VERSION "AgOpen Rate CAN ECU runtime DBC with S0-S3 banks, 16 nodes"

NS_ :

BS_:

BU_: MASTER TOOL NODE1 NODE2 NODE3 NODE4 NODE5 NODE6 NODE7 NODE8 NODE9 NODE10 NODE11 NODE12 NODE13 NODE14 NODE15 NODE16

VAL_TABLE_ VT_system_mode 0 "OFF" 1 "MANUAL" 2 "AUTO" 3 "CALIBRATION" 4 "FAULT_HOLD";
VAL_TABLE_ VT_node_command 0 "NOP" 1 "ENABLE" 2 "DISABLE" 3 "ZERO_POS" 4 "CLEAR_FAULT";

BO_ 128 S0_GLOBAL_CONTROL: 8 MASTER
 SG_ system_mode : 0|8@1+ (1,0) [0|255] ""  MASTER,TOOL
 SG_ control_flags : 8|8@1+ (1,0) [0|255] "bitfield"  MASTER,TOOL
 SG_ ctrl_drive_enable : 8|1@1+ (1,0) [0|1] "bool"  MASTER,TOOL
 SG_ ctrl_sync_enable : 9|1@1+ (1,0) [0|1] "bool"  MASTER,TOOL
 SG_ ctrl_estop : 10|1@1+ (1,0) [0|1] "bool"  MASTER,TOOL
 SG_ ctrl_diag_enable : 11|1@1+ (1,0) [0|1] "bool"  MASTER,TOOL
 SG_ base_rpm : 16|16@1+ (1,0) [0|10000] "rpm"  MASTER,TOOL
 SG_ sync_pos : 32|16@1+ (1.52587890625e-05,0) [0|0.9999847412109375] "rev"  MASTER,TOOL
 SG_ sequence : 48|8@1+ (1,0) [0|255] ""  MASTER,TOOL
 SG_ reserved : 56|8@1+ (1,0) [0|255] ""  MASTER,TOOL

BO_ 257 S0_NODE_CMD_1: 8 MASTER
 SG_ node_command : 0|8@1+ (1,0) [0|255] ""  MASTER,TOOL
 SG_ node_flags : 8|8@1+ (1,0) [0|255] "bitfield"  MASTER,TOOL
 SG_ trim_rpm : 16|16@1- (0.1,0) [-3276.8|3276.7] "rpm"  MASTER,TOOL
 SG_ section_mask : 32|16@1+ (1,0) [0|65535] "bitmask"  MASTER,TOOL
 SG_ seq : 48|8@1+ (1,0) [0|255] ""  MASTER,TOOL
 SG_ reserved : 56|8@1+ (1,0) [0|255] ""  MASTER,TOOL

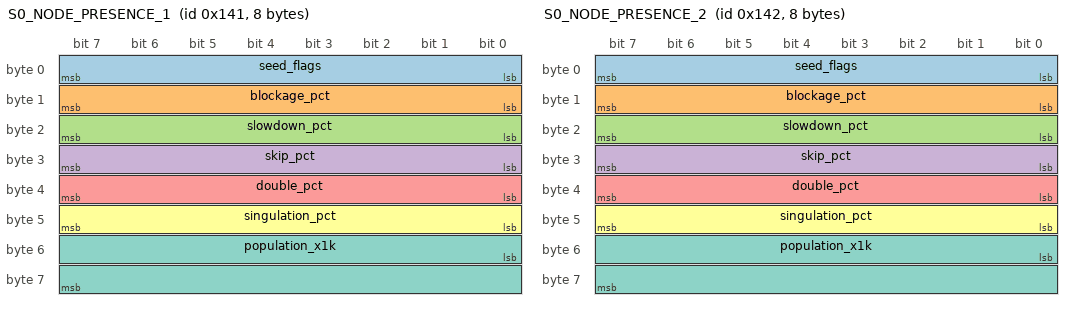
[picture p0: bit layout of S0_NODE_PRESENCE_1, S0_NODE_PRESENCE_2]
BO_ 321 S0_NODE_PRESENCE_1: 8 NODE1
 SG_ seed_flags : 0|8@1+ (1,0) [0|255] "bitfield"  NODE1,MASTER,TOOL
 SG_ blockage_pct : 8|8@1+ (1,0) [0|100] "%"  NODE1,MASTER,TOOL
 SG_ slowdown_pct : 16|8@1+ (1,0) [0|100] "%"  NODE1,MASTER,TOOL
 SG_ skip_pct : 24|8@1+ (1,0) [0|100] "%"  NODE1,MASTER,TOOL
 SG_ double_pct : 32|8@1+ (1,0) [0|100] "%"  NODE1,MASTER,TOOL
 SG_ singulation_pct : 40|8@1+ (1,0) [0|100] "%"  NODE1,MASTER,TOOL
 SG_ population_x1k : 48|16@1+ (1,0) [0|65535] "x1000"  NODE1,MASTER,TOOL

BO_ 385 S0_NODE_STATUS_FAST_1: 8 NODE1
 SG_ status_flags : 0|8@1+ (1,0) [0|255] "bitfield"  NODE1,MASTER,TOOL
 SG_ error_code : 8|8@1+ (1,0) [0|255] ""  NODE1,MASTER,TOOL
 SG_ actual_rpm : 16|16@1+ (1,0) [0|10000] "rpm"  NODE1,MASTER,TOOL
 SG_ actual_pos : 32|16@1+ (1.52587890625e-05,0) [0|0.9999847412109375] "rev"  NODE1,MASTER,TOOL
 SG_ alive_counter : 48|8@1+ (1,0) [0|255] ""  NODE1,MASTER,TOOL
 SG_ sync_error : 56|8@1- (0.00390625,0) [-0.5|0.49609375] "rev"  NODE1,MASTER,TOOL

BO_ 449 S0_NODE_DIAG_1: 8 NODE1
 SG_ bus_voltage : 0|16@1+ (0.1,0) [0|6553.5] "V"  NODE1,MASTER,TOOL
 SG_ motor_current : 16|16@1- (0.1,0) [-3276.8|3276.7] "A"  NODE1,MASTER,TOOL
 SG_ controller_temp : 32|8@1+ (1,0) [0|255] "C"  NODE1,MASTER,TOOL
 SG_ motor_temp : 40|8@1+ (1,0) [0|255] "C"  NODE1,MASTER,TOOL
 SG_ fault_flags : 48|8@1+ (1,0) [0|255] "bitfield"  NODE1,MASTER,TOOL
 SG_ warning_flags : 56|8@1+ (1,0) [0|255] "bitfield"  NODE1,MASTER,TOOL

BO_ 258 S0_NODE_CMD_2: 8 MASTER
 SG_ node_command : 0|8@1+ (1,0) [0|255] ""  MASTER,TOOL
 SG_ node_flags : 8|8@1+ (1,0) [0|255] "bitfield"  MASTER,TOOL
 SG_ trim_rpm : 16|16@1- (0.1,0) [-3276.8|3276.7] "rpm"  MASTER,TOOL
 SG_ section_mask : 32|16@1+ (1,0) [0|65535] "bitmask"  MASTER,TOOL
 SG_ seq : 48|8@1+ (1,0) [0|255] ""  MASTER,TOOL
 SG_ reserved : 56|8@1+ (1,0) [0|255] ""  MASTER,TOOL

BO_ 322 S0_NODE_PRESENCE_2: 8 NODE2
 SG_ seed_flags : 0|8@1+ (1,0) [0|255] "bitfield"  NODE2,MASTER,TOOL
 SG_ blockage_pct : 8|8@1+ (1,0) [0|100] "%"  NODE2,MASTER,TOOL
 SG_ slowdown_pct : 16|8@1+ (1,0) [0|100] "%"  NODE2,MASTER,TOOL
 SG_ skip_pct : 24|8@1+ (1,0) [0|100] "%"  NODE2,MASTER,TOOL
 SG_ double_pct : 32|8@1+ (1,0) [0|100] "%"  NODE2,MASTER,TOOL
 SG_ singulation_pct : 40|8@1+ (1,0) [0|100] "%"  NODE2,MASTER,TOOL
 SG_ population_x1k : 48|16@1+ (1,0) [0|65535] "x1000"  NODE2,MASTER,TOOL

BO_ 386 S0_NODE_STATUS_FAST_2: 8 NODE2
 SG_ status_flags : 0|8@1+ (1,0) [0|255] "bitfield"  NODE2,MASTER,TOOL
 SG_ error_code : 8|8@1+ (1,0) [0|255] ""  NODE2,MASTER,TOOL
 SG_ actual_rpm : 16|16@1+ (1,0) [0|10000] "rpm"  NODE2,MASTER,TOOL
 SG_ actual_pos : 32|16@1+ (1.52587890625e-05,0) [0|0.9999847412109375] "rev"  NODE2,MASTER,TOOL
 SG_ alive_counter : 48|8@1+ (1,0) [0|255] ""  NODE2,MASTER,TOOL
 SG_ sync_error : 56|8@1- (0.00390625,0) [-0.5|0.49609375] "rev"  NODE2,MASTER,TOOL

BO_ 450 S0_NODE_DIAG_2: 8 NODE2
 SG_ bus_voltage : 0|16@1+ (0.1,0) [0|6553.5] "V"  NODE2,MASTER,TOOL
 SG_ motor_current : 16|16@1- (0.1,0) [-3276.8|3276.7] "A"  NODE2,MASTER,TOOL
 SG_ controller_temp : 32|8@1+ (1,0) [0|255] "C"  NODE2,MASTER,TOOL
 SG_ motor_temp : 40|8@1+ (1,0) [0|255] "C"  NODE2,MASTER,TOOL
 SG_ fault_flags : 48|8@1+ (1,0) [0|255] "bitfield"  NODE2,MASTER,TOOL
 SG_ warning_flags : 56|8@1+ (1,0) [0|255] "bitfield"  NODE2,MASTER,TOOL

BO_ 259 S0_NODE_CMD_3: 8 MASTER
 SG_ node_command : 0|8@1+ (1,0) [0|255] ""  MASTER,TOOL
 SG_ node_flags : 8|8@1+ (1,0) [0|255] "bitfield"  MASTER,TOOL
 SG_ trim_rpm : 16|16@1- (0.1,0) [-3276.8|3276.7] "rpm"  MASTER,TOOL
 SG_ section_mask : 32|16@1+ (1,0) [0|65535] "bitmask"  MASTER,TOOL
 SG_ seq : 48|8@1+ (1,0) [0|255] ""  MASTER,TOOL
 SG_ reserved : 56|8@1+ (1,0) [0|255] ""  MASTER,TOOL

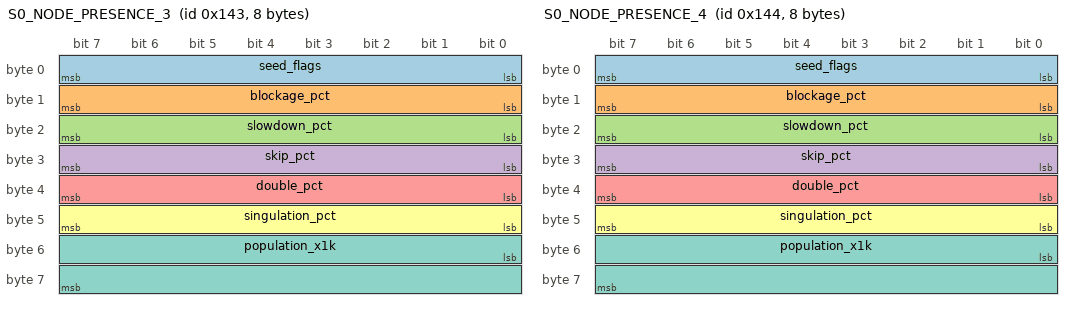
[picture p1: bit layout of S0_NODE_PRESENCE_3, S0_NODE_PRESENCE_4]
BO_ 323 S0_NODE_PRESENCE_3: 8 NODE3
 SG_ seed_flags : 0|8@1+ (1,0) [0|255] "bitfield"  NODE3,MASTER,TOOL
 SG_ blockage_pct : 8|8@1+ (1,0) [0|100] "%"  NODE3,MASTER,TOOL
 SG_ slowdown_pct : 16|8@1+ (1,0) [0|100] "%"  NODE3,MASTER,TOOL
 SG_ skip_pct : 24|8@1+ (1,0) [0|100] "%"  NODE3,MASTER,TOOL
 SG_ double_pct : 32|8@1+ (1,0) [0|100] "%"  NODE3,MASTER,TOOL
 SG_ singulation_pct : 40|8@1+ (1,0) [0|100] "%"  NODE3,MASTER,TOOL
 SG_ population_x1k : 48|16@1+ (1,0) [0|65535] "x1000"  NODE3,MASTER,TOOL

BO_ 387 S0_NODE_STATUS_FAST_3: 8 NODE3
 SG_ status_flags : 0|8@1+ (1,0) [0|255] "bitfield"  NODE3,MASTER,TOOL
 SG_ error_code : 8|8@1+ (1,0) [0|255] ""  NODE3,MASTER,TOOL
 SG_ actual_rpm : 16|16@1+ (1,0) [0|10000] "rpm"  NODE3,MASTER,TOOL
 SG_ actual_pos : 32|16@1+ (1.52587890625e-05,0) [0|0.9999847412109375] "rev"  NODE3,MASTER,TOOL
 SG_ alive_counter : 48|8@1+ (1,0) [0|255] ""  NODE3,MASTER,TOOL
 SG_ sync_error : 56|8@1- (0.00390625,0) [-0.5|0.49609375] "rev"  NODE3,MASTER,TOOL

BO_ 451 S0_NODE_DIAG_3: 8 NODE3
 SG_ bus_voltage : 0|16@1+ (0.1,0) [0|6553.5] "V"  NODE3,MASTER,TOOL
 SG_ motor_current : 16|16@1- (0.1,0) [-3276.8|3276.7] "A"  NODE3,MASTER,TOOL
 SG_ controller_temp : 32|8@1+ (1,0) [0|255] "C"  NODE3,MASTER,TOOL
 SG_ motor_temp : 40|8@1+ (1,0) [0|255] "C"  NODE3,MASTER,TOOL
 SG_ fault_flags : 48|8@1+ (1,0) [0|255] "bitfield"  NODE3,MASTER,TOOL
 SG_ warning_flags : 56|8@1+ (1,0) [0|255] "bitfield"  NODE3,MASTER,TOOL

BO_ 260 S0_NODE_CMD_4: 8 MASTER
 SG_ node_command : 0|8@1+ (1,0) [0|255] ""  MASTER,TOOL
 SG_ node_flags : 8|8@1+ (1,0) [0|255] "bitfield"  MASTER,TOOL
 SG_ trim_rpm : 16|16@1- (0.1,0) [-3276.8|3276.7] "rpm"  MASTER,TOOL
 SG_ section_mask : 32|16@1+ (1,0) [0|65535] "bitmask"  MASTER,TOOL
 SG_ seq : 48|8@1+ (1,0) [0|255] ""  MASTER,TOOL
 SG_ reserved : 56|8@1+ (1,0) [0|255] ""  MASTER,TOOL

BO_ 324 S0_NODE_PRESENCE_4: 8 NODE4
 SG_ seed_flags : 0|8@1+ (1,0) [0|255] "bitfield"  NODE4,MASTER,TOOL
 SG_ blockage_pct : 8|8@1+ (1,0) [0|100] "%"  NODE4,MASTER,TOOL
 SG_ slowdown_pct : 16|8@1+ (1,0) [0|100] "%"  NODE4,MASTER,TOOL
 SG_ skip_pct : 24|8@1+ (1,0) [0|100] "%"  NODE4,MASTER,TOOL
 SG_ double_pct : 32|8@1+ (1,0) [0|100] "%"  NODE4,MASTER,TOOL
 SG_ singulation_pct : 40|8@1+ (1,0) [0|100] "%"  NODE4,MASTER,TOOL
 SG_ population_x1k : 48|16@1+ (1,0) [0|65535] "x1000"  NODE4,MASTER,TOOL

BO_ 388 S0_NODE_STATUS_FAST_4: 8 NODE4
 SG_ status_flags : 0|8@1+ (1,0) [0|255] "bitfield"  NODE4,MASTER,TOOL
 SG_ error_code : 8|8@1+ (1,0) [0|255] ""  NODE4,MASTER,TOOL
 SG_ actual_rpm : 16|16@1+ (1,0) [0|10000] "rpm"  NODE4,MASTER,TOOL
 SG_ actual_pos : 32|16@1+ (1.52587890625e-05,0) [0|0.9999847412109375] "rev"  NODE4,MASTER,TOOL
 SG_ alive_counter : 48|8@1+ (1,0) [0|255] ""  NODE4,MASTER,TOOL
 SG_ sync_error : 56|8@1- (0.00390625,0) [-0.5|0.49609375] "rev"  NODE4,MASTER,TOOL

BO_ 452 S0_NODE_DIAG_4: 8 NODE4
 SG_ bus_voltage : 0|16@1+ (0.1,0) [0|6553.5] "V"  NODE4,MASTER,TOOL
 SG_ motor_current : 16|16@1- (0.1,0) [-3276.8|3276.7] "A"  NODE4,MASTER,TOOL
 SG_ controller_temp : 32|8@1+ (1,0) [0|255] "C"  NODE4,MASTER,TOOL
 SG_ motor_temp : 40|8@1+ (1,0) [0|255] "C"  NODE4,MASTER,TOOL
 SG_ fault_flags : 48|8@1+ (1,0) [0|255] "bitfield"  NODE4,MASTER,TOOL
 SG_ warning_flags : 56|8@1+ (1,0) [0|255] "bitfield"  NODE4,MASTER,TOOL

BO_ 261 S0_NODE_CMD_5: 8 MASTER
 SG_ node_command : 0|8@1+ (1,0) [0|255] ""  MASTER,TOOL
 SG_ node_flags : 8|8@1+ (1,0) [0|255] "bitfield"  MASTER,TOOL
 SG_ trim_rpm : 16|16@1- (0.1,0) [-3276.8|3276.7] "rpm"  MASTER,TOOL
 SG_ section_mask : 32|16@1+ (1,0) [0|65535] "bitmask"  MASTER,TOOL
 SG_ seq : 48|8@1+ (1,0) [0|255] ""  MASTER,TOOL
 SG_ reserved : 56|8@1+ (1,0) [0|255] ""  MASTER,TOOL

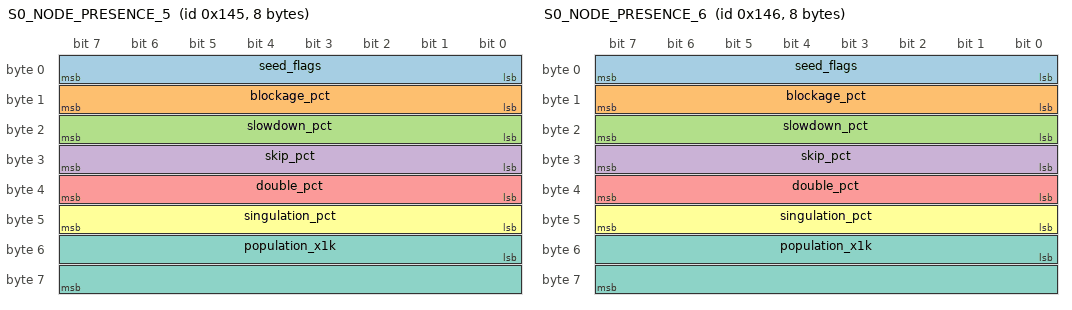
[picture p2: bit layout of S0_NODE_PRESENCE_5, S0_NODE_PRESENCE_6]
BO_ 325 S0_NODE_PRESENCE_5: 8 NODE5
 SG_ seed_flags : 0|8@1+ (1,0) [0|255] "bitfield"  NODE5,MASTER,TOOL
 SG_ blockage_pct : 8|8@1+ (1,0) [0|100] "%"  NODE5,MASTER,TOOL
 SG_ slowdown_pct : 16|8@1+ (1,0) [0|100] "%"  NODE5,MASTER,TOOL
 SG_ skip_pct : 24|8@1+ (1,0) [0|100] "%"  NODE5,MASTER,TOOL
 SG_ double_pct : 32|8@1+ (1,0) [0|100] "%"  NODE5,MASTER,TOOL
 SG_ singulation_pct : 40|8@1+ (1,0) [0|100] "%"  NODE5,MASTER,TOOL
 SG_ population_x1k : 48|16@1+ (1,0) [0|65535] "x1000"  NODE5,MASTER,TOOL

BO_ 389 S0_NODE_STATUS_FAST_5: 8 NODE5
 SG_ status_flags : 0|8@1+ (1,0) [0|255] "bitfield"  NODE5,MASTER,TOOL
 SG_ error_code : 8|8@1+ (1,0) [0|255] ""  NODE5,MASTER,TOOL
 SG_ actual_rpm : 16|16@1+ (1,0) [0|10000] "rpm"  NODE5,MASTER,TOOL
 SG_ actual_pos : 32|16@1+ (1.52587890625e-05,0) [0|0.9999847412109375] "rev"  NODE5,MASTER,TOOL
 SG_ alive_counter : 48|8@1+ (1,0) [0|255] ""  NODE5,MASTER,TOOL
 SG_ sync_error : 56|8@1- (0.00390625,0) [-0.5|0.49609375] "rev"  NODE5,MASTER,TOOL

BO_ 453 S0_NODE_DIAG_5: 8 NODE5
 SG_ bus_voltage : 0|16@1+ (0.1,0) [0|6553.5] "V"  NODE5,MASTER,TOOL
 SG_ motor_current : 16|16@1- (0.1,0) [-3276.8|3276.7] "A"  NODE5,MASTER,TOOL
 SG_ controller_temp : 32|8@1+ (1,0) [0|255] "C"  NODE5,MASTER,TOOL
 SG_ motor_temp : 40|8@1+ (1,0) [0|255] "C"  NODE5,MASTER,TOOL
 SG_ fault_flags : 48|8@1+ (1,0) [0|255] "bitfield"  NODE5,MASTER,TOOL
 SG_ warning_flags : 56|8@1+ (1,0) [0|255] "bitfield"  NODE5,MASTER,TOOL

BO_ 262 S0_NODE_CMD_6: 8 MASTER
 SG_ node_command : 0|8@1+ (1,0) [0|255] ""  MASTER,TOOL
 SG_ node_flags : 8|8@1+ (1,0) [0|255] "bitfield"  MASTER,TOOL
 SG_ trim_rpm : 16|16@1- (0.1,0) [-3276.8|3276.7] "rpm"  MASTER,TOOL
 SG_ section_mask : 32|16@1+ (1,0) [0|65535] "bitmask"  MASTER,TOOL
 SG_ seq : 48|8@1+ (1,0) [0|255] ""  MASTER,TOOL
 SG_ reserved : 56|8@1+ (1,0) [0|255] ""  MASTER,TOOL

BO_ 326 S0_NODE_PRESENCE_6: 8 NODE6
 SG_ seed_flags : 0|8@1+ (1,0) [0|255] "bitfield"  NODE6,MASTER,TOOL
 SG_ blockage_pct : 8|8@1+ (1,0) [0|100] "%"  NODE6,MASTER,TOOL
 SG_ slowdown_pct : 16|8@1+ (1,0) [0|100] "%"  NODE6,MASTER,TOOL
 SG_ skip_pct : 24|8@1+ (1,0) [0|100] "%"  NODE6,MASTER,TOOL
 SG_ double_pct : 32|8@1+ (1,0) [0|100] "%"  NODE6,MASTER,TOOL
 SG_ singulation_pct : 40|8@1+ (1,0) [0|100] "%"  NODE6,MASTER,TOOL
 SG_ population_x1k : 48|16@1+ (1,0) [0|65535] "x1000"  NODE6,MASTER,TOOL

BO_ 390 S0_NODE_STATUS_FAST_6: 8 NODE6
 SG_ status_flags : 0|8@1+ (1,0) [0|255] "bitfield"  NODE6,MASTER,TOOL
 SG_ error_code : 8|8@1+ (1,0) [0|255] ""  NODE6,MASTER,TOOL
 SG_ actual_rpm : 16|16@1+ (1,0) [0|10000] "rpm"  NODE6,MASTER,TOOL
 SG_ actual_pos : 32|16@1+ (1.52587890625e-05,0) [0|0.9999847412109375] "rev"  NODE6,MASTER,TOOL
 SG_ alive_counter : 48|8@1+ (1,0) [0|255] ""  NODE6,MASTER,TOOL
 SG_ sync_error : 56|8@1- (0.00390625,0) [-0.5|0.49609375] "rev"  NODE6,MASTER,TOOL

BO_ 454 S0_NODE_DIAG_6: 8 NODE6
 SG_ bus_voltage : 0|16@1+ (0.1,0) [0|6553.5] "V"  NODE6,MASTER,TOOL
 SG_ motor_current : 16|16@1- (0.1,0) [-3276.8|3276.7] "A"  NODE6,MASTER,TOOL
 SG_ controller_temp : 32|8@1+ (1,0) [0|255] "C"  NODE6,MASTER,TOOL
 SG_ motor_temp : 40|8@1+ (1,0) [0|255] "C"  NODE6,MASTER,TOOL
 SG_ fault_flags : 48|8@1+ (1,0) [0|255] "bitfield"  NODE6,MASTER,TOOL
 SG_ warning_flags : 56|8@1+ (1,0) [0|255] "bitfield"  NODE6,MASTER,TOOL

BO_ 263 S0_NODE_CMD_7: 8 MASTER
 SG_ node_command : 0|8@1+ (1,0) [0|255] ""  MASTER,TOOL
 SG_ node_flags : 8|8@1+ (1,0) [0|255] "bitfield"  MASTER,TOOL
 SG_ trim_rpm : 16|16@1- (0.1,0) [-3276.8|3276.7] "rpm"  MASTER,TOOL
 SG_ section_mask : 32|16@1+ (1,0) [0|65535] "bitmask"  MASTER,TOOL
 SG_ seq : 48|8@1+ (1,0) [0|255] ""  MASTER,TOOL
 SG_ reserved : 56|8@1+ (1,0) [0|255] ""  MASTER,TOOL

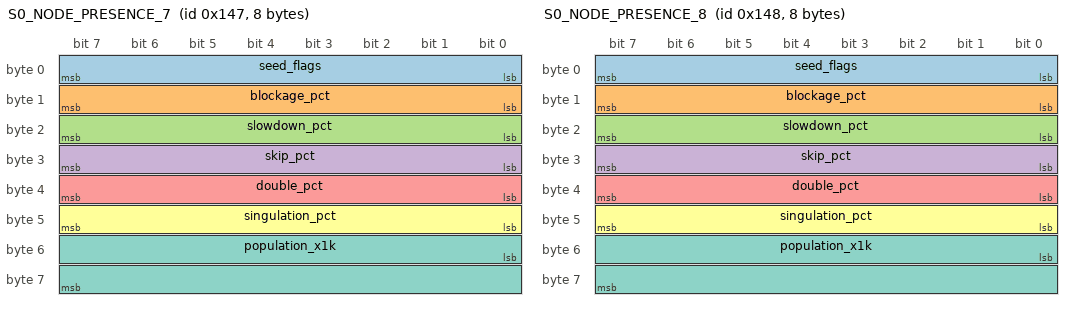
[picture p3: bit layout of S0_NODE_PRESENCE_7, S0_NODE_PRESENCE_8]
BO_ 327 S0_NODE_PRESENCE_7: 8 NODE7
 SG_ seed_flags : 0|8@1+ (1,0) [0|255] "bitfield"  NODE7,MASTER,TOOL
 SG_ blockage_pct : 8|8@1+ (1,0) [0|100] "%"  NODE7,MASTER,TOOL
 SG_ slowdown_pct : 16|8@1+ (1,0) [0|100] "%"  NODE7,MASTER,TOOL
 SG_ skip_pct : 24|8@1+ (1,0) [0|100] "%"  NODE7,MASTER,TOOL
 SG_ double_pct : 32|8@1+ (1,0) [0|100] "%"  NODE7,MASTER,TOOL
 SG_ singulation_pct : 40|8@1+ (1,0) [0|100] "%"  NODE7,MASTER,TOOL
 SG_ population_x1k : 48|16@1+ (1,0) [0|65535] "x1000"  NODE7,MASTER,TOOL

BO_ 391 S0_NODE_STATUS_FAST_7: 8 NODE7
 SG_ status_flags : 0|8@1+ (1,0) [0|255] "bitfield"  NODE7,MASTER,TOOL
 SG_ error_code : 8|8@1+ (1,0) [0|255] ""  NODE7,MASTER,TOOL
 SG_ actual_rpm : 16|16@1+ (1,0) [0|10000] "rpm"  NODE7,MASTER,TOOL
 SG_ actual_pos : 32|16@1+ (1.52587890625e-05,0) [0|0.9999847412109375] "rev"  NODE7,MASTER,TOOL
 SG_ alive_counter : 48|8@1+ (1,0) [0|255] ""  NODE7,MASTER,TOOL
 SG_ sync_error : 56|8@1- (0.00390625,0) [-0.5|0.49609375] "rev"  NODE7,MASTER,TOOL

BO_ 455 S0_NODE_DIAG_7: 8 NODE7
 SG_ bus_voltage : 0|16@1+ (0.1,0) [0|6553.5] "V"  NODE7,MASTER,TOOL
 SG_ motor_current : 16|16@1- (0.1,0) [-3276.8|3276.7] "A"  NODE7,MASTER,TOOL
 SG_ controller_temp : 32|8@1+ (1,0) [0|255] "C"  NODE7,MASTER,TOOL
 SG_ motor_temp : 40|8@1+ (1,0) [0|255] "C"  NODE7,MASTER,TOOL
 SG_ fault_flags : 48|8@1+ (1,0) [0|255] "bitfield"  NODE7,MASTER,TOOL
 SG_ warning_flags : 56|8@1+ (1,0) [0|255] "bitfield"  NODE7,MASTER,TOOL

BO_ 264 S0_NODE_CMD_8: 8 MASTER
 SG_ node_command : 0|8@1+ (1,0) [0|255] ""  MASTER,TOOL
 SG_ node_flags : 8|8@1+ (1,0) [0|255] "bitfield"  MASTER,TOOL
 SG_ trim_rpm : 16|16@1- (0.1,0) [-3276.8|3276.7] "rpm"  MASTER,TOOL
 SG_ section_mask : 32|16@1+ (1,0) [0|65535] "bitmask"  MASTER,TOOL
 SG_ seq : 48|8@1+ (1,0) [0|255] ""  MASTER,TOOL
 SG_ reserved : 56|8@1+ (1,0) [0|255] ""  MASTER,TOOL

BO_ 328 S0_NODE_PRESENCE_8: 8 NODE8
 SG_ seed_flags : 0|8@1+ (1,0) [0|255] "bitfield"  NODE8,MASTER,TOOL
 SG_ blockage_pct : 8|8@1+ (1,0) [0|100] "%"  NODE8,MASTER,TOOL
 SG_ slowdown_pct : 16|8@1+ (1,0) [0|100] "%"  NODE8,MASTER,TOOL
 SG_ skip_pct : 24|8@1+ (1,0) [0|100] "%"  NODE8,MASTER,TOOL
 SG_ double_pct : 32|8@1+ (1,0) [0|100] "%"  NODE8,MASTER,TOOL
 SG_ singulation_pct : 40|8@1+ (1,0) [0|100] "%"  NODE8,MASTER,TOOL
 SG_ population_x1k : 48|16@1+ (1,0) [0|65535] "x1000"  NODE8,MASTER,TOOL

BO_ 392 S0_NODE_STATUS_FAST_8: 8 NODE8
 SG_ status_flags : 0|8@1+ (1,0) [0|255] "bitfield"  NODE8,MASTER,TOOL
 SG_ error_code : 8|8@1+ (1,0) [0|255] ""  NODE8,MASTER,TOOL
 SG_ actual_rpm : 16|16@1+ (1,0) [0|10000] "rpm"  NODE8,MASTER,TOOL
 SG_ actual_pos : 32|16@1+ (1.52587890625e-05,0) [0|0.9999847412109375] "rev"  NODE8,MASTER,TOOL
 SG_ alive_counter : 48|8@1+ (1,0) [0|255] ""  NODE8,MASTER,TOOL
 SG_ sync_error : 56|8@1- (0.00390625,0) [-0.5|0.49609375] "rev"  NODE8,MASTER,TOOL

BO_ 456 S0_NODE_DIAG_8: 8 NODE8
 SG_ bus_voltage : 0|16@1+ (0.1,0) [0|6553.5] "V"  NODE8,MASTER,TOOL
 SG_ motor_current : 16|16@1- (0.1,0) [-3276.8|3276.7] "A"  NODE8,MASTER,TOOL
 SG_ controller_temp : 32|8@1+ (1,0) [0|255] "C"  NODE8,MASTER,TOOL
 SG_ motor_temp : 40|8@1+ (1,0) [0|255] "C"  NODE8,MASTER,TOOL
 SG_ fault_flags : 48|8@1+ (1,0) [0|255] "bitfield"  NODE8,MASTER,TOOL
 SG_ warning_flags : 56|8@1+ (1,0) [0|255] "bitfield"  NODE8,MASTER,TOOL

BO_ 265 S0_NODE_CMD_9: 8 MASTER
 SG_ node_command : 0|8@1+ (1,0) [0|255] ""  MASTER,TOOL
 SG_ node_flags : 8|8@1+ (1,0) [0|255] "bitfield"  MASTER,TOOL
 SG_ trim_rpm : 16|16@1- (0.1,0) [-3276.8|3276.7] "rpm"  MASTER,TOOL
 SG_ section_mask : 32|16@1+ (1,0) [0|65535] "bitmask"  MASTER,TOOL
 SG_ seq : 48|8@1+ (1,0) [0|255] ""  MASTER,TOOL
 SG_ reserved : 56|8@1+ (1,0) [0|255] ""  MASTER,TOOL

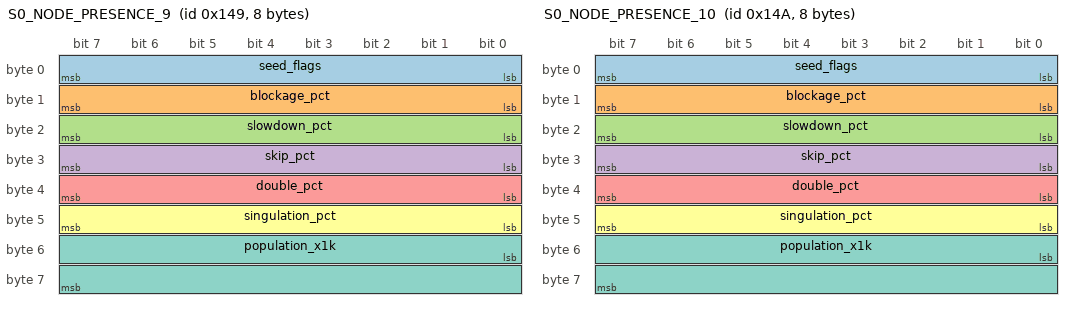
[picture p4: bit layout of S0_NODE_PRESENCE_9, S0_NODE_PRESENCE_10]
BO_ 329 S0_NODE_PRESENCE_9: 8 NODE9
 SG_ seed_flags : 0|8@1+ (1,0) [0|255] "bitfield"  NODE9,MASTER,TOOL
 SG_ blockage_pct : 8|8@1+ (1,0) [0|100] "%"  NODE9,MASTER,TOOL
 SG_ slowdown_pct : 16|8@1+ (1,0) [0|100] "%"  NODE9,MASTER,TOOL
 SG_ skip_pct : 24|8@1+ (1,0) [0|100] "%"  NODE9,MASTER,TOOL
 SG_ double_pct : 32|8@1+ (1,0) [0|100] "%"  NODE9,MASTER,TOOL
 SG_ singulation_pct : 40|8@1+ (1,0) [0|100] "%"  NODE9,MASTER,TOOL
 SG_ population_x1k : 48|16@1+ (1,0) [0|65535] "x1000"  NODE9,MASTER,TOOL

BO_ 393 S0_NODE_STATUS_FAST_9: 8 NODE9
 SG_ status_flags : 0|8@1+ (1,0) [0|255] "bitfield"  NODE9,MASTER,TOOL
 SG_ error_code : 8|8@1+ (1,0) [0|255] ""  NODE9,MASTER,TOOL
 SG_ actual_rpm : 16|16@1+ (1,0) [0|10000] "rpm"  NODE9,MASTER,TOOL
 SG_ actual_pos : 32|16@1+ (1.52587890625e-05,0) [0|0.9999847412109375] "rev"  NODE9,MASTER,TOOL
 SG_ alive_counter : 48|8@1+ (1,0) [0|255] ""  NODE9,MASTER,TOOL
 SG_ sync_error : 56|8@1- (0.00390625,0) [-0.5|0.49609375] "rev"  NODE9,MASTER,TOOL

BO_ 457 S0_NODE_DIAG_9: 8 NODE9
 SG_ bus_voltage : 0|16@1+ (0.1,0) [0|6553.5] "V"  NODE9,MASTER,TOOL
 SG_ motor_current : 16|16@1- (0.1,0) [-3276.8|3276.7] "A"  NODE9,MASTER,TOOL
 SG_ controller_temp : 32|8@1+ (1,0) [0|255] "C"  NODE9,MASTER,TOOL
 SG_ motor_temp : 40|8@1+ (1,0) [0|255] "C"  NODE9,MASTER,TOOL
 SG_ fault_flags : 48|8@1+ (1,0) [0|255] "bitfield"  NODE9,MASTER,TOOL
 SG_ warning_flags : 56|8@1+ (1,0) [0|255] "bitfield"  NODE9,MASTER,TOOL

BO_ 266 S0_NODE_CMD_10: 8 MASTER
 SG_ node_command : 0|8@1+ (1,0) [0|255] ""  MASTER,TOOL
 SG_ node_flags : 8|8@1+ (1,0) [0|255] "bitfield"  MASTER,TOOL
 SG_ trim_rpm : 16|16@1- (0.1,0) [-3276.8|3276.7] "rpm"  MASTER,TOOL
 SG_ section_mask : 32|16@1+ (1,0) [0|65535] "bitmask"  MASTER,TOOL
 SG_ seq : 48|8@1+ (1,0) [0|255] ""  MASTER,TOOL
 SG_ reserved : 56|8@1+ (1,0) [0|255] ""  MASTER,TOOL

BO_ 330 S0_NODE_PRESENCE_10: 8 NODE10
 SG_ seed_flags : 0|8@1+ (1,0) [0|255] "bitfield"  NODE10,MASTER,TOOL
 SG_ blockage_pct : 8|8@1+ (1,0) [0|100] "%"  NODE10,MASTER,TOOL
 SG_ slowdown_pct : 16|8@1+ (1,0) [0|100] "%"  NODE10,MASTER,TOOL
 SG_ skip_pct : 24|8@1+ (1,0) [0|100] "%"  NODE10,MASTER,TOOL
 SG_ double_pct : 32|8@1+ (1,0) [0|100] "%"  NODE10,MASTER,TOOL
 SG_ singulation_pct : 40|8@1+ (1,0) [0|100] "%"  NODE10,MASTER,TOOL
 SG_ population_x1k : 48|16@1+ (1,0) [0|65535] "x1000"  NODE10,MASTER,TOOL

BO_ 394 S0_NODE_STATUS_FAST_10: 8 NODE10
 SG_ status_flags : 0|8@1+ (1,0) [0|255] "bitfield"  NODE10,MASTER,TOOL
 SG_ error_code : 8|8@1+ (1,0) [0|255] ""  NODE10,MASTER,TOOL
 SG_ actual_rpm : 16|16@1+ (1,0) [0|10000] "rpm"  NODE10,MASTER,TOOL
 SG_ actual_pos : 32|16@1+ (1.52587890625e-05,0) [0|0.9999847412109375] "rev"  NODE10,MASTER,TOOL
 SG_ alive_counter : 48|8@1+ (1,0) [0|255] ""  NODE10,MASTER,TOOL
 SG_ sync_error : 56|8@1- (0.00390625,0) [-0.5|0.49609375] "rev"  NODE10,MASTER,TOOL

BO_ 458 S0_NODE_DIAG_10: 8 NODE10
 SG_ bus_voltage : 0|16@1+ (0.1,0) [0|6553.5] "V"  NODE10,MASTER,TOOL
 SG_ motor_current : 16|16@1- (0.1,0) [-3276.8|3276.7] "A"  NODE10,MASTER,TOOL
 SG_ controller_temp : 32|8@1+ (1,0) [0|255] "C"  NODE10,MASTER,TOOL
 SG_ motor_temp : 40|8@1+ (1,0) [0|255] "C"  NODE10,MASTER,TOOL
 SG_ fault_flags : 48|8@1+ (1,0) [0|255] "bitfield"  NODE10,MASTER,TOOL
 SG_ warning_flags : 56|8@1+ (1,0) [0|255] "bitfield"  NODE10,MASTER,TOOL

BO_ 267 S0_NODE_CMD_11: 8 MASTER
 SG_ node_command : 0|8@1+ (1,0) [0|255] ""  MASTER,TOOL
 SG_ node_flags : 8|8@1+ (1,0) [0|255] "bitfield"  MASTER,TOOL
 SG_ trim_rpm : 16|16@1- (0.1,0) [-3276.8|3276.7] "rpm"  MASTER,TOOL
 SG_ section_mask : 32|16@1+ (1,0) [0|65535] "bitmask"  MASTER,TOOL
 SG_ seq : 48|8@1+ (1,0) [0|255] ""  MASTER,TOOL
 SG_ reserved : 56|8@1+ (1,0) [0|255] ""  MASTER,TOOL

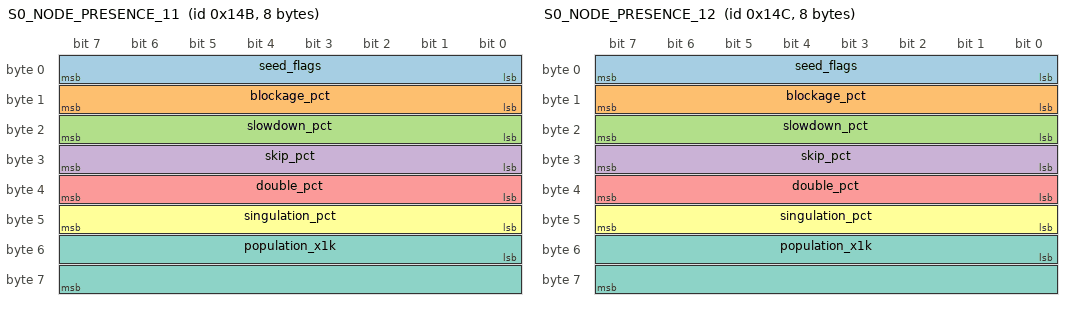
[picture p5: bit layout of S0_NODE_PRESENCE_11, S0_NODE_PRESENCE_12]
BO_ 331 S0_NODE_PRESENCE_11: 8 NODE11
 SG_ seed_flags : 0|8@1+ (1,0) [0|255] "bitfield"  NODE11,MASTER,TOOL
 SG_ blockage_pct : 8|8@1+ (1,0) [0|100] "%"  NODE11,MASTER,TOOL
 SG_ slowdown_pct : 16|8@1+ (1,0) [0|100] "%"  NODE11,MASTER,TOOL
 SG_ skip_pct : 24|8@1+ (1,0) [0|100] "%"  NODE11,MASTER,TOOL
 SG_ double_pct : 32|8@1+ (1,0) [0|100] "%"  NODE11,MASTER,TOOL
 SG_ singulation_pct : 40|8@1+ (1,0) [0|100] "%"  NODE11,MASTER,TOOL
 SG_ population_x1k : 48|16@1+ (1,0) [0|65535] "x1000"  NODE11,MASTER,TOOL

BO_ 395 S0_NODE_STATUS_FAST_11: 8 NODE11
 SG_ status_flags : 0|8@1+ (1,0) [0|255] "bitfield"  NODE11,MASTER,TOOL
 SG_ error_code : 8|8@1+ (1,0) [0|255] ""  NODE11,MASTER,TOOL
 SG_ actual_rpm : 16|16@1+ (1,0) [0|10000] "rpm"  NODE11,MASTER,TOOL
 SG_ actual_pos : 32|16@1+ (1.52587890625e-05,0) [0|0.9999847412109375] "rev"  NODE11,MASTER,TOOL
 SG_ alive_counter : 48|8@1+ (1,0) [0|255] ""  NODE11,MASTER,TOOL
 SG_ sync_error : 56|8@1- (0.00390625,0) [-0.5|0.49609375] "rev"  NODE11,MASTER,TOOL

BO_ 459 S0_NODE_DIAG_11: 8 NODE11
 SG_ bus_voltage : 0|16@1+ (0.1,0) [0|6553.5] "V"  NODE11,MASTER,TOOL
 SG_ motor_current : 16|16@1- (0.1,0) [-3276.8|3276.7] "A"  NODE11,MASTER,TOOL
 SG_ controller_temp : 32|8@1+ (1,0) [0|255] "C"  NODE11,MASTER,TOOL
 SG_ motor_temp : 40|8@1+ (1,0) [0|255] "C"  NODE11,MASTER,TOOL
 SG_ fault_flags : 48|8@1+ (1,0) [0|255] "bitfield"  NODE11,MASTER,TOOL
 SG_ warning_flags : 56|8@1+ (1,0) [0|255] "bitfield"  NODE11,MASTER,TOOL

BO_ 268 S0_NODE_CMD_12: 8 MASTER
 SG_ node_command : 0|8@1+ (1,0) [0|255] ""  MASTER,TOOL
 SG_ node_flags : 8|8@1+ (1,0) [0|255] "bitfield"  MASTER,TOOL
 SG_ trim_rpm : 16|16@1- (0.1,0) [-3276.8|3276.7] "rpm"  MASTER,TOOL
 SG_ section_mask : 32|16@1+ (1,0) [0|65535] "bitmask"  MASTER,TOOL
 SG_ seq : 48|8@1+ (1,0) [0|255] ""  MASTER,TOOL
 SG_ reserved : 56|8@1+ (1,0) [0|255] ""  MASTER,TOOL

BO_ 332 S0_NODE_PRESENCE_12: 8 NODE12
 SG_ seed_flags : 0|8@1+ (1,0) [0|255] "bitfield"  NODE12,MASTER,TOOL
 SG_ blockage_pct : 8|8@1+ (1,0) [0|100] "%"  NODE12,MASTER,TOOL
 SG_ slowdown_pct : 16|8@1+ (1,0) [0|100] "%"  NODE12,MASTER,TOOL
 SG_ skip_pct : 24|8@1+ (1,0) [0|100] "%"  NODE12,MASTER,TOOL
 SG_ double_pct : 32|8@1+ (1,0) [0|100] "%"  NODE12,MASTER,TOOL
 SG_ singulation_pct : 40|8@1+ (1,0) [0|100] "%"  NODE12,MASTER,TOOL
 SG_ population_x1k : 48|16@1+ (1,0) [0|65535] "x1000"  NODE12,MASTER,TOOL

BO_ 396 S0_NODE_STATUS_FAST_12: 8 NODE12
 SG_ status_flags : 0|8@1+ (1,0) [0|255] "bitfield"  NODE12,MASTER,TOOL
 SG_ error_code : 8|8@1+ (1,0) [0|255] ""  NODE12,MASTER,TOOL
 SG_ actual_rpm : 16|16@1+ (1,0) [0|10000] "rpm"  NODE12,MASTER,TOOL
 SG_ actual_pos : 32|16@1+ (1.52587890625e-05,0) [0|0.9999847412109375] "rev"  NODE12,MASTER,TOOL
 SG_ alive_counter : 48|8@1+ (1,0) [0|255] ""  NODE12,MASTER,TOOL
 SG_ sync_error : 56|8@1- (0.00390625,0) [-0.5|0.49609375] "rev"  NODE12,MASTER,TOOL

BO_ 460 S0_NODE_DIAG_12: 8 NODE12
 SG_ bus_voltage : 0|16@1+ (0.1,0) [0|6553.5] "V"  NODE12,MASTER,TOOL
 SG_ motor_current : 16|16@1- (0.1,0) [-3276.8|3276.7] "A"  NODE12,MASTER,TOOL
 SG_ controller_temp : 32|8@1+ (1,0) [0|255] "C"  NODE12,MASTER,TOOL
 SG_ motor_temp : 40|8@1+ (1,0) [0|255] "C"  NODE12,MASTER,TOOL
 SG_ fault_flags : 48|8@1+ (1,0) [0|255] "bitfield"  NODE12,MASTER,TOOL
 SG_ warning_flags : 56|8@1+ (1,0) [0|255] "bitfield"  NODE12,MASTER,TOOL

BO_ 269 S0_NODE_CMD_13: 8 MASTER
 SG_ node_command : 0|8@1+ (1,0) [0|255] ""  MASTER,TOOL
 SG_ node_flags : 8|8@1+ (1,0) [0|255] "bitfield"  MASTER,TOOL
 SG_ trim_rpm : 16|16@1- (0.1,0) [-3276.8|3276.7] "rpm"  MASTER,TOOL
 SG_ section_mask : 32|16@1+ (1,0) [0|65535] "bitmask"  MASTER,TOOL
 SG_ seq : 48|8@1+ (1,0) [0|255] ""  MASTER,TOOL
 SG_ reserved : 56|8@1+ (1,0) [0|255] ""  MASTER,TOOL

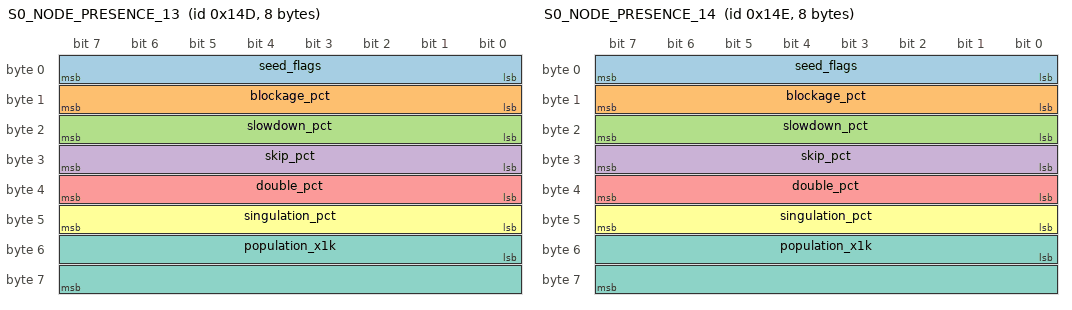
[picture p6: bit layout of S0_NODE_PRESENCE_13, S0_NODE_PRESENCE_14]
BO_ 333 S0_NODE_PRESENCE_13: 8 NODE13
 SG_ seed_flags : 0|8@1+ (1,0) [0|255] "bitfield"  NODE13,MASTER,TOOL
 SG_ blockage_pct : 8|8@1+ (1,0) [0|100] "%"  NODE13,MASTER,TOOL
 SG_ slowdown_pct : 16|8@1+ (1,0) [0|100] "%"  NODE13,MASTER,TOOL
 SG_ skip_pct : 24|8@1+ (1,0) [0|100] "%"  NODE13,MASTER,TOOL
 SG_ double_pct : 32|8@1+ (1,0) [0|100] "%"  NODE13,MASTER,TOOL
 SG_ singulation_pct : 40|8@1+ (1,0) [0|100] "%"  NODE13,MASTER,TOOL
 SG_ population_x1k : 48|16@1+ (1,0) [0|65535] "x1000"  NODE13,MASTER,TOOL

BO_ 397 S0_NODE_STATUS_FAST_13: 8 NODE13
 SG_ status_flags : 0|8@1+ (1,0) [0|255] "bitfield"  NODE13,MASTER,TOOL
 SG_ error_code : 8|8@1+ (1,0) [0|255] ""  NODE13,MASTER,TOOL
 SG_ actual_rpm : 16|16@1+ (1,0) [0|10000] "rpm"  NODE13,MASTER,TOOL
 SG_ actual_pos : 32|16@1+ (1.52587890625e-05,0) [0|0.9999847412109375] "rev"  NODE13,MASTER,TOOL
 SG_ alive_counter : 48|8@1+ (1,0) [0|255] ""  NODE13,MASTER,TOOL
 SG_ sync_error : 56|8@1- (0.00390625,0) [-0.5|0.49609375] "rev"  NODE13,MASTER,TOOL

BO_ 461 S0_NODE_DIAG_13: 8 NODE13
 SG_ bus_voltage : 0|16@1+ (0.1,0) [0|6553.5] "V"  NODE13,MASTER,TOOL
 SG_ motor_current : 16|16@1- (0.1,0) [-3276.8|3276.7] "A"  NODE13,MASTER,TOOL
 SG_ controller_temp : 32|8@1+ (1,0) [0|255] "C"  NODE13,MASTER,TOOL
 SG_ motor_temp : 40|8@1+ (1,0) [0|255] "C"  NODE13,MASTER,TOOL
 SG_ fault_flags : 48|8@1+ (1,0) [0|255] "bitfield"  NODE13,MASTER,TOOL
 SG_ warning_flags : 56|8@1+ (1,0) [0|255] "bitfield"  NODE13,MASTER,TOOL

BO_ 270 S0_NODE_CMD_14: 8 MASTER
 SG_ node_command : 0|8@1+ (1,0) [0|255] ""  MASTER,TOOL
 SG_ node_flags : 8|8@1+ (1,0) [0|255] "bitfield"  MASTER,TOOL
 SG_ trim_rpm : 16|16@1- (0.1,0) [-3276.8|3276.7] "rpm"  MASTER,TOOL
 SG_ section_mask : 32|16@1+ (1,0) [0|65535] "bitmask"  MASTER,TOOL
 SG_ seq : 48|8@1+ (1,0) [0|255] ""  MASTER,TOOL
 SG_ reserved : 56|8@1+ (1,0) [0|255] ""  MASTER,TOOL

BO_ 334 S0_NODE_PRESENCE_14: 8 NODE14
 SG_ seed_flags : 0|8@1+ (1,0) [0|255] "bitfield"  NODE14,MASTER,TOOL
 SG_ blockage_pct : 8|8@1+ (1,0) [0|100] "%"  NODE14,MASTER,TOOL
 SG_ slowdown_pct : 16|8@1+ (1,0) [0|100] "%"  NODE14,MASTER,TOOL
 SG_ skip_pct : 24|8@1+ (1,0) [0|100] "%"  NODE14,MASTER,TOOL
 SG_ double_pct : 32|8@1+ (1,0) [0|100] "%"  NODE14,MASTER,TOOL
 SG_ singulation_pct : 40|8@1+ (1,0) [0|100] "%"  NODE14,MASTER,TOOL
 SG_ population_x1k : 48|16@1+ (1,0) [0|65535] "x1000"  NODE14,MASTER,TOOL

BO_ 398 S0_NODE_STATUS_FAST_14: 8 NODE14
 SG_ status_flags : 0|8@1+ (1,0) [0|255] "bitfield"  NODE14,MASTER,TOOL
 SG_ error_code : 8|8@1+ (1,0) [0|255] ""  NODE14,MASTER,TOOL
 SG_ actual_rpm : 16|16@1+ (1,0) [0|10000] "rpm"  NODE14,MASTER,TOOL
 SG_ actual_pos : 32|16@1+ (1.52587890625e-05,0) [0|0.9999847412109375] "rev"  NODE14,MASTER,TOOL
 SG_ alive_counter : 48|8@1+ (1,0) [0|255] ""  NODE14,MASTER,TOOL
 SG_ sync_error : 56|8@1- (0.00390625,0) [-0.5|0.49609375] "rev"  NODE14,MASTER,TOOL

BO_ 462 S0_NODE_DIAG_14: 8 NODE14
 SG_ bus_voltage : 0|16@1+ (0.1,0) [0|6553.5] "V"  NODE14,MASTER,TOOL
 SG_ motor_current : 16|16@1- (0.1,0) [-3276.8|3276.7] "A"  NODE14,MASTER,TOOL
 SG_ controller_temp : 32|8@1+ (1,0) [0|255] "C"  NODE14,MASTER,TOOL
 SG_ motor_temp : 40|8@1+ (1,0) [0|255] "C"  NODE14,MASTER,TOOL
 SG_ fault_flags : 48|8@1+ (1,0) [0|255] "bitfield"  NODE14,MASTER,TOOL
 SG_ warning_flags : 56|8@1+ (1,0) [0|255] "bitfield"  NODE14,MASTER,TOOL

BO_ 271 S0_NODE_CMD_15: 8 MASTER
 SG_ node_command : 0|8@1+ (1,0) [0|255] ""  MASTER,TOOL
 SG_ node_flags : 8|8@1+ (1,0) [0|255] "bitfield"  MASTER,TOOL
 SG_ trim_rpm : 16|16@1- (0.1,0) [-3276.8|3276.7] "rpm"  MASTER,TOOL
 SG_ section_mask : 32|16@1+ (1,0) [0|65535] "bitmask"  MASTER,TOOL
 SG_ seq : 48|8@1+ (1,0) [0|255] ""  MASTER,TOOL
 SG_ reserved : 56|8@1+ (1,0) [0|255] ""  MASTER,TOOL

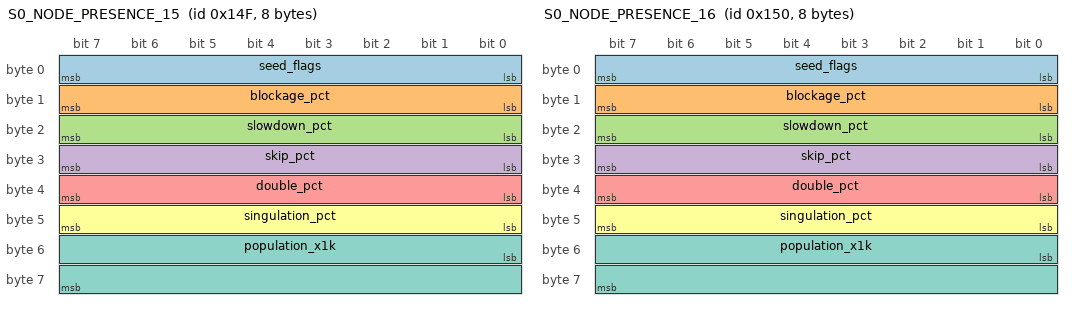
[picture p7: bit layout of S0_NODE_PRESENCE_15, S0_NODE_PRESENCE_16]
BO_ 335 S0_NODE_PRESENCE_15: 8 NODE15
 SG_ seed_flags : 0|8@1+ (1,0) [0|255] "bitfield"  NODE15,MASTER,TOOL
 SG_ blockage_pct : 8|8@1+ (1,0) [0|100] "%"  NODE15,MASTER,TOOL
 SG_ slowdown_pct : 16|8@1+ (1,0) [0|100] "%"  NODE15,MASTER,TOOL
 SG_ skip_pct : 24|8@1+ (1,0) [0|100] "%"  NODE15,MASTER,TOOL
 SG_ double_pct : 32|8@1+ (1,0) [0|100] "%"  NODE15,MASTER,TOOL
 SG_ singulation_pct : 40|8@1+ (1,0) [0|100] "%"  NODE15,MASTER,TOOL
 SG_ population_x1k : 48|16@1+ (1,0) [0|65535] "x1000"  NODE15,MASTER,TOOL

BO_ 399 S0_NODE_STATUS_FAST_15: 8 NODE15
 SG_ status_flags : 0|8@1+ (1,0) [0|255] "bitfield"  NODE15,MASTER,TOOL
 SG_ error_code : 8|8@1+ (1,0) [0|255] ""  NODE15,MASTER,TOOL
 SG_ actual_rpm : 16|16@1+ (1,0) [0|10000] "rpm"  NODE15,MASTER,TOOL
 SG_ actual_pos : 32|16@1+ (1.52587890625e-05,0) [0|0.9999847412109375] "rev"  NODE15,MASTER,TOOL
 SG_ alive_counter : 48|8@1+ (1,0) [0|255] ""  NODE15,MASTER,TOOL
 SG_ sync_error : 56|8@1- (0.00390625,0) [-0.5|0.49609375] "rev"  NODE15,MASTER,TOOL

BO_ 463 S0_NODE_DIAG_15: 8 NODE15
 SG_ bus_voltage : 0|16@1+ (0.1,0) [0|6553.5] "V"  NODE15,MASTER,TOOL
 SG_ motor_current : 16|16@1- (0.1,0) [-3276.8|3276.7] "A"  NODE15,MASTER,TOOL
 SG_ controller_temp : 32|8@1+ (1,0) [0|255] "C"  NODE15,MASTER,TOOL
 SG_ motor_temp : 40|8@1+ (1,0) [0|255] "C"  NODE15,MASTER,TOOL
 SG_ fault_flags : 48|8@1+ (1,0) [0|255] "bitfield"  NODE15,MASTER,TOOL
 SG_ warning_flags : 56|8@1+ (1,0) [0|255] "bitfield"  NODE15,MASTER,TOOL

BO_ 272 S0_NODE_CMD_16: 8 MASTER
 SG_ node_command : 0|8@1+ (1,0) [0|255] ""  MASTER,TOOL
 SG_ node_flags : 8|8@1+ (1,0) [0|255] "bitfield"  MASTER,TOOL
 SG_ trim_rpm : 16|16@1- (0.1,0) [-3276.8|3276.7] "rpm"  MASTER,TOOL
 SG_ section_mask : 32|16@1+ (1,0) [0|65535] "bitmask"  MASTER,TOOL
 SG_ seq : 48|8@1+ (1,0) [0|255] ""  MASTER,TOOL
 SG_ reserved : 56|8@1+ (1,0) [0|255] ""  MASTER,TOOL

BO_ 336 S0_NODE_PRESENCE_16: 8 NODE16
 SG_ seed_flags : 0|8@1+ (1,0) [0|255] "bitfield"  NODE16,MASTER,TOOL
 SG_ blockage_pct : 8|8@1+ (1,0) [0|100] "%"  NODE16,MASTER,TOOL
 SG_ slowdown_pct : 16|8@1+ (1,0) [0|100] "%"  NODE16,MASTER,TOOL
 SG_ skip_pct : 24|8@1+ (1,0) [0|100] "%"  NODE16,MASTER,TOOL
 SG_ double_pct : 32|8@1+ (1,0) [0|100] "%"  NODE16,MASTER,TOOL
 SG_ singulation_pct : 40|8@1+ (1,0) [0|100] "%"  NODE16,MASTER,TOOL
 SG_ population_x1k : 48|16@1+ (1,0) [0|65535] "x1000"  NODE16,MASTER,TOOL

BO_ 400 S0_NODE_STATUS_FAST_16: 8 NODE16
 SG_ status_flags : 0|8@1+ (1,0) [0|255] "bitfield"  NODE16,MASTER,TOOL
 SG_ error_code : 8|8@1+ (1,0) [0|255] ""  NODE16,MASTER,TOOL
 SG_ actual_rpm : 16|16@1+ (1,0) [0|10000] "rpm"  NODE16,MASTER,TOOL
 SG_ actual_pos : 32|16@1+ (1.52587890625e-05,0) [0|0.9999847412109375] "rev"  NODE16,MASTER,TOOL
 SG_ alive_counter : 48|8@1+ (1,0) [0|255] ""  NODE16,MASTER,TOOL
 SG_ sync_error : 56|8@1- (0.00390625,0) [-0.5|0.49609375] "rev"  NODE16,MASTER,TOOL

BO_ 464 S0_NODE_DIAG_16: 8 NODE16
 SG_ bus_voltage : 0|16@1+ (0.1,0) [0|6553.5] "V"  NODE16,MASTER,TOOL
 SG_ motor_current : 16|16@1- (0.1,0) [-3276.8|3276.7] "A"  NODE16,MASTER,TOOL
 SG_ controller_temp : 32|8@1+ (1,0) [0|255] "C"  NODE16,MASTER,TOOL
 SG_ motor_temp : 40|8@1+ (1,0) [0|255] "C"  NODE16,MASTER,TOOL
 SG_ fault_flags : 48|8@1+ (1,0) [0|255] "bitfield"  NODE16,MASTER,TOOL
 SG_ warning_flags : 56|8@1+ (1,0) [0|255] "bitfield"  NODE16,MASTER,TOOL

BO_ 512 S1_GLOBAL_CONTROL: 8 MASTER
 SG_ system_mode : 0|8@1+ (1,0) [0|255] ""  MASTER,TOOL
 SG_ control_flags : 8|8@1+ (1,0) [0|255] "bitfield"  MASTER,TOOL
 SG_ ctrl_drive_enable : 8|1@1+ (1,0) [0|1] "bool"  MASTER,TOOL
 SG_ ctrl_sync_enable : 9|1@1+ (1,0) [0|1] "bool"  MASTER,TOOL
 SG_ ctrl_estop : 10|1@1+ (1,0) [0|1] "bool"  MASTER,TOOL
 SG_ ctrl_diag_enable : 11|1@1+ (1,0) [0|1] "bool"  MASTER,TOOL
 SG_ base_rpm : 16|16@1+ (1,0) [0|10000] "rpm"  MASTER,TOOL
 SG_ sync_pos : 32|16@1+ (1.52587890625e-05,0) [0|0.9999847412109375] "rev"  MASTER,TOOL
 SG_ sequence : 48|8@1+ (1,0) [0|255] ""  MASTER,TOOL
 SG_ reserved : 56|8@1+ (1,0) [0|255] ""  MASTER,TOOL

BO_ 529 S1_NODE_CMD_1: 8 MASTER
 SG_ node_command : 0|8@1+ (1,0) [0|255] ""  MASTER,TOOL
 SG_ node_flags : 8|8@1+ (1,0) [0|255] "bitfield"  MASTER,TOOL
 SG_ trim_rpm : 16|16@1- (0.1,0) [-3276.8|3276.7] "rpm"  MASTER,TOOL
 SG_ section_mask : 32|16@1+ (1,0) [0|65535] "bitmask"  MASTER,TOOL
 SG_ seq : 48|8@1+ (1,0) [0|255] ""  MASTER,TOOL
 SG_ reserved : 56|8@1+ (1,0) [0|255] ""  MASTER,TOOL

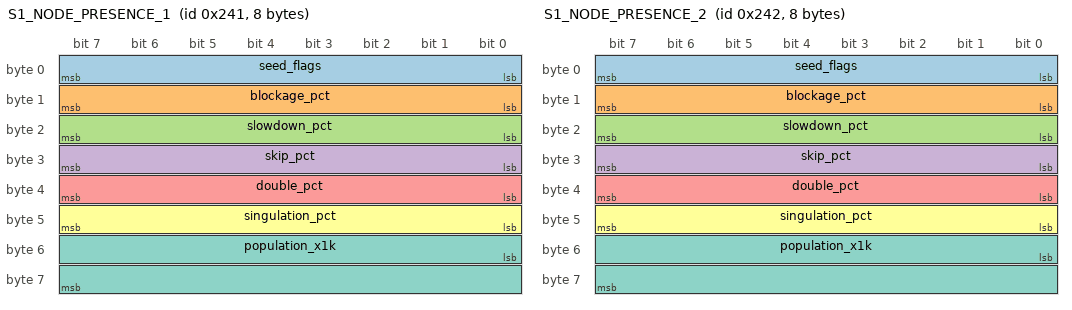
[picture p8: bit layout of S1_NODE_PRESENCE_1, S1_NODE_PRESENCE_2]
BO_ 577 S1_NODE_PRESENCE_1: 8 NODE1
 SG_ seed_flags : 0|8@1+ (1,0) [0|255] "bitfield"  NODE1,MASTER,TOOL
 SG_ blockage_pct : 8|8@1+ (1,0) [0|100] "%"  NODE1,MASTER,TOOL
 SG_ slowdown_pct : 16|8@1+ (1,0) [0|100] "%"  NODE1,MASTER,TOOL
 SG_ skip_pct : 24|8@1+ (1,0) [0|100] "%"  NODE1,MASTER,TOOL
 SG_ double_pct : 32|8@1+ (1,0) [0|100] "%"  NODE1,MASTER,TOOL
 SG_ singulation_pct : 40|8@1+ (1,0) [0|100] "%"  NODE1,MASTER,TOOL
 SG_ population_x1k : 48|16@1+ (1,0) [0|65535] "x1000"  NODE1,MASTER,TOOL

BO_ 641 S1_NODE_STATUS_FAST_1: 8 NODE1
 SG_ status_flags : 0|8@1+ (1,0) [0|255] "bitfield"  NODE1,MASTER,TOOL
 SG_ error_code : 8|8@1+ (1,0) [0|255] ""  NODE1,MASTER,TOOL
 SG_ actual_rpm : 16|16@1+ (1,0) [0|10000] "rpm"  NODE1,MASTER,TOOL
 SG_ actual_pos : 32|16@1+ (1.52587890625e-05,0) [0|0.9999847412109375] "rev"  NODE1,MASTER,TOOL
 SG_ alive_counter : 48|8@1+ (1,0) [0|255] ""  NODE1,MASTER,TOOL
 SG_ sync_error : 56|8@1- (0.00390625,0) [-0.5|0.49609375] "rev"  NODE1,MASTER,TOOL

BO_ 705 S1_NODE_DIAG_1: 8 NODE1
 SG_ bus_voltage : 0|16@1+ (0.1,0) [0|6553.5] "V"  NODE1,MASTER,TOOL
 SG_ motor_current : 16|16@1- (0.1,0) [-3276.8|3276.7] "A"  NODE1,MASTER,TOOL
 SG_ controller_temp : 32|8@1+ (1,0) [0|255] "C"  NODE1,MASTER,TOOL
 SG_ motor_temp : 40|8@1+ (1,0) [0|255] "C"  NODE1,MASTER,TOOL
 SG_ fault_flags : 48|8@1+ (1,0) [0|255] "bitfield"  NODE1,MASTER,TOOL
 SG_ warning_flags : 56|8@1+ (1,0) [0|255] "bitfield"  NODE1,MASTER,TOOL

BO_ 530 S1_NODE_CMD_2: 8 MASTER
 SG_ node_command : 0|8@1+ (1,0) [0|255] ""  MASTER,TOOL
 SG_ node_flags : 8|8@1+ (1,0) [0|255] "bitfield"  MASTER,TOOL
 SG_ trim_rpm : 16|16@1- (0.1,0) [-3276.8|3276.7] "rpm"  MASTER,TOOL
 SG_ section_mask : 32|16@1+ (1,0) [0|65535] "bitmask"  MASTER,TOOL
 SG_ seq : 48|8@1+ (1,0) [0|255] ""  MASTER,TOOL
 SG_ reserved : 56|8@1+ (1,0) [0|255] ""  MASTER,TOOL

BO_ 578 S1_NODE_PRESENCE_2: 8 NODE2
 SG_ seed_flags : 0|8@1+ (1,0) [0|255] "bitfield"  NODE2,MASTER,TOOL
 SG_ blockage_pct : 8|8@1+ (1,0) [0|100] "%"  NODE2,MASTER,TOOL
 SG_ slowdown_pct : 16|8@1+ (1,0) [0|100] "%"  NODE2,MASTER,TOOL
 SG_ skip_pct : 24|8@1+ (1,0) [0|100] "%"  NODE2,MASTER,TOOL
 SG_ double_pct : 32|8@1+ (1,0) [0|100] "%"  NODE2,MASTER,TOOL
 SG_ singulation_pct : 40|8@1+ (1,0) [0|100] "%"  NODE2,MASTER,TOOL
 SG_ population_x1k : 48|16@1+ (1,0) [0|65535] "x1000"  NODE2,MASTER,TOOL

BO_ 642 S1_NODE_STATUS_FAST_2: 8 NODE2
 SG_ status_flags : 0|8@1+ (1,0) [0|255] "bitfield"  NODE2,MASTER,TOOL
 SG_ error_code : 8|8@1+ (1,0) [0|255] ""  NODE2,MASTER,TOOL
 SG_ actual_rpm : 16|16@1+ (1,0) [0|10000] "rpm"  NODE2,MASTER,TOOL
 SG_ actual_pos : 32|16@1+ (1.52587890625e-05,0) [0|0.9999847412109375] "rev"  NODE2,MASTER,TOOL
 SG_ alive_counter : 48|8@1+ (1,0) [0|255] ""  NODE2,MASTER,TOOL
 SG_ sync_error : 56|8@1- (0.00390625,0) [-0.5|0.49609375] "rev"  NODE2,MASTER,TOOL

BO_ 706 S1_NODE_DIAG_2: 8 NODE2
 SG_ bus_voltage : 0|16@1+ (0.1,0) [0|6553.5] "V"  NODE2,MASTER,TOOL
 SG_ motor_current : 16|16@1- (0.1,0) [-3276.8|3276.7] "A"  NODE2,MASTER,TOOL
 SG_ controller_temp : 32|8@1+ (1,0) [0|255] "C"  NODE2,MASTER,TOOL
 SG_ motor_temp : 40|8@1+ (1,0) [0|255] "C"  NODE2,MASTER,TOOL
 SG_ fault_flags : 48|8@1+ (1,0) [0|255] "bitfield"  NODE2,MASTER,TOOL
 SG_ warning_flags : 56|8@1+ (1,0) [0|255] "bitfield"  NODE2,MASTER,TOOL

BO_ 531 S1_NODE_CMD_3: 8 MASTER
 SG_ node_command : 0|8@1+ (1,0) [0|255] ""  MASTER,TOOL
 SG_ node_flags : 8|8@1+ (1,0) [0|255] "bitfield"  MASTER,TOOL
 SG_ trim_rpm : 16|16@1- (0.1,0) [-3276.8|3276.7] "rpm"  MASTER,TOOL
 SG_ section_mask : 32|16@1+ (1,0) [0|65535] "bitmask"  MASTER,TOOL
 SG_ seq : 48|8@1+ (1,0) [0|255] ""  MASTER,TOOL
 SG_ reserved : 56|8@1+ (1,0) [0|255] ""  MASTER,TOOL

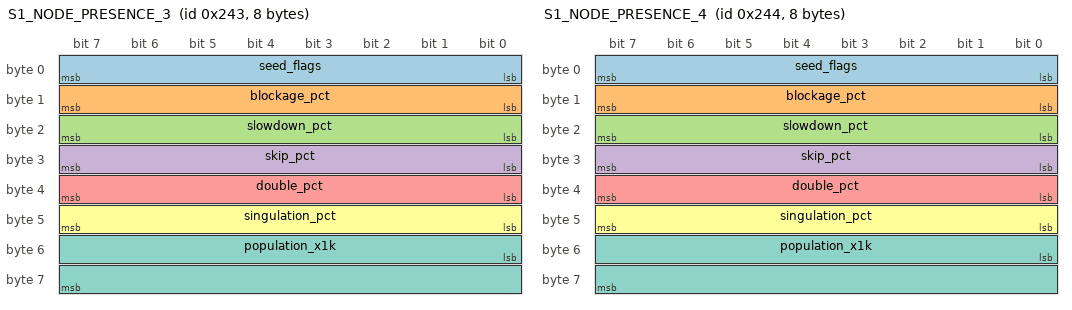
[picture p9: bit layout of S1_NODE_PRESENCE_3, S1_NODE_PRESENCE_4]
BO_ 579 S1_NODE_PRESENCE_3: 8 NODE3
 SG_ seed_flags : 0|8@1+ (1,0) [0|255] "bitfield"  NODE3,MASTER,TOOL
 SG_ blockage_pct : 8|8@1+ (1,0) [0|100] "%"  NODE3,MASTER,TOOL
 SG_ slowdown_pct : 16|8@1+ (1,0) [0|100] "%"  NODE3,MASTER,TOOL
 SG_ skip_pct : 24|8@1+ (1,0) [0|100] "%"  NODE3,MASTER,TOOL
 SG_ double_pct : 32|8@1+ (1,0) [0|100] "%"  NODE3,MASTER,TOOL
 SG_ singulation_pct : 40|8@1+ (1,0) [0|100] "%"  NODE3,MASTER,TOOL
 SG_ population_x1k : 48|16@1+ (1,0) [0|65535] "x1000"  NODE3,MASTER,TOOL

BO_ 643 S1_NODE_STATUS_FAST_3: 8 NODE3
 SG_ status_flags : 0|8@1+ (1,0) [0|255] "bitfield"  NODE3,MASTER,TOOL
 SG_ error_code : 8|8@1+ (1,0) [0|255] ""  NODE3,MASTER,TOOL
 SG_ actual_rpm : 16|16@1+ (1,0) [0|10000] "rpm"  NODE3,MASTER,TOOL
 SG_ actual_pos : 32|16@1+ (1.52587890625e-05,0) [0|0.9999847412109375] "rev"  NODE3,MASTER,TOOL
 SG_ alive_counter : 48|8@1+ (1,0) [0|255] ""  NODE3,MASTER,TOOL
 SG_ sync_error : 56|8@1- (0.00390625,0) [-0.5|0.49609375] "rev"  NODE3,MASTER,TOOL

BO_ 707 S1_NODE_DIAG_3: 8 NODE3
 SG_ bus_voltage : 0|16@1+ (0.1,0) [0|6553.5] "V"  NODE3,MASTER,TOOL
 SG_ motor_current : 16|16@1- (0.1,0) [-3276.8|3276.7] "A"  NODE3,MASTER,TOOL
 SG_ controller_temp : 32|8@1+ (1,0) [0|255] "C"  NODE3,MASTER,TOOL
 SG_ motor_temp : 40|8@1+ (1,0) [0|255] "C"  NODE3,MASTER,TOOL
 SG_ fault_flags : 48|8@1+ (1,0) [0|255] "bitfield"  NODE3,MASTER,TOOL
 SG_ warning_flags : 56|8@1+ (1,0) [0|255] "bitfield"  NODE3,MASTER,TOOL

BO_ 532 S1_NODE_CMD_4: 8 MASTER
 SG_ node_command : 0|8@1+ (1,0) [0|255] ""  MASTER,TOOL
 SG_ node_flags : 8|8@1+ (1,0) [0|255] "bitfield"  MASTER,TOOL
 SG_ trim_rpm : 16|16@1- (0.1,0) [-3276.8|3276.7] "rpm"  MASTER,TOOL
 SG_ section_mask : 32|16@1+ (1,0) [0|65535] "bitmask"  MASTER,TOOL
 SG_ seq : 48|8@1+ (1,0) [0|255] ""  MASTER,TOOL
 SG_ reserved : 56|8@1+ (1,0) [0|255] ""  MASTER,TOOL

BO_ 580 S1_NODE_PRESENCE_4: 8 NODE4
 SG_ seed_flags : 0|8@1+ (1,0) [0|255] "bitfield"  NODE4,MASTER,TOOL
 SG_ blockage_pct : 8|8@1+ (1,0) [0|100] "%"  NODE4,MASTER,TOOL
 SG_ slowdown_pct : 16|8@1+ (1,0) [0|100] "%"  NODE4,MASTER,TOOL
 SG_ skip_pct : 24|8@1+ (1,0) [0|100] "%"  NODE4,MASTER,TOOL
 SG_ double_pct : 32|8@1+ (1,0) [0|100] "%"  NODE4,MASTER,TOOL
 SG_ singulation_pct : 40|8@1+ (1,0) [0|100] "%"  NODE4,MASTER,TOOL
 SG_ population_x1k : 48|16@1+ (1,0) [0|65535] "x1000"  NODE4,MASTER,TOOL

BO_ 644 S1_NODE_STATUS_FAST_4: 8 NODE4
 SG_ status_flags : 0|8@1+ (1,0) [0|255] "bitfield"  NODE4,MASTER,TOOL
 SG_ error_code : 8|8@1+ (1,0) [0|255] ""  NODE4,MASTER,TOOL
 SG_ actual_rpm : 16|16@1+ (1,0) [0|10000] "rpm"  NODE4,MASTER,TOOL
 SG_ actual_pos : 32|16@1+ (1.52587890625e-05,0) [0|0.9999847412109375] "rev"  NODE4,MASTER,TOOL
 SG_ alive_counter : 48|8@1+ (1,0) [0|255] ""  NODE4,MASTER,TOOL
 SG_ sync_error : 56|8@1- (0.00390625,0) [-0.5|0.49609375] "rev"  NODE4,MASTER,TOOL

BO_ 708 S1_NODE_DIAG_4: 8 NODE4
 SG_ bus_voltage : 0|16@1+ (0.1,0) [0|6553.5] "V"  NODE4,MASTER,TOOL
 SG_ motor_current : 16|16@1- (0.1,0) [-3276.8|3276.7] "A"  NODE4,MASTER,TOOL
 SG_ controller_temp : 32|8@1+ (1,0) [0|255] "C"  NODE4,MASTER,TOOL
 SG_ motor_temp : 40|8@1+ (1,0) [0|255] "C"  NODE4,MASTER,TOOL
 SG_ fault_flags : 48|8@1+ (1,0) [0|255] "bitfield"  NODE4,MASTER,TOOL
 SG_ warning_flags : 56|8@1+ (1,0) [0|255] "bitfield"  NODE4,MASTER,TOOL

BO_ 533 S1_NODE_CMD_5: 8 MASTER
 SG_ node_command : 0|8@1+ (1,0) [0|255] ""  MASTER,TOOL
 SG_ node_flags : 8|8@1+ (1,0) [0|255] "bitfield"  MASTER,TOOL
 SG_ trim_rpm : 16|16@1- (0.1,0) [-3276.8|3276.7] "rpm"  MASTER,TOOL
 SG_ section_mask : 32|16@1+ (1,0) [0|65535] "bitmask"  MASTER,TOOL
 SG_ seq : 48|8@1+ (1,0) [0|255] ""  MASTER,TOOL
 SG_ reserved : 56|8@1+ (1,0) [0|255] ""  MASTER,TOOL

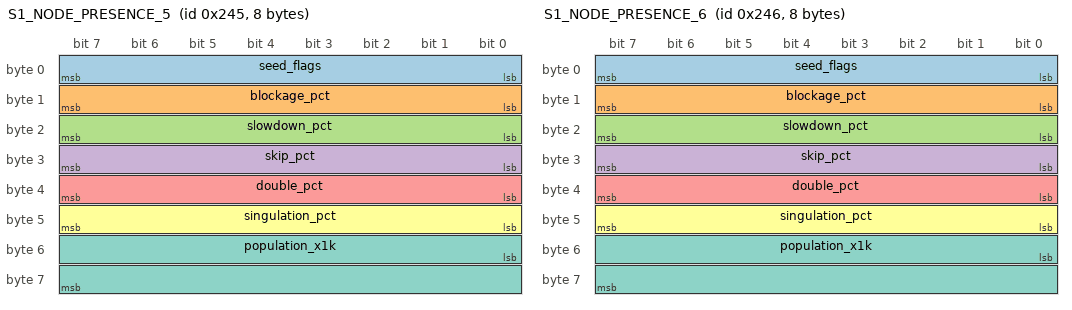
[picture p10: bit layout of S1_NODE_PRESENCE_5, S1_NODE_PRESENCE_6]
BO_ 581 S1_NODE_PRESENCE_5: 8 NODE5
 SG_ seed_flags : 0|8@1+ (1,0) [0|255] "bitfield"  NODE5,MASTER,TOOL
 SG_ blockage_pct : 8|8@1+ (1,0) [0|100] "%"  NODE5,MASTER,TOOL
 SG_ slowdown_pct : 16|8@1+ (1,0) [0|100] "%"  NODE5,MASTER,TOOL
 SG_ skip_pct : 24|8@1+ (1,0) [0|100] "%"  NODE5,MASTER,TOOL
 SG_ double_pct : 32|8@1+ (1,0) [0|100] "%"  NODE5,MASTER,TOOL
 SG_ singulation_pct : 40|8@1+ (1,0) [0|100] "%"  NODE5,MASTER,TOOL
 SG_ population_x1k : 48|16@1+ (1,0) [0|65535] "x1000"  NODE5,MASTER,TOOL

BO_ 645 S1_NODE_STATUS_FAST_5: 8 NODE5
 SG_ status_flags : 0|8@1+ (1,0) [0|255] "bitfield"  NODE5,MASTER,TOOL
 SG_ error_code : 8|8@1+ (1,0) [0|255] ""  NODE5,MASTER,TOOL
 SG_ actual_rpm : 16|16@1+ (1,0) [0|10000] "rpm"  NODE5,MASTER,TOOL
 SG_ actual_pos : 32|16@1+ (1.52587890625e-05,0) [0|0.9999847412109375] "rev"  NODE5,MASTER,TOOL
 SG_ alive_counter : 48|8@1+ (1,0) [0|255] ""  NODE5,MASTER,TOOL
 SG_ sync_error : 56|8@1- (0.00390625,0) [-0.5|0.49609375] "rev"  NODE5,MASTER,TOOL

BO_ 709 S1_NODE_DIAG_5: 8 NODE5
 SG_ bus_voltage : 0|16@1+ (0.1,0) [0|6553.5] "V"  NODE5,MASTER,TOOL
 SG_ motor_current : 16|16@1- (0.1,0) [-3276.8|3276.7] "A"  NODE5,MASTER,TOOL
 SG_ controller_temp : 32|8@1+ (1,0) [0|255] "C"  NODE5,MASTER,TOOL
 SG_ motor_temp : 40|8@1+ (1,0) [0|255] "C"  NODE5,MASTER,TOOL
 SG_ fault_flags : 48|8@1+ (1,0) [0|255] "bitfield"  NODE5,MASTER,TOOL
 SG_ warning_flags : 56|8@1+ (1,0) [0|255] "bitfield"  NODE5,MASTER,TOOL

BO_ 534 S1_NODE_CMD_6: 8 MASTER
 SG_ node_command : 0|8@1+ (1,0) [0|255] ""  MASTER,TOOL
 SG_ node_flags : 8|8@1+ (1,0) [0|255] "bitfield"  MASTER,TOOL
 SG_ trim_rpm : 16|16@1- (0.1,0) [-3276.8|3276.7] "rpm"  MASTER,TOOL
 SG_ section_mask : 32|16@1+ (1,0) [0|65535] "bitmask"  MASTER,TOOL
 SG_ seq : 48|8@1+ (1,0) [0|255] ""  MASTER,TOOL
 SG_ reserved : 56|8@1+ (1,0) [0|255] ""  MASTER,TOOL

BO_ 582 S1_NODE_PRESENCE_6: 8 NODE6
 SG_ seed_flags : 0|8@1+ (1,0) [0|255] "bitfield"  NODE6,MASTER,TOOL
 SG_ blockage_pct : 8|8@1+ (1,0) [0|100] "%"  NODE6,MASTER,TOOL
 SG_ slowdown_pct : 16|8@1+ (1,0) [0|100] "%"  NODE6,MASTER,TOOL
 SG_ skip_pct : 24|8@1+ (1,0) [0|100] "%"  NODE6,MASTER,TOOL
 SG_ double_pct : 32|8@1+ (1,0) [0|100] "%"  NODE6,MASTER,TOOL
 SG_ singulation_pct : 40|8@1+ (1,0) [0|100] "%"  NODE6,MASTER,TOOL
 SG_ population_x1k : 48|16@1+ (1,0) [0|65535] "x1000"  NODE6,MASTER,TOOL

BO_ 646 S1_NODE_STATUS_FAST_6: 8 NODE6
 SG_ status_flags : 0|8@1+ (1,0) [0|255] "bitfield"  NODE6,MASTER,TOOL
 SG_ error_code : 8|8@1+ (1,0) [0|255] ""  NODE6,MASTER,TOOL
 SG_ actual_rpm : 16|16@1+ (1,0) [0|10000] "rpm"  NODE6,MASTER,TOOL
 SG_ actual_pos : 32|16@1+ (1.52587890625e-05,0) [0|0.9999847412109375] "rev"  NODE6,MASTER,TOOL
 SG_ alive_counter : 48|8@1+ (1,0) [0|255] ""  NODE6,MASTER,TOOL
 SG_ sync_error : 56|8@1- (0.00390625,0) [-0.5|0.49609375] "rev"  NODE6,MASTER,TOOL

BO_ 710 S1_NODE_DIAG_6: 8 NODE6
 SG_ bus_voltage : 0|16@1+ (0.1,0) [0|6553.5] "V"  NODE6,MASTER,TOOL
 SG_ motor_current : 16|16@1- (0.1,0) [-3276.8|3276.7] "A"  NODE6,MASTER,TOOL
 SG_ controller_temp : 32|8@1+ (1,0) [0|255] "C"  NODE6,MASTER,TOOL
 SG_ motor_temp : 40|8@1+ (1,0) [0|255] "C"  NODE6,MASTER,TOOL
 SG_ fault_flags : 48|8@1+ (1,0) [0|255] "bitfield"  NODE6,MASTER,TOOL
 SG_ warning_flags : 56|8@1+ (1,0) [0|255] "bitfield"  NODE6,MASTER,TOOL

BO_ 535 S1_NODE_CMD_7: 8 MASTER
 SG_ node_command : 0|8@1+ (1,0) [0|255] ""  MASTER,TOOL
 SG_ node_flags : 8|8@1+ (1,0) [0|255] "bitfield"  MASTER,TOOL
 SG_ trim_rpm : 16|16@1- (0.1,0) [-3276.8|3276.7] "rpm"  MASTER,TOOL
 SG_ section_mask : 32|16@1+ (1,0) [0|65535] "bitmask"  MASTER,TOOL
 SG_ seq : 48|8@1+ (1,0) [0|255] ""  MASTER,TOOL
 SG_ reserved : 56|8@1+ (1,0) [0|255] ""  MASTER,TOOL

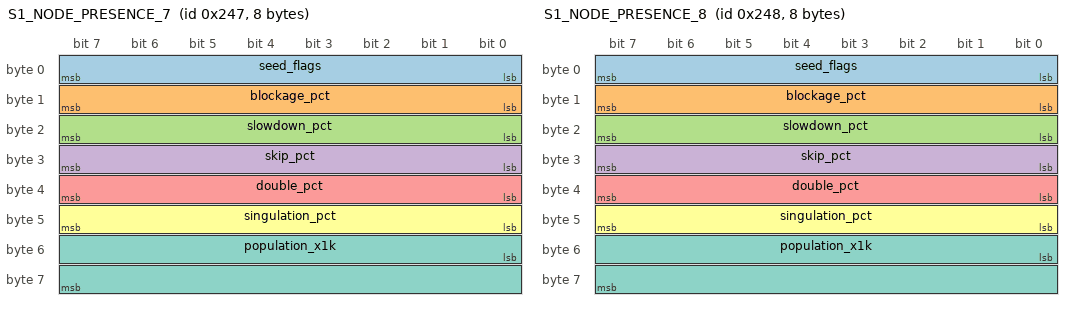
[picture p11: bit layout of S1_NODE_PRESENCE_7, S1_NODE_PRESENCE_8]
BO_ 583 S1_NODE_PRESENCE_7: 8 NODE7
 SG_ seed_flags : 0|8@1+ (1,0) [0|255] "bitfield"  NODE7,MASTER,TOOL
 SG_ blockage_pct : 8|8@1+ (1,0) [0|100] "%"  NODE7,MASTER,TOOL
 SG_ slowdown_pct : 16|8@1+ (1,0) [0|100] "%"  NODE7,MASTER,TOOL
 SG_ skip_pct : 24|8@1+ (1,0) [0|100] "%"  NODE7,MASTER,TOOL
 SG_ double_pct : 32|8@1+ (1,0) [0|100] "%"  NODE7,MASTER,TOOL
 SG_ singulation_pct : 40|8@1+ (1,0) [0|100] "%"  NODE7,MASTER,TOOL
 SG_ population_x1k : 48|16@1+ (1,0) [0|65535] "x1000"  NODE7,MASTER,TOOL

BO_ 647 S1_NODE_STATUS_FAST_7: 8 NODE7
 SG_ status_flags : 0|8@1+ (1,0) [0|255] "bitfield"  NODE7,MASTER,TOOL
 SG_ error_code : 8|8@1+ (1,0) [0|255] ""  NODE7,MASTER,TOOL
 SG_ actual_rpm : 16|16@1+ (1,0) [0|10000] "rpm"  NODE7,MASTER,TOOL
 SG_ actual_pos : 32|16@1+ (1.52587890625e-05,0) [0|0.9999847412109375] "rev"  NODE7,MASTER,TOOL
 SG_ alive_counter : 48|8@1+ (1,0) [0|255] ""  NODE7,MASTER,TOOL
 SG_ sync_error : 56|8@1- (0.00390625,0) [-0.5|0.49609375] "rev"  NODE7,MASTER,TOOL

BO_ 711 S1_NODE_DIAG_7: 8 NODE7
 SG_ bus_voltage : 0|16@1+ (0.1,0) [0|6553.5] "V"  NODE7,MASTER,TOOL
 SG_ motor_current : 16|16@1- (0.1,0) [-3276.8|3276.7] "A"  NODE7,MASTER,TOOL
 SG_ controller_temp : 32|8@1+ (1,0) [0|255] "C"  NODE7,MASTER,TOOL
 SG_ motor_temp : 40|8@1+ (1,0) [0|255] "C"  NODE7,MASTER,TOOL
 SG_ fault_flags : 48|8@1+ (1,0) [0|255] "bitfield"  NODE7,MASTER,TOOL
 SG_ warning_flags : 56|8@1+ (1,0) [0|255] "bitfield"  NODE7,MASTER,TOOL

BO_ 536 S1_NODE_CMD_8: 8 MASTER
 SG_ node_command : 0|8@1+ (1,0) [0|255] ""  MASTER,TOOL
 SG_ node_flags : 8|8@1+ (1,0) [0|255] "bitfield"  MASTER,TOOL
 SG_ trim_rpm : 16|16@1- (0.1,0) [-3276.8|3276.7] "rpm"  MASTER,TOOL
 SG_ section_mask : 32|16@1+ (1,0) [0|65535] "bitmask"  MASTER,TOOL
 SG_ seq : 48|8@1+ (1,0) [0|255] ""  MASTER,TOOL
 SG_ reserved : 56|8@1+ (1,0) [0|255] ""  MASTER,TOOL

BO_ 584 S1_NODE_PRESENCE_8: 8 NODE8
 SG_ seed_flags : 0|8@1+ (1,0) [0|255] "bitfield"  NODE8,MASTER,TOOL
 SG_ blockage_pct : 8|8@1+ (1,0) [0|100] "%"  NODE8,MASTER,TOOL
 SG_ slowdown_pct : 16|8@1+ (1,0) [0|100] "%"  NODE8,MASTER,TOOL
 SG_ skip_pct : 24|8@1+ (1,0) [0|100] "%"  NODE8,MASTER,TOOL
 SG_ double_pct : 32|8@1+ (1,0) [0|100] "%"  NODE8,MASTER,TOOL
 SG_ singulation_pct : 40|8@1+ (1,0) [0|100] "%"  NODE8,MASTER,TOOL
 SG_ population_x1k : 48|16@1+ (1,0) [0|65535] "x1000"  NODE8,MASTER,TOOL

BO_ 648 S1_NODE_STATUS_FAST_8: 8 NODE8
 SG_ status_flags : 0|8@1+ (1,0) [0|255] "bitfield"  NODE8,MASTER,TOOL
 SG_ error_code : 8|8@1+ (1,0) [0|255] ""  NODE8,MASTER,TOOL
 SG_ actual_rpm : 16|16@1+ (1,0) [0|10000] "rpm"  NODE8,MASTER,TOOL
 SG_ actual_pos : 32|16@1+ (1.52587890625e-05,0) [0|0.9999847412109375] "rev"  NODE8,MASTER,TOOL
 SG_ alive_counter : 48|8@1+ (1,0) [0|255] ""  NODE8,MASTER,TOOL
 SG_ sync_error : 56|8@1- (0.00390625,0) [-0.5|0.49609375] "rev"  NODE8,MASTER,TOOL

BO_ 712 S1_NODE_DIAG_8: 8 NODE8
 SG_ bus_voltage : 0|16@1+ (0.1,0) [0|6553.5] "V"  NODE8,MASTER,TOOL
 SG_ motor_current : 16|16@1- (0.1,0) [-3276.8|3276.7] "A"  NODE8,MASTER,TOOL
 SG_ controller_temp : 32|8@1+ (1,0) [0|255] "C"  NODE8,MASTER,TOOL
 SG_ motor_temp : 40|8@1+ (1,0) [0|255] "C"  NODE8,MASTER,TOOL
 SG_ fault_flags : 48|8@1+ (1,0) [0|255] "bitfield"  NODE8,MASTER,TOOL
 SG_ warning_flags : 56|8@1+ (1,0) [0|255] "bitfield"  NODE8,MASTER,TOOL

BO_ 537 S1_NODE_CMD_9: 8 MASTER
 SG_ node_command : 0|8@1+ (1,0) [0|255] ""  MASTER,TOOL
 SG_ node_flags : 8|8@1+ (1,0) [0|255] "bitfield"  MASTER,TOOL
 SG_ trim_rpm : 16|16@1- (0.1,0) [-3276.8|3276.7] "rpm"  MASTER,TOOL
 SG_ section_mask : 32|16@1+ (1,0) [0|65535] "bitmask"  MASTER,TOOL
 SG_ seq : 48|8@1+ (1,0) [0|255] ""  MASTER,TOOL
 SG_ reserved : 56|8@1+ (1,0) [0|255] ""  MASTER,TOOL

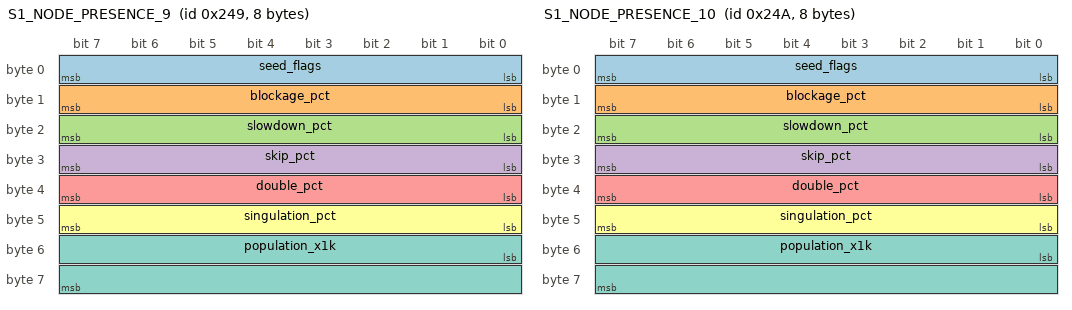
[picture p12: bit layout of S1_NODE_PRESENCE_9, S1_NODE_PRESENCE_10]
BO_ 585 S1_NODE_PRESENCE_9: 8 NODE9
 SG_ seed_flags : 0|8@1+ (1,0) [0|255] "bitfield"  NODE9,MASTER,TOOL
 SG_ blockage_pct : 8|8@1+ (1,0) [0|100] "%"  NODE9,MASTER,TOOL
 SG_ slowdown_pct : 16|8@1+ (1,0) [0|100] "%"  NODE9,MASTER,TOOL
 SG_ skip_pct : 24|8@1+ (1,0) [0|100] "%"  NODE9,MASTER,TOOL
 SG_ double_pct : 32|8@1+ (1,0) [0|100] "%"  NODE9,MASTER,TOOL
 SG_ singulation_pct : 40|8@1+ (1,0) [0|100] "%"  NODE9,MASTER,TOOL
 SG_ population_x1k : 48|16@1+ (1,0) [0|65535] "x1000"  NODE9,MASTER,TOOL

BO_ 649 S1_NODE_STATUS_FAST_9: 8 NODE9
 SG_ status_flags : 0|8@1+ (1,0) [0|255] "bitfield"  NODE9,MASTER,TOOL
 SG_ error_code : 8|8@1+ (1,0) [0|255] ""  NODE9,MASTER,TOOL
 SG_ actual_rpm : 16|16@1+ (1,0) [0|10000] "rpm"  NODE9,MASTER,TOOL
 SG_ actual_pos : 32|16@1+ (1.52587890625e-05,0) [0|0.9999847412109375] "rev"  NODE9,MASTER,TOOL
 SG_ alive_counter : 48|8@1+ (1,0) [0|255] ""  NODE9,MASTER,TOOL
 SG_ sync_error : 56|8@1- (0.00390625,0) [-0.5|0.49609375] "rev"  NODE9,MASTER,TOOL

BO_ 713 S1_NODE_DIAG_9: 8 NODE9
 SG_ bus_voltage : 0|16@1+ (0.1,0) [0|6553.5] "V"  NODE9,MASTER,TOOL
 SG_ motor_current : 16|16@1- (0.1,0) [-3276.8|3276.7] "A"  NODE9,MASTER,TOOL
 SG_ controller_temp : 32|8@1+ (1,0) [0|255] "C"  NODE9,MASTER,TOOL
 SG_ motor_temp : 40|8@1+ (1,0) [0|255] "C"  NODE9,MASTER,TOOL
 SG_ fault_flags : 48|8@1+ (1,0) [0|255] "bitfield"  NODE9,MASTER,TOOL
 SG_ warning_flags : 56|8@1+ (1,0) [0|255] "bitfield"  NODE9,MASTER,TOOL

BO_ 538 S1_NODE_CMD_10: 8 MASTER
 SG_ node_command : 0|8@1+ (1,0) [0|255] ""  MASTER,TOOL
 SG_ node_flags : 8|8@1+ (1,0) [0|255] "bitfield"  MASTER,TOOL
 SG_ trim_rpm : 16|16@1- (0.1,0) [-3276.8|3276.7] "rpm"  MASTER,TOOL
 SG_ section_mask : 32|16@1+ (1,0) [0|65535] "bitmask"  MASTER,TOOL
 SG_ seq : 48|8@1+ (1,0) [0|255] ""  MASTER,TOOL
 SG_ reserved : 56|8@1+ (1,0) [0|255] ""  MASTER,TOOL

BO_ 586 S1_NODE_PRESENCE_10: 8 NODE10
 SG_ seed_flags : 0|8@1+ (1,0) [0|255] "bitfield"  NODE10,MASTER,TOOL
 SG_ blockage_pct : 8|8@1+ (1,0) [0|100] "%"  NODE10,MASTER,TOOL
 SG_ slowdown_pct : 16|8@1+ (1,0) [0|100] "%"  NODE10,MASTER,TOOL
 SG_ skip_pct : 24|8@1+ (1,0) [0|100] "%"  NODE10,MASTER,TOOL
 SG_ double_pct : 32|8@1+ (1,0) [0|100] "%"  NODE10,MASTER,TOOL
 SG_ singulation_pct : 40|8@1+ (1,0) [0|100] "%"  NODE10,MASTER,TOOL
 SG_ population_x1k : 48|16@1+ (1,0) [0|65535] "x1000"  NODE10,MASTER,TOOL

BO_ 650 S1_NODE_STATUS_FAST_10: 8 NODE10
 SG_ status_flags : 0|8@1+ (1,0) [0|255] "bitfield"  NODE10,MASTER,TOOL
 SG_ error_code : 8|8@1+ (1,0) [0|255] ""  NODE10,MASTER,TOOL
 SG_ actual_rpm : 16|16@1+ (1,0) [0|10000] "rpm"  NODE10,MASTER,TOOL
 SG_ actual_pos : 32|16@1+ (1.52587890625e-05,0) [0|0.9999847412109375] "rev"  NODE10,MASTER,TOOL
 SG_ alive_counter : 48|8@1+ (1,0) [0|255] ""  NODE10,MASTER,TOOL
 SG_ sync_error : 56|8@1- (0.00390625,0) [-0.5|0.49609375] "rev"  NODE10,MASTER,TOOL

BO_ 714 S1_NODE_DIAG_10: 8 NODE10
 SG_ bus_voltage : 0|16@1+ (0.1,0) [0|6553.5] "V"  NODE10,MASTER,TOOL
 SG_ motor_current : 16|16@1- (0.1,0) [-3276.8|3276.7] "A"  NODE10,MASTER,TOOL
 SG_ controller_temp : 32|8@1+ (1,0) [0|255] "C"  NODE10,MASTER,TOOL
 SG_ motor_temp : 40|8@1+ (1,0) [0|255] "C"  NODE10,MASTER,TOOL
 SG_ fault_flags : 48|8@1+ (1,0) [0|255] "bitfield"  NODE10,MASTER,TOOL
 SG_ warning_flags : 56|8@1+ (1,0) [0|255] "bitfield"  NODE10,MASTER,TOOL

BO_ 539 S1_NODE_CMD_11: 8 MASTER
 SG_ node_command : 0|8@1+ (1,0) [0|255] ""  MASTER,TOOL
 SG_ node_flags : 8|8@1+ (1,0) [0|255] "bitfield"  MASTER,TOOL
 SG_ trim_rpm : 16|16@1- (0.1,0) [-3276.8|3276.7] "rpm"  MASTER,TOOL
 SG_ section_mask : 32|16@1+ (1,0) [0|65535] "bitmask"  MASTER,TOOL
 SG_ seq : 48|8@1+ (1,0) [0|255] ""  MASTER,TOOL
 SG_ reserved : 56|8@1+ (1,0) [0|255] ""  MASTER,TOOL

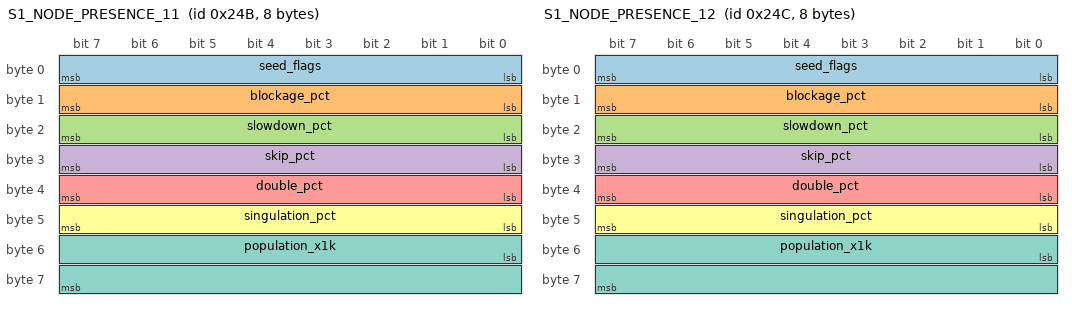
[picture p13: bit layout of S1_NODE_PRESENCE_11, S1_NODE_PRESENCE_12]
BO_ 587 S1_NODE_PRESENCE_11: 8 NODE11
 SG_ seed_flags : 0|8@1+ (1,0) [0|255] "bitfield"  NODE11,MASTER,TOOL
 SG_ blockage_pct : 8|8@1+ (1,0) [0|100] "%"  NODE11,MASTER,TOOL
 SG_ slowdown_pct : 16|8@1+ (1,0) [0|100] "%"  NODE11,MASTER,TOOL
 SG_ skip_pct : 24|8@1+ (1,0) [0|100] "%"  NODE11,MASTER,TOOL
 SG_ double_pct : 32|8@1+ (1,0) [0|100] "%"  NODE11,MASTER,TOOL
 SG_ singulation_pct : 40|8@1+ (1,0) [0|100] "%"  NODE11,MASTER,TOOL
 SG_ population_x1k : 48|16@1+ (1,0) [0|65535] "x1000"  NODE11,MASTER,TOOL

BO_ 651 S1_NODE_STATUS_FAST_11: 8 NODE11
 SG_ status_flags : 0|8@1+ (1,0) [0|255] "bitfield"  NODE11,MASTER,TOOL
 SG_ error_code : 8|8@1+ (1,0) [0|255] ""  NODE11,MASTER,TOOL
 SG_ actual_rpm : 16|16@1+ (1,0) [0|10000] "rpm"  NODE11,MASTER,TOOL
 SG_ actual_pos : 32|16@1+ (1.52587890625e-05,0) [0|0.9999847412109375] "rev"  NODE11,MASTER,TOOL
 SG_ alive_counter : 48|8@1+ (1,0) [0|255] ""  NODE11,MASTER,TOOL
 SG_ sync_error : 56|8@1- (0.00390625,0) [-0.5|0.49609375] "rev"  NODE11,MASTER,TOOL

BO_ 715 S1_NODE_DIAG_11: 8 NODE11
 SG_ bus_voltage : 0|16@1+ (0.1,0) [0|6553.5] "V"  NODE11,MASTER,TOOL
 SG_ motor_current : 16|16@1- (0.1,0) [-3276.8|3276.7] "A"  NODE11,MASTER,TOOL
 SG_ controller_temp : 32|8@1+ (1,0) [0|255] "C"  NODE11,MASTER,TOOL
 SG_ motor_temp : 40|8@1+ (1,0) [0|255] "C"  NODE11,MASTER,TOOL
 SG_ fault_flags : 48|8@1+ (1,0) [0|255] "bitfield"  NODE11,MASTER,TOOL
 SG_ warning_flags : 56|8@1+ (1,0) [0|255] "bitfield"  NODE11,MASTER,TOOL

BO_ 540 S1_NODE_CMD_12: 8 MASTER
 SG_ node_command : 0|8@1+ (1,0) [0|255] ""  MASTER,TOOL
 SG_ node_flags : 8|8@1+ (1,0) [0|255] "bitfield"  MASTER,TOOL
 SG_ trim_rpm : 16|16@1- (0.1,0) [-3276.8|3276.7] "rpm"  MASTER,TOOL
 SG_ section_mask : 32|16@1+ (1,0) [0|65535] "bitmask"  MASTER,TOOL
 SG_ seq : 48|8@1+ (1,0) [0|255] ""  MASTER,TOOL
 SG_ reserved : 56|8@1+ (1,0) [0|255] ""  MASTER,TOOL

BO_ 588 S1_NODE_PRESENCE_12: 8 NODE12
 SG_ seed_flags : 0|8@1+ (1,0) [0|255] "bitfield"  NODE12,MASTER,TOOL
 SG_ blockage_pct : 8|8@1+ (1,0) [0|100] "%"  NODE12,MASTER,TOOL
 SG_ slowdown_pct : 16|8@1+ (1,0) [0|100] "%"  NODE12,MASTER,TOOL
 SG_ skip_pct : 24|8@1+ (1,0) [0|100] "%"  NODE12,MASTER,TOOL
 SG_ double_pct : 32|8@1+ (1,0) [0|100] "%"  NODE12,MASTER,TOOL
 SG_ singulation_pct : 40|8@1+ (1,0) [0|100] "%"  NODE12,MASTER,TOOL
 SG_ population_x1k : 48|16@1+ (1,0) [0|65535] "x1000"  NODE12,MASTER,TOOL

BO_ 652 S1_NODE_STATUS_FAST_12: 8 NODE12
 SG_ status_flags : 0|8@1+ (1,0) [0|255] "bitfield"  NODE12,MASTER,TOOL
 SG_ error_code : 8|8@1+ (1,0) [0|255] ""  NODE12,MASTER,TOOL
 SG_ actual_rpm : 16|16@1+ (1,0) [0|10000] "rpm"  NODE12,MASTER,TOOL
 SG_ actual_pos : 32|16@1+ (1.52587890625e-05,0) [0|0.9999847412109375] "rev"  NODE12,MASTER,TOOL
 SG_ alive_counter : 48|8@1+ (1,0) [0|255] ""  NODE12,MASTER,TOOL
 SG_ sync_error : 56|8@1- (0.00390625,0) [-0.5|0.49609375] "rev"  NODE12,MASTER,TOOL

BO_ 716 S1_NODE_DIAG_12: 8 NODE12
 SG_ bus_voltage : 0|16@1+ (0.1,0) [0|6553.5] "V"  NODE12,MASTER,TOOL
 SG_ motor_current : 16|16@1- (0.1,0) [-3276.8|3276.7] "A"  NODE12,MASTER,TOOL
 SG_ controller_temp : 32|8@1+ (1,0) [0|255] "C"  NODE12,MASTER,TOOL
 SG_ motor_temp : 40|8@1+ (1,0) [0|255] "C"  NODE12,MASTER,TOOL
 SG_ fault_flags : 48|8@1+ (1,0) [0|255] "bitfield"  NODE12,MASTER,TOOL
 SG_ warning_flags : 56|8@1+ (1,0) [0|255] "bitfield"  NODE12,MASTER,TOOL

BO_ 541 S1_NODE_CMD_13: 8 MASTER
 SG_ node_command : 0|8@1+ (1,0) [0|255] ""  MASTER,TOOL
 SG_ node_flags : 8|8@1+ (1,0) [0|255] "bitfield"  MASTER,TOOL
 SG_ trim_rpm : 16|16@1- (0.1,0) [-3276.8|3276.7] "rpm"  MASTER,TOOL
 SG_ section_mask : 32|16@1+ (1,0) [0|65535] "bitmask"  MASTER,TOOL
 SG_ seq : 48|8@1+ (1,0) [0|255] ""  MASTER,TOOL
 SG_ reserved : 56|8@1+ (1,0) [0|255] ""  MASTER,TOOL

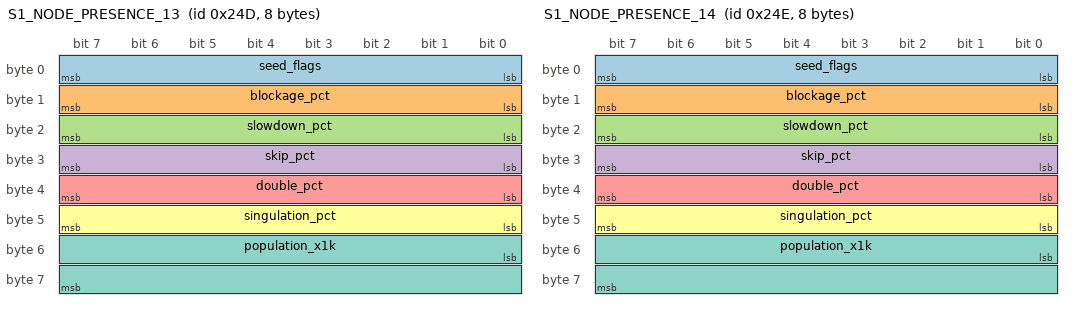
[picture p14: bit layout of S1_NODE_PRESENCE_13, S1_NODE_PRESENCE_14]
BO_ 589 S1_NODE_PRESENCE_13: 8 NODE13
 SG_ seed_flags : 0|8@1+ (1,0) [0|255] "bitfield"  NODE13,MASTER,TOOL
 SG_ blockage_pct : 8|8@1+ (1,0) [0|100] "%"  NODE13,MASTER,TOOL
 SG_ slowdown_pct : 16|8@1+ (1,0) [0|100] "%"  NODE13,MASTER,TOOL
 SG_ skip_pct : 24|8@1+ (1,0) [0|100] "%"  NODE13,MASTER,TOOL
 SG_ double_pct : 32|8@1+ (1,0) [0|100] "%"  NODE13,MASTER,TOOL
 SG_ singulation_pct : 40|8@1+ (1,0) [0|100] "%"  NODE13,MASTER,TOOL
 SG_ population_x1k : 48|16@1+ (1,0) [0|65535] "x1000"  NODE13,MASTER,TOOL

BO_ 653 S1_NODE_STATUS_FAST_13: 8 NODE13
 SG_ status_flags : 0|8@1+ (1,0) [0|255] "bitfield"  NODE13,MASTER,TOOL
 SG_ error_code : 8|8@1+ (1,0) [0|255] ""  NODE13,MASTER,TOOL
 SG_ actual_rpm : 16|16@1+ (1,0) [0|10000] "rpm"  NODE13,MASTER,TOOL
 SG_ actual_pos : 32|16@1+ (1.52587890625e-05,0) [0|0.9999847412109375] "rev"  NODE13,MASTER,TOOL
 SG_ alive_counter : 48|8@1+ (1,0) [0|255] ""  NODE13,MASTER,TOOL
 SG_ sync_error : 56|8@1- (0.00390625,0) [-0.5|0.49609375] "rev"  NODE13,MASTER,TOOL

BO_ 717 S1_NODE_DIAG_13: 8 NODE13
 SG_ bus_voltage : 0|16@1+ (0.1,0) [0|6553.5] "V"  NODE13,MASTER,TOOL
 SG_ motor_current : 16|16@1- (0.1,0) [-3276.8|3276.7] "A"  NODE13,MASTER,TOOL
 SG_ controller_temp : 32|8@1+ (1,0) [0|255] "C"  NODE13,MASTER,TOOL
 SG_ motor_temp : 40|8@1+ (1,0) [0|255] "C"  NODE13,MASTER,TOOL
 SG_ fault_flags : 48|8@1+ (1,0) [0|255] "bitfield"  NODE13,MASTER,TOOL
 SG_ warning_flags : 56|8@1+ (1,0) [0|255] "bitfield"  NODE13,MASTER,TOOL

BO_ 542 S1_NODE_CMD_14: 8 MASTER
 SG_ node_command : 0|8@1+ (1,0) [0|255] ""  MASTER,TOOL
 SG_ node_flags : 8|8@1+ (1,0) [0|255] "bitfield"  MASTER,TOOL
 SG_ trim_rpm : 16|16@1- (0.1,0) [-3276.8|3276.7] "rpm"  MASTER,TOOL
 SG_ section_mask : 32|16@1+ (1,0) [0|65535] "bitmask"  MASTER,TOOL
 SG_ seq : 48|8@1+ (1,0) [0|255] ""  MASTER,TOOL
 SG_ reserved : 56|8@1+ (1,0) [0|255] ""  MASTER,TOOL

BO_ 590 S1_NODE_PRESENCE_14: 8 NODE14
 SG_ seed_flags : 0|8@1+ (1,0) [0|255] "bitfield"  NODE14,MASTER,TOOL
 SG_ blockage_pct : 8|8@1+ (1,0) [0|100] "%"  NODE14,MASTER,TOOL
 SG_ slowdown_pct : 16|8@1+ (1,0) [0|100] "%"  NODE14,MASTER,TOOL
 SG_ skip_pct : 24|8@1+ (1,0) [0|100] "%"  NODE14,MASTER,TOOL
 SG_ double_pct : 32|8@1+ (1,0) [0|100] "%"  NODE14,MASTER,TOOL
 SG_ singulation_pct : 40|8@1+ (1,0) [0|100] "%"  NODE14,MASTER,TOOL
 SG_ population_x1k : 48|16@1+ (1,0) [0|65535] "x1000"  NODE14,MASTER,TOOL

BO_ 654 S1_NODE_STATUS_FAST_14: 8 NODE14
 SG_ status_flags : 0|8@1+ (1,0) [0|255] "bitfield"  NODE14,MASTER,TOOL
 SG_ error_code : 8|8@1+ (1,0) [0|255] ""  NODE14,MASTER,TOOL
 SG_ actual_rpm : 16|16@1+ (1,0) [0|10000] "rpm"  NODE14,MASTER,TOOL
 SG_ actual_pos : 32|16@1+ (1.52587890625e-05,0) [0|0.9999847412109375] "rev"  NODE14,MASTER,TOOL
 SG_ alive_counter : 48|8@1+ (1,0) [0|255] ""  NODE14,MASTER,TOOL
 SG_ sync_error : 56|8@1- (0.00390625,0) [-0.5|0.49609375] "rev"  NODE14,MASTER,TOOL

BO_ 718 S1_NODE_DIAG_14: 8 NODE14
 SG_ bus_voltage : 0|16@1+ (0.1,0) [0|6553.5] "V"  NODE14,MASTER,TOOL
 SG_ motor_current : 16|16@1- (0.1,0) [-3276.8|3276.7] "A"  NODE14,MASTER,TOOL
 SG_ controller_temp : 32|8@1+ (1,0) [0|255] "C"  NODE14,MASTER,TOOL
 SG_ motor_temp : 40|8@1+ (1,0) [0|255] "C"  NODE14,MASTER,TOOL
 SG_ fault_flags : 48|8@1+ (1,0) [0|255] "bitfield"  NODE14,MASTER,TOOL
 SG_ warning_flags : 56|8@1+ (1,0) [0|255] "bitfield"  NODE14,MASTER,TOOL

BO_ 543 S1_NODE_CMD_15: 8 MASTER
 SG_ node_command : 0|8@1+ (1,0) [0|255] ""  MASTER,TOOL
 SG_ node_flags : 8|8@1+ (1,0) [0|255] "bitfield"  MASTER,TOOL
 SG_ trim_rpm : 16|16@1- (0.1,0) [-3276.8|3276.7] "rpm"  MASTER,TOOL
 SG_ section_mask : 32|16@1+ (1,0) [0|65535] "bitmask"  MASTER,TOOL
 SG_ seq : 48|8@1+ (1,0) [0|255] ""  MASTER,TOOL
 SG_ reserved : 56|8@1+ (1,0) [0|255] ""  MASTER,TOOL

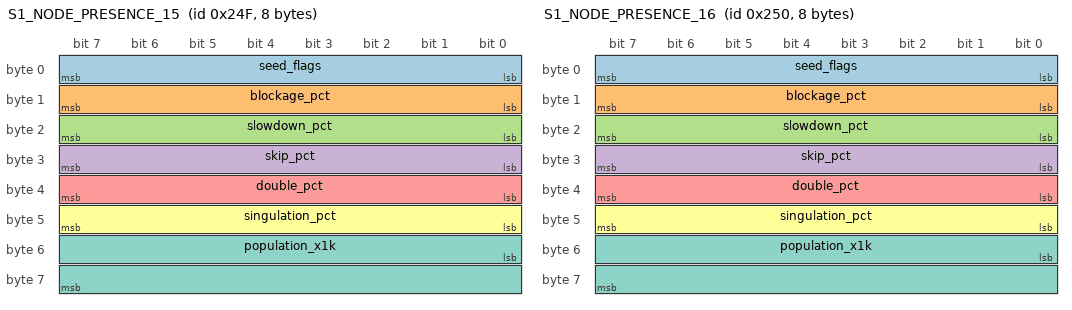
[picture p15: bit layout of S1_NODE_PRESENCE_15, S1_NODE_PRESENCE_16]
BO_ 591 S1_NODE_PRESENCE_15: 8 NODE15
 SG_ seed_flags : 0|8@1+ (1,0) [0|255] "bitfield"  NODE15,MASTER,TOOL
 SG_ blockage_pct : 8|8@1+ (1,0) [0|100] "%"  NODE15,MASTER,TOOL
 SG_ slowdown_pct : 16|8@1+ (1,0) [0|100] "%"  NODE15,MASTER,TOOL
 SG_ skip_pct : 24|8@1+ (1,0) [0|100] "%"  NODE15,MASTER,TOOL
 SG_ double_pct : 32|8@1+ (1,0) [0|100] "%"  NODE15,MASTER,TOOL
 SG_ singulation_pct : 40|8@1+ (1,0) [0|100] "%"  NODE15,MASTER,TOOL
 SG_ population_x1k : 48|16@1+ (1,0) [0|65535] "x1000"  NODE15,MASTER,TOOL

BO_ 655 S1_NODE_STATUS_FAST_15: 8 NODE15
 SG_ status_flags : 0|8@1+ (1,0) [0|255] "bitfield"  NODE15,MASTER,TOOL
 SG_ error_code : 8|8@1+ (1,0) [0|255] ""  NODE15,MASTER,TOOL
 SG_ actual_rpm : 16|16@1+ (1,0) [0|10000] "rpm"  NODE15,MASTER,TOOL
 SG_ actual_pos : 32|16@1+ (1.52587890625e-05,0) [0|0.9999847412109375] "rev"  NODE15,MASTER,TOOL
 SG_ alive_counter : 48|8@1+ (1,0) [0|255] ""  NODE15,MASTER,TOOL
 SG_ sync_error : 56|8@1- (0.00390625,0) [-0.5|0.49609375] "rev"  NODE15,MASTER,TOOL

BO_ 719 S1_NODE_DIAG_15: 8 NODE15
 SG_ bus_voltage : 0|16@1+ (0.1,0) [0|6553.5] "V"  NODE15,MASTER,TOOL
 SG_ motor_current : 16|16@1- (0.1,0) [-3276.8|3276.7] "A"  NODE15,MASTER,TOOL
 SG_ controller_temp : 32|8@1+ (1,0) [0|255] "C"  NODE15,MASTER,TOOL
 SG_ motor_temp : 40|8@1+ (1,0) [0|255] "C"  NODE15,MASTER,TOOL
 SG_ fault_flags : 48|8@1+ (1,0) [0|255] "bitfield"  NODE15,MASTER,TOOL
 SG_ warning_flags : 56|8@1+ (1,0) [0|255] "bitfield"  NODE15,MASTER,TOOL

BO_ 544 S1_NODE_CMD_16: 8 MASTER
 SG_ node_command : 0|8@1+ (1,0) [0|255] ""  MASTER,TOOL
 SG_ node_flags : 8|8@1+ (1,0) [0|255] "bitfield"  MASTER,TOOL
 SG_ trim_rpm : 16|16@1- (0.1,0) [-3276.8|3276.7] "rpm"  MASTER,TOOL
 SG_ section_mask : 32|16@1+ (1,0) [0|65535] "bitmask"  MASTER,TOOL
 SG_ seq : 48|8@1+ (1,0) [0|255] ""  MASTER,TOOL
 SG_ reserved : 56|8@1+ (1,0) [0|255] ""  MASTER,TOOL

BO_ 592 S1_NODE_PRESENCE_16: 8 NODE16
 SG_ seed_flags : 0|8@1+ (1,0) [0|255] "bitfield"  NODE16,MASTER,TOOL
 SG_ blockage_pct : 8|8@1+ (1,0) [0|100] "%"  NODE16,MASTER,TOOL
 SG_ slowdown_pct : 16|8@1+ (1,0) [0|100] "%"  NODE16,MASTER,TOOL
 SG_ skip_pct : 24|8@1+ (1,0) [0|100] "%"  NODE16,MASTER,TOOL
 SG_ double_pct : 32|8@1+ (1,0) [0|100] "%"  NODE16,MASTER,TOOL
 SG_ singulation_pct : 40|8@1+ (1,0) [0|100] "%"  NODE16,MASTER,TOOL
 SG_ population_x1k : 48|16@1+ (1,0) [0|65535] "x1000"  NODE16,MASTER,TOOL

BO_ 656 S1_NODE_STATUS_FAST_16: 8 NODE16
 SG_ status_flags : 0|8@1+ (1,0) [0|255] "bitfield"  NODE16,MASTER,TOOL
 SG_ error_code : 8|8@1+ (1,0) [0|255] ""  NODE16,MASTER,TOOL
 SG_ actual_rpm : 16|16@1+ (1,0) [0|10000] "rpm"  NODE16,MASTER,TOOL
 SG_ actual_pos : 32|16@1+ (1.52587890625e-05,0) [0|0.9999847412109375] "rev"  NODE16,MASTER,TOOL
 SG_ alive_counter : 48|8@1+ (1,0) [0|255] ""  NODE16,MASTER,TOOL
 SG_ sync_error : 56|8@1- (0.00390625,0) [-0.5|0.49609375] "rev"  NODE16,MASTER,TOOL

BO_ 720 S1_NODE_DIAG_16: 8 NODE16
 SG_ bus_voltage : 0|16@1+ (0.1,0) [0|6553.5] "V"  NODE16,MASTER,TOOL
 SG_ motor_current : 16|16@1- (0.1,0) [-3276.8|3276.7] "A"  NODE16,MASTER,TOOL
 SG_ controller_temp : 32|8@1+ (1,0) [0|255] "C"  NODE16,MASTER,TOOL
 SG_ motor_temp : 40|8@1+ (1,0) [0|255] "C"  NODE16,MASTER,TOOL
 SG_ fault_flags : 48|8@1+ (1,0) [0|255] "bitfield"  NODE16,MASTER,TOOL
 SG_ warning_flags : 56|8@1+ (1,0) [0|255] "bitfield"  NODE16,MASTER,TOOL

BO_ 768 S2_GLOBAL_CONTROL: 8 MASTER
 SG_ system_mode : 0|8@1+ (1,0) [0|255] ""  MASTER,TOOL
 SG_ control_flags : 8|8@1+ (1,0) [0|255] "bitfield"  MASTER,TOOL
 SG_ ctrl_drive_enable : 8|1@1+ (1,0) [0|1] "bool"  MASTER,TOOL
 SG_ ctrl_sync_enable : 9|1@1+ (1,0) [0|1] "bool"  MASTER,TOOL
 SG_ ctrl_estop : 10|1@1+ (1,0) [0|1] "bool"  MASTER,TOOL
 SG_ ctrl_diag_enable : 11|1@1+ (1,0) [0|1] "bool"  MASTER,TOOL
 SG_ base_rpm : 16|16@1+ (1,0) [0|10000] "rpm"  MASTER,TOOL
 SG_ sync_pos : 32|16@1+ (1.52587890625e-05,0) [0|0.9999847412109375] "rev"  MASTER,TOOL
 SG_ sequence : 48|8@1+ (1,0) [0|255] ""  MASTER,TOOL
 SG_ reserved : 56|8@1+ (1,0) [0|255] ""  MASTER,TOOL

BO_ 785 S2_NODE_CMD_1: 8 MASTER
 SG_ node_command : 0|8@1+ (1,0) [0|255] ""  MASTER,TOOL
 SG_ node_flags : 8|8@1+ (1,0) [0|255] "bitfield"  MASTER,TOOL
 SG_ trim_rpm : 16|16@1- (0.1,0) [-3276.8|3276.7] "rpm"  MASTER,TOOL
 SG_ section_mask : 32|16@1+ (1,0) [0|65535] "bitmask"  MASTER,TOOL
 SG_ seq : 48|8@1+ (1,0) [0|255] ""  MASTER,TOOL
 SG_ reserved : 56|8@1+ (1,0) [0|255] ""  MASTER,TOOL

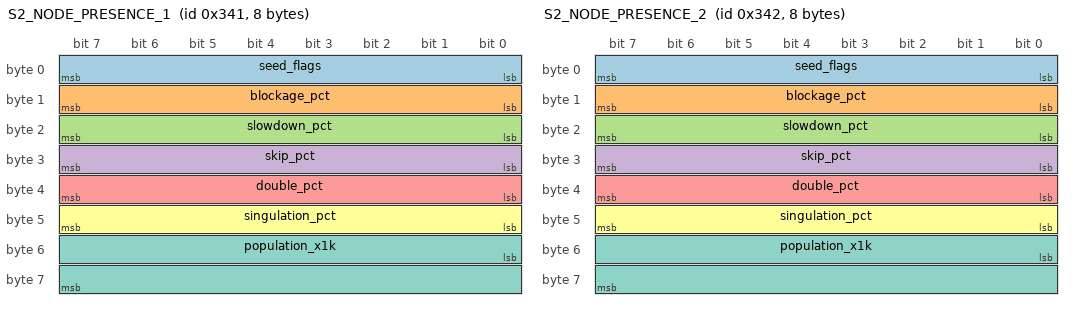
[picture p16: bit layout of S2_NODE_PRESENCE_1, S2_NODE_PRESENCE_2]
BO_ 833 S2_NODE_PRESENCE_1: 8 NODE1
 SG_ seed_flags : 0|8@1+ (1,0) [0|255] "bitfield"  NODE1,MASTER,TOOL
 SG_ blockage_pct : 8|8@1+ (1,0) [0|100] "%"  NODE1,MASTER,TOOL
 SG_ slowdown_pct : 16|8@1+ (1,0) [0|100] "%"  NODE1,MASTER,TOOL
 SG_ skip_pct : 24|8@1+ (1,0) [0|100] "%"  NODE1,MASTER,TOOL
 SG_ double_pct : 32|8@1+ (1,0) [0|100] "%"  NODE1,MASTER,TOOL
 SG_ singulation_pct : 40|8@1+ (1,0) [0|100] "%"  NODE1,MASTER,TOOL
 SG_ population_x1k : 48|16@1+ (1,0) [0|65535] "x1000"  NODE1,MASTER,TOOL

BO_ 897 S2_NODE_STATUS_FAST_1: 8 NODE1
 SG_ status_flags : 0|8@1+ (1,0) [0|255] "bitfield"  NODE1,MASTER,TOOL
 SG_ error_code : 8|8@1+ (1,0) [0|255] ""  NODE1,MASTER,TOOL
 SG_ actual_rpm : 16|16@1+ (1,0) [0|10000] "rpm"  NODE1,MASTER,TOOL
 SG_ actual_pos : 32|16@1+ (1.52587890625e-05,0) [0|0.9999847412109375] "rev"  NODE1,MASTER,TOOL
 SG_ alive_counter : 48|8@1+ (1,0) [0|255] ""  NODE1,MASTER,TOOL
 SG_ sync_error : 56|8@1- (0.00390625,0) [-0.5|0.49609375] "rev"  NODE1,MASTER,TOOL

BO_ 961 S2_NODE_DIAG_1: 8 NODE1
 SG_ bus_voltage : 0|16@1+ (0.1,0) [0|6553.5] "V"  NODE1,MASTER,TOOL
 SG_ motor_current : 16|16@1- (0.1,0) [-3276.8|3276.7] "A"  NODE1,MASTER,TOOL
 SG_ controller_temp : 32|8@1+ (1,0) [0|255] "C"  NODE1,MASTER,TOOL
 SG_ motor_temp : 40|8@1+ (1,0) [0|255] "C"  NODE1,MASTER,TOOL
 SG_ fault_flags : 48|8@1+ (1,0) [0|255] "bitfield"  NODE1,MASTER,TOOL
 SG_ warning_flags : 56|8@1+ (1,0) [0|255] "bitfield"  NODE1,MASTER,TOOL

BO_ 786 S2_NODE_CMD_2: 8 MASTER
 SG_ node_command : 0|8@1+ (1,0) [0|255] ""  MASTER,TOOL
 SG_ node_flags : 8|8@1+ (1,0) [0|255] "bitfield"  MASTER,TOOL
 SG_ trim_rpm : 16|16@1- (0.1,0) [-3276.8|3276.7] "rpm"  MASTER,TOOL
 SG_ section_mask : 32|16@1+ (1,0) [0|65535] "bitmask"  MASTER,TOOL
 SG_ seq : 48|8@1+ (1,0) [0|255] ""  MASTER,TOOL
 SG_ reserved : 56|8@1+ (1,0) [0|255] ""  MASTER,TOOL

BO_ 834 S2_NODE_PRESENCE_2: 8 NODE2
 SG_ seed_flags : 0|8@1+ (1,0) [0|255] "bitfield"  NODE2,MASTER,TOOL
 SG_ blockage_pct : 8|8@1+ (1,0) [0|100] "%"  NODE2,MASTER,TOOL
 SG_ slowdown_pct : 16|8@1+ (1,0) [0|100] "%"  NODE2,MASTER,TOOL
 SG_ skip_pct : 24|8@1+ (1,0) [0|100] "%"  NODE2,MASTER,TOOL
 SG_ double_pct : 32|8@1+ (1,0) [0|100] "%"  NODE2,MASTER,TOOL
 SG_ singulation_pct : 40|8@1+ (1,0) [0|100] "%"  NODE2,MASTER,TOOL
 SG_ population_x1k : 48|16@1+ (1,0) [0|65535] "x1000"  NODE2,MASTER,TOOL

BO_ 898 S2_NODE_STATUS_FAST_2: 8 NODE2
 SG_ status_flags : 0|8@1+ (1,0) [0|255] "bitfield"  NODE2,MASTER,TOOL
 SG_ error_code : 8|8@1+ (1,0) [0|255] ""  NODE2,MASTER,TOOL
 SG_ actual_rpm : 16|16@1+ (1,0) [0|10000] "rpm"  NODE2,MASTER,TOOL
 SG_ actual_pos : 32|16@1+ (1.52587890625e-05,0) [0|0.9999847412109375] "rev"  NODE2,MASTER,TOOL
 SG_ alive_counter : 48|8@1+ (1,0) [0|255] ""  NODE2,MASTER,TOOL
 SG_ sync_error : 56|8@1- (0.00390625,0) [-0.5|0.49609375] "rev"  NODE2,MASTER,TOOL

BO_ 962 S2_NODE_DIAG_2: 8 NODE2
 SG_ bus_voltage : 0|16@1+ (0.1,0) [0|6553.5] "V"  NODE2,MASTER,TOOL
 SG_ motor_current : 16|16@1- (0.1,0) [-3276.8|3276.7] "A"  NODE2,MASTER,TOOL
 SG_ controller_temp : 32|8@1+ (1,0) [0|255] "C"  NODE2,MASTER,TOOL
 SG_ motor_temp : 40|8@1+ (1,0) [0|255] "C"  NODE2,MASTER,TOOL
 SG_ fault_flags : 48|8@1+ (1,0) [0|255] "bitfield"  NODE2,MASTER,TOOL
 SG_ warning_flags : 56|8@1+ (1,0) [0|255] "bitfield"  NODE2,MASTER,TOOL

BO_ 787 S2_NODE_CMD_3: 8 MASTER
 SG_ node_command : 0|8@1+ (1,0) [0|255] ""  MASTER,TOOL
 SG_ node_flags : 8|8@1+ (1,0) [0|255] "bitfield"  MASTER,TOOL
 SG_ trim_rpm : 16|16@1- (0.1,0) [-3276.8|3276.7] "rpm"  MASTER,TOOL
 SG_ section_mask : 32|16@1+ (1,0) [0|65535] "bitmask"  MASTER,TOOL
 SG_ seq : 48|8@1+ (1,0) [0|255] ""  MASTER,TOOL
 SG_ reserved : 56|8@1+ (1,0) [0|255] ""  MASTER,TOOL

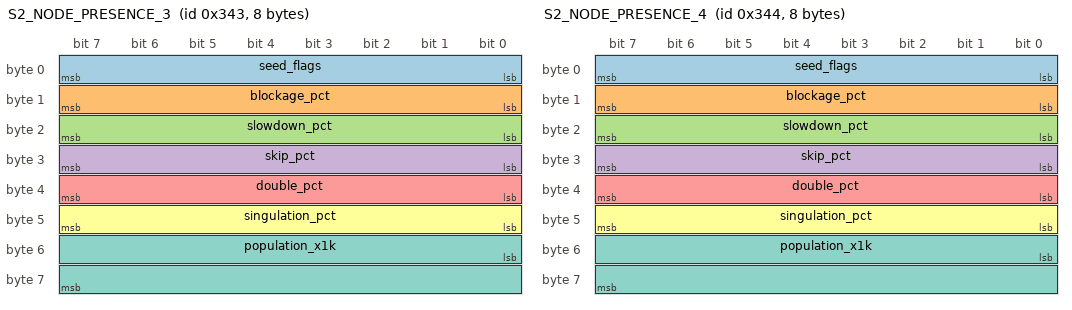
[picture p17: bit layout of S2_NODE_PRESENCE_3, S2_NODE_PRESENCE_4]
BO_ 835 S2_NODE_PRESENCE_3: 8 NODE3
 SG_ seed_flags : 0|8@1+ (1,0) [0|255] "bitfield"  NODE3,MASTER,TOOL
 SG_ blockage_pct : 8|8@1+ (1,0) [0|100] "%"  NODE3,MASTER,TOOL
 SG_ slowdown_pct : 16|8@1+ (1,0) [0|100] "%"  NODE3,MASTER,TOOL
 SG_ skip_pct : 24|8@1+ (1,0) [0|100] "%"  NODE3,MASTER,TOOL
 SG_ double_pct : 32|8@1+ (1,0) [0|100] "%"  NODE3,MASTER,TOOL
 SG_ singulation_pct : 40|8@1+ (1,0) [0|100] "%"  NODE3,MASTER,TOOL
 SG_ population_x1k : 48|16@1+ (1,0) [0|65535] "x1000"  NODE3,MASTER,TOOL

BO_ 899 S2_NODE_STATUS_FAST_3: 8 NODE3
 SG_ status_flags : 0|8@1+ (1,0) [0|255] "bitfield"  NODE3,MASTER,TOOL
 SG_ error_code : 8|8@1+ (1,0) [0|255] ""  NODE3,MASTER,TOOL
 SG_ actual_rpm : 16|16@1+ (1,0) [0|10000] "rpm"  NODE3,MASTER,TOOL
 SG_ actual_pos : 32|16@1+ (1.52587890625e-05,0) [0|0.9999847412109375] "rev"  NODE3,MASTER,TOOL
 SG_ alive_counter : 48|8@1+ (1,0) [0|255] ""  NODE3,MASTER,TOOL
 SG_ sync_error : 56|8@1- (0.00390625,0) [-0.5|0.49609375] "rev"  NODE3,MASTER,TOOL

BO_ 963 S2_NODE_DIAG_3: 8 NODE3
 SG_ bus_voltage : 0|16@1+ (0.1,0) [0|6553.5] "V"  NODE3,MASTER,TOOL
 SG_ motor_current : 16|16@1- (0.1,0) [-3276.8|3276.7] "A"  NODE3,MASTER,TOOL
 SG_ controller_temp : 32|8@1+ (1,0) [0|255] "C"  NODE3,MASTER,TOOL
 SG_ motor_temp : 40|8@1+ (1,0) [0|255] "C"  NODE3,MASTER,TOOL
 SG_ fault_flags : 48|8@1+ (1,0) [0|255] "bitfield"  NODE3,MASTER,TOOL
 SG_ warning_flags : 56|8@1+ (1,0) [0|255] "bitfield"  NODE3,MASTER,TOOL

BO_ 788 S2_NODE_CMD_4: 8 MASTER
 SG_ node_command : 0|8@1+ (1,0) [0|255] ""  MASTER,TOOL
 SG_ node_flags : 8|8@1+ (1,0) [0|255] "bitfield"  MASTER,TOOL
 SG_ trim_rpm : 16|16@1- (0.1,0) [-3276.8|3276.7] "rpm"  MASTER,TOOL
 SG_ section_mask : 32|16@1+ (1,0) [0|65535] "bitmask"  MASTER,TOOL
 SG_ seq : 48|8@1+ (1,0) [0|255] ""  MASTER,TOOL
 SG_ reserved : 56|8@1+ (1,0) [0|255] ""  MASTER,TOOL

BO_ 836 S2_NODE_PRESENCE_4: 8 NODE4
 SG_ seed_flags : 0|8@1+ (1,0) [0|255] "bitfield"  NODE4,MASTER,TOOL
 SG_ blockage_pct : 8|8@1+ (1,0) [0|100] "%"  NODE4,MASTER,TOOL
 SG_ slowdown_pct : 16|8@1+ (1,0) [0|100] "%"  NODE4,MASTER,TOOL
 SG_ skip_pct : 24|8@1+ (1,0) [0|100] "%"  NODE4,MASTER,TOOL
 SG_ double_pct : 32|8@1+ (1,0) [0|100] "%"  NODE4,MASTER,TOOL
 SG_ singulation_pct : 40|8@1+ (1,0) [0|100] "%"  NODE4,MASTER,TOOL
 SG_ population_x1k : 48|16@1+ (1,0) [0|65535] "x1000"  NODE4,MASTER,TOOL

BO_ 900 S2_NODE_STATUS_FAST_4: 8 NODE4
 SG_ status_flags : 0|8@1+ (1,0) [0|255] "bitfield"  NODE4,MASTER,TOOL
 SG_ error_code : 8|8@1+ (1,0) [0|255] ""  NODE4,MASTER,TOOL
 SG_ actual_rpm : 16|16@1+ (1,0) [0|10000] "rpm"  NODE4,MASTER,TOOL
 SG_ actual_pos : 32|16@1+ (1.52587890625e-05,0) [0|0.9999847412109375] "rev"  NODE4,MASTER,TOOL
 SG_ alive_counter : 48|8@1+ (1,0) [0|255] ""  NODE4,MASTER,TOOL
 SG_ sync_error : 56|8@1- (0.00390625,0) [-0.5|0.49609375] "rev"  NODE4,MASTER,TOOL

BO_ 964 S2_NODE_DIAG_4: 8 NODE4
 SG_ bus_voltage : 0|16@1+ (0.1,0) [0|6553.5] "V"  NODE4,MASTER,TOOL
 SG_ motor_current : 16|16@1- (0.1,0) [-3276.8|3276.7] "A"  NODE4,MASTER,TOOL
 SG_ controller_temp : 32|8@1+ (1,0) [0|255] "C"  NODE4,MASTER,TOOL
 SG_ motor_temp : 40|8@1+ (1,0) [0|255] "C"  NODE4,MASTER,TOOL
 SG_ fault_flags : 48|8@1+ (1,0) [0|255] "bitfield"  NODE4,MASTER,TOOL
 SG_ warning_flags : 56|8@1+ (1,0) [0|255] "bitfield"  NODE4,MASTER,TOOL

BO_ 789 S2_NODE_CMD_5: 8 MASTER
 SG_ node_command : 0|8@1+ (1,0) [0|255] ""  MASTER,TOOL
 SG_ node_flags : 8|8@1+ (1,0) [0|255] "bitfield"  MASTER,TOOL
 SG_ trim_rpm : 16|16@1- (0.1,0) [-3276.8|3276.7] "rpm"  MASTER,TOOL
 SG_ section_mask : 32|16@1+ (1,0) [0|65535] "bitmask"  MASTER,TOOL
 SG_ seq : 48|8@1+ (1,0) [0|255] ""  MASTER,TOOL
 SG_ reserved : 56|8@1+ (1,0) [0|255] ""  MASTER,TOOL

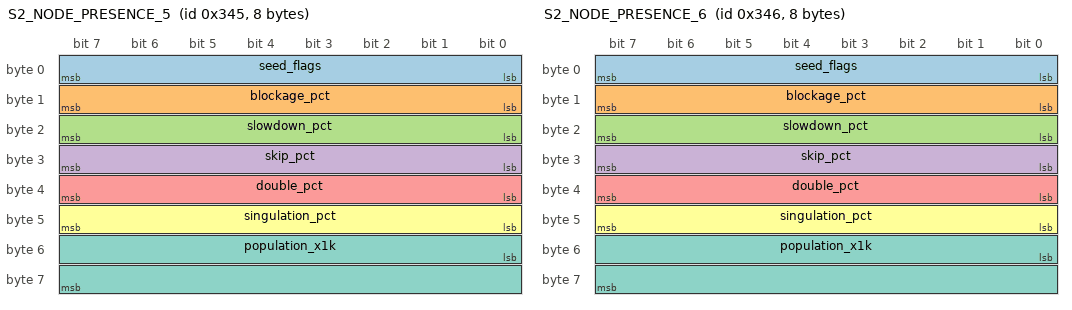
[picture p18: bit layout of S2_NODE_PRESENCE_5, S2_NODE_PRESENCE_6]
BO_ 837 S2_NODE_PRESENCE_5: 8 NODE5
 SG_ seed_flags : 0|8@1+ (1,0) [0|255] "bitfield"  NODE5,MASTER,TOOL
 SG_ blockage_pct : 8|8@1+ (1,0) [0|100] "%"  NODE5,MASTER,TOOL
 SG_ slowdown_pct : 16|8@1+ (1,0) [0|100] "%"  NODE5,MASTER,TOOL
 SG_ skip_pct : 24|8@1+ (1,0) [0|100] "%"  NODE5,MASTER,TOOL
 SG_ double_pct : 32|8@1+ (1,0) [0|100] "%"  NODE5,MASTER,TOOL
 SG_ singulation_pct : 40|8@1+ (1,0) [0|100] "%"  NODE5,MASTER,TOOL
 SG_ population_x1k : 48|16@1+ (1,0) [0|65535] "x1000"  NODE5,MASTER,TOOL

BO_ 901 S2_NODE_STATUS_FAST_5: 8 NODE5
 SG_ status_flags : 0|8@1+ (1,0) [0|255] "bitfield"  NODE5,MASTER,TOOL
 SG_ error_code : 8|8@1+ (1,0) [0|255] ""  NODE5,MASTER,TOOL
 SG_ actual_rpm : 16|16@1+ (1,0) [0|10000] "rpm"  NODE5,MASTER,TOOL
 SG_ actual_pos : 32|16@1+ (1.52587890625e-05,0) [0|0.9999847412109375] "rev"  NODE5,MASTER,TOOL
 SG_ alive_counter : 48|8@1+ (1,0) [0|255] ""  NODE5,MASTER,TOOL
 SG_ sync_error : 56|8@1- (0.00390625,0) [-0.5|0.49609375] "rev"  NODE5,MASTER,TOOL

BO_ 965 S2_NODE_DIAG_5: 8 NODE5
 SG_ bus_voltage : 0|16@1+ (0.1,0) [0|6553.5] "V"  NODE5,MASTER,TOOL
 SG_ motor_current : 16|16@1- (0.1,0) [-3276.8|3276.7] "A"  NODE5,MASTER,TOOL
 SG_ controller_temp : 32|8@1+ (1,0) [0|255] "C"  NODE5,MASTER,TOOL
 SG_ motor_temp : 40|8@1+ (1,0) [0|255] "C"  NODE5,MASTER,TOOL
 SG_ fault_flags : 48|8@1+ (1,0) [0|255] "bitfield"  NODE5,MASTER,TOOL
 SG_ warning_flags : 56|8@1+ (1,0) [0|255] "bitfield"  NODE5,MASTER,TOOL

BO_ 790 S2_NODE_CMD_6: 8 MASTER
 SG_ node_command : 0|8@1+ (1,0) [0|255] ""  MASTER,TOOL
 SG_ node_flags : 8|8@1+ (1,0) [0|255] "bitfield"  MASTER,TOOL
 SG_ trim_rpm : 16|16@1- (0.1,0) [-3276.8|3276.7] "rpm"  MASTER,TOOL
 SG_ section_mask : 32|16@1+ (1,0) [0|65535] "bitmask"  MASTER,TOOL
 SG_ seq : 48|8@1+ (1,0) [0|255] ""  MASTER,TOOL
 SG_ reserved : 56|8@1+ (1,0) [0|255] ""  MASTER,TOOL

BO_ 838 S2_NODE_PRESENCE_6: 8 NODE6
 SG_ seed_flags : 0|8@1+ (1,0) [0|255] "bitfield"  NODE6,MASTER,TOOL
 SG_ blockage_pct : 8|8@1+ (1,0) [0|100] "%"  NODE6,MASTER,TOOL
 SG_ slowdown_pct : 16|8@1+ (1,0) [0|100] "%"  NODE6,MASTER,TOOL
 SG_ skip_pct : 24|8@1+ (1,0) [0|100] "%"  NODE6,MASTER,TOOL
 SG_ double_pct : 32|8@1+ (1,0) [0|100] "%"  NODE6,MASTER,TOOL
 SG_ singulation_pct : 40|8@1+ (1,0) [0|100] "%"  NODE6,MASTER,TOOL
 SG_ population_x1k : 48|16@1+ (1,0) [0|65535] "x1000"  NODE6,MASTER,TOOL

BO_ 902 S2_NODE_STATUS_FAST_6: 8 NODE6
 SG_ status_flags : 0|8@1+ (1,0) [0|255] "bitfield"  NODE6,MASTER,TOOL
 SG_ error_code : 8|8@1+ (1,0) [0|255] ""  NODE6,MASTER,TOOL
 SG_ actual_rpm : 16|16@1+ (1,0) [0|10000] "rpm"  NODE6,MASTER,TOOL
 SG_ actual_pos : 32|16@1+ (1.52587890625e-05,0) [0|0.9999847412109375] "rev"  NODE6,MASTER,TOOL
 SG_ alive_counter : 48|8@1+ (1,0) [0|255] ""  NODE6,MASTER,TOOL
 SG_ sync_error : 56|8@1- (0.00390625,0) [-0.5|0.49609375] "rev"  NODE6,MASTER,TOOL

BO_ 966 S2_NODE_DIAG_6: 8 NODE6
 SG_ bus_voltage : 0|16@1+ (0.1,0) [0|6553.5] "V"  NODE6,MASTER,TOOL
 SG_ motor_current : 16|16@1- (0.1,0) [-3276.8|3276.7] "A"  NODE6,MASTER,TOOL
 SG_ controller_temp : 32|8@1+ (1,0) [0|255] "C"  NODE6,MASTER,TOOL
 SG_ motor_temp : 40|8@1+ (1,0) [0|255] "C"  NODE6,MASTER,TOOL
 SG_ fault_flags : 48|8@1+ (1,0) [0|255] "bitfield"  NODE6,MASTER,TOOL
 SG_ warning_flags : 56|8@1+ (1,0) [0|255] "bitfield"  NODE6,MASTER,TOOL

BO_ 791 S2_NODE_CMD_7: 8 MASTER
 SG_ node_command : 0|8@1+ (1,0) [0|255] ""  MASTER,TOOL
 SG_ node_flags : 8|8@1+ (1,0) [0|255] "bitfield"  MASTER,TOOL
 SG_ trim_rpm : 16|16@1- (0.1,0) [-3276.8|3276.7] "rpm"  MASTER,TOOL
 SG_ section_mask : 32|16@1+ (1,0) [0|65535] "bitmask"  MASTER,TOOL
 SG_ seq : 48|8@1+ (1,0) [0|255] ""  MASTER,TOOL
 SG_ reserved : 56|8@1+ (1,0) [0|255] ""  MASTER,TOOL

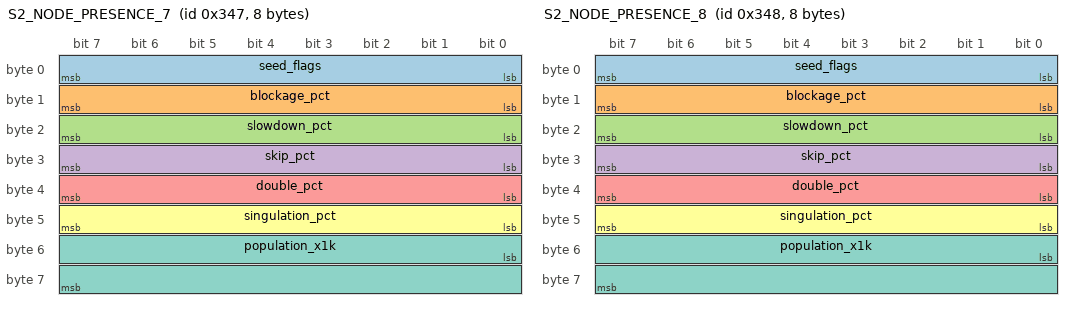
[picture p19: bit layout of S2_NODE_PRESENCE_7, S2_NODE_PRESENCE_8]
BO_ 839 S2_NODE_PRESENCE_7: 8 NODE7
 SG_ seed_flags : 0|8@1+ (1,0) [0|255] "bitfield"  NODE7,MASTER,TOOL
 SG_ blockage_pct : 8|8@1+ (1,0) [0|100] "%"  NODE7,MASTER,TOOL
 SG_ slowdown_pct : 16|8@1+ (1,0) [0|100] "%"  NODE7,MASTER,TOOL
 SG_ skip_pct : 24|8@1+ (1,0) [0|100] "%"  NODE7,MASTER,TOOL
 SG_ double_pct : 32|8@1+ (1,0) [0|100] "%"  NODE7,MASTER,TOOL
 SG_ singulation_pct : 40|8@1+ (1,0) [0|100] "%"  NODE7,MASTER,TOOL
 SG_ population_x1k : 48|16@1+ (1,0) [0|65535] "x1000"  NODE7,MASTER,TOOL

BO_ 903 S2_NODE_STATUS_FAST_7: 8 NODE7
 SG_ status_flags : 0|8@1+ (1,0) [0|255] "bitfield"  NODE7,MASTER,TOOL
 SG_ error_code : 8|8@1+ (1,0) [0|255] ""  NODE7,MASTER,TOOL
 SG_ actual_rpm : 16|16@1+ (1,0) [0|10000] "rpm"  NODE7,MASTER,TOOL
 SG_ actual_pos : 32|16@1+ (1.52587890625e-05,0) [0|0.9999847412109375] "rev"  NODE7,MASTER,TOOL
 SG_ alive_counter : 48|8@1+ (1,0) [0|255] ""  NODE7,MASTER,TOOL
 SG_ sync_error : 56|8@1- (0.00390625,0) [-0.5|0.49609375] "rev"  NODE7,MASTER,TOOL

BO_ 967 S2_NODE_DIAG_7: 8 NODE7
 SG_ bus_voltage : 0|16@1+ (0.1,0) [0|6553.5] "V"  NODE7,MASTER,TOOL
 SG_ motor_current : 16|16@1- (0.1,0) [-3276.8|3276.7] "A"  NODE7,MASTER,TOOL
 SG_ controller_temp : 32|8@1+ (1,0) [0|255] "C"  NODE7,MASTER,TOOL
 SG_ motor_temp : 40|8@1+ (1,0) [0|255] "C"  NODE7,MASTER,TOOL
 SG_ fault_flags : 48|8@1+ (1,0) [0|255] "bitfield"  NODE7,MASTER,TOOL
 SG_ warning_flags : 56|8@1+ (1,0) [0|255] "bitfield"  NODE7,MASTER,TOOL

BO_ 792 S2_NODE_CMD_8: 8 MASTER
 SG_ node_command : 0|8@1+ (1,0) [0|255] ""  MASTER,TOOL
 SG_ node_flags : 8|8@1+ (1,0) [0|255] "bitfield"  MASTER,TOOL
 SG_ trim_rpm : 16|16@1- (0.1,0) [-3276.8|3276.7] "rpm"  MASTER,TOOL
 SG_ section_mask : 32|16@1+ (1,0) [0|65535] "bitmask"  MASTER,TOOL
 SG_ seq : 48|8@1+ (1,0) [0|255] ""  MASTER,TOOL
 SG_ reserved : 56|8@1+ (1,0) [0|255] ""  MASTER,TOOL

BO_ 840 S2_NODE_PRESENCE_8: 8 NODE8
 SG_ seed_flags : 0|8@1+ (1,0) [0|255] "bitfield"  NODE8,MASTER,TOOL
 SG_ blockage_pct : 8|8@1+ (1,0) [0|100] "%"  NODE8,MASTER,TOOL
 SG_ slowdown_pct : 16|8@1+ (1,0) [0|100] "%"  NODE8,MASTER,TOOL
 SG_ skip_pct : 24|8@1+ (1,0) [0|100] "%"  NODE8,MASTER,TOOL
 SG_ double_pct : 32|8@1+ (1,0) [0|100] "%"  NODE8,MASTER,TOOL
 SG_ singulation_pct : 40|8@1+ (1,0) [0|100] "%"  NODE8,MASTER,TOOL
 SG_ population_x1k : 48|16@1+ (1,0) [0|65535] "x1000"  NODE8,MASTER,TOOL

BO_ 904 S2_NODE_STATUS_FAST_8: 8 NODE8
 SG_ status_flags : 0|8@1+ (1,0) [0|255] "bitfield"  NODE8,MASTER,TOOL
 SG_ error_code : 8|8@1+ (1,0) [0|255] ""  NODE8,MASTER,TOOL
 SG_ actual_rpm : 16|16@1+ (1,0) [0|10000] "rpm"  NODE8,MASTER,TOOL
 SG_ actual_pos : 32|16@1+ (1.52587890625e-05,0) [0|0.9999847412109375] "rev"  NODE8,MASTER,TOOL
 SG_ alive_counter : 48|8@1+ (1,0) [0|255] ""  NODE8,MASTER,TOOL
 SG_ sync_error : 56|8@1- (0.00390625,0) [-0.5|0.49609375] "rev"  NODE8,MASTER,TOOL

BO_ 968 S2_NODE_DIAG_8: 8 NODE8
 SG_ bus_voltage : 0|16@1+ (0.1,0) [0|6553.5] "V"  NODE8,MASTER,TOOL
 SG_ motor_current : 16|16@1- (0.1,0) [-3276.8|3276.7] "A"  NODE8,MASTER,TOOL
 SG_ controller_temp : 32|8@1+ (1,0) [0|255] "C"  NODE8,MASTER,TOOL
 SG_ motor_temp : 40|8@1+ (1,0) [0|255] "C"  NODE8,MASTER,TOOL
 SG_ fault_flags : 48|8@1+ (1,0) [0|255] "bitfield"  NODE8,MASTER,TOOL
 SG_ warning_flags : 56|8@1+ (1,0) [0|255] "bitfield"  NODE8,MASTER,TOOL

BO_ 793 S2_NODE_CMD_9: 8 MASTER
 SG_ node_command : 0|8@1+ (1,0) [0|255] ""  MASTER,TOOL
 SG_ node_flags : 8|8@1+ (1,0) [0|255] "bitfield"  MASTER,TOOL
 SG_ trim_rpm : 16|16@1- (0.1,0) [-3276.8|3276.7] "rpm"  MASTER,TOOL
 SG_ section_mask : 32|16@1+ (1,0) [0|65535] "bitmask"  MASTER,TOOL
 SG_ seq : 48|8@1+ (1,0) [0|255] ""  MASTER,TOOL
 SG_ reserved : 56|8@1+ (1,0) [0|255] ""  MASTER,TOOL

BO_ 841 S2_NODE_PRESENCE_9: 8 NODE9
 SG_ seed_flags : 0|8@1+ (1,0) [0|255] "bitfield"  NODE9,MASTER,TOOL
 SG_ blockage_pct : 8|8@1+ (1,0) [0|100] "%"  NODE9,MASTER,TOOL
 SG_ slowdown_pct : 16|8@1+ (1,0) [0|100] "%"  NODE9,MASTER,TOOL
 SG_ skip_pct : 24|8@1+ (1,0) [0|100] "%"  NODE9,MASTER,TOOL
 SG_ double_pct : 32|8@1+ (1,0) [0|100] "%"  NODE9,MASTER,TOOL
 SG_ singulation_pct : 40|8@1+ (1,0) [0|100] "%"  NODE9,MASTER,TOOL
 SG_ population_x1k : 48|16@1+ (1,0) [0|65535] "x1000"  NODE9,MASTER,TOOL

BO_ 905 S2_NODE_STATUS_FAST_9: 8 NODE9
 SG_ status_flags : 0|8@1+ (1,0) [0|255] "bitfield"  NODE9,MASTER,TOOL
 SG_ error_code : 8|8@1+ (1,0) [0|255] ""  NODE9,MASTER,TOOL
 SG_ actual_rpm : 16|16@1+ (1,0) [0|10000] "rpm"  NODE9,MASTER,TOOL
 SG_ actual_pos : 32|16@1+ (1.52587890625e-05,0) [0|0.9999847412109375] "rev"  NODE9,MASTER,TOOL
 SG_ alive_counter : 48|8@1+ (1,0) [0|255] ""  NODE9,MASTER,TOOL
 SG_ sync_error : 56|8@1- (0.00390625,0) [-0.5|0.49609375] "rev"  NODE9,MASTER,TOOL

BO_ 969 S2_NODE_DIAG_9: 8 NODE9
 SG_ bus_voltage : 0|16@1+ (0.1,0) [0|6553.5] "V"  NODE9,MASTER,TOOL
 SG_ motor_current : 16|16@1- (0.1,0) [-3276.8|3276.7] "A"  NODE9,MASTER,TOOL
 SG_ controller_temp : 32|8@1+ (1,0) [0|255] "C"  NODE9,MASTER,TOOL
 SG_ motor_temp : 40|8@1+ (1,0) [0|255] "C"  NODE9,MASTER,TOOL
 SG_ fault_flags : 48|8@1+ (1,0) [0|255] "bitfield"  NODE9,MASTER,TOOL
 SG_ warning_flags : 56|8@1+ (1,0) [0|255] "bitfield"  NODE9,MASTER,TOOL

BO_ 794 S2_NODE_CMD_10: 8 MASTER
 SG_ node_command : 0|8@1+ (1,0) [0|255] ""  MASTER,TOOL
 SG_ node_flags : 8|8@1+ (1,0) [0|255] "bitfield"  MASTER,TOOL
 SG_ trim_rpm : 16|16@1- (0.1,0) [-3276.8|3276.7] "rpm"  MASTER,TOOL
 SG_ section_mask : 32|16@1+ (1,0) [0|65535] "bitmask"  MASTER,TOOL
 SG_ seq : 48|8@1+ (1,0) [0|255] ""  MASTER,TOOL
 SG_ reserved : 56|8@1+ (1,0) [0|255] ""  MASTER,TOOL

BO_ 842 S2_NODE_PRESENCE_10: 8 NODE10
 SG_ seed_flags : 0|8@1+ (1,0) [0|255] "bitfield"  NODE10,MASTER,TOOL
 SG_ blockage_pct : 8|8@1+ (1,0) [0|100] "%"  NODE10,MASTER,TOOL
 SG_ slowdown_pct : 16|8@1+ (1,0) [0|100] "%"  NODE10,MASTER,TOOL
 SG_ skip_pct : 24|8@1+ (1,0) [0|100] "%"  NODE10,MASTER,TOOL
 SG_ double_pct : 32|8@1+ (1,0) [0|100] "%"  NODE10,MASTER,TOOL
 SG_ singulation_pct : 40|8@1+ (1,0) [0|100] "%"  NODE10,MASTER,TOOL
 SG_ population_x1k : 48|16@1+ (1,0) [0|65535] "x1000"  NODE10,MASTER,TOOL

BO_ 906 S2_NODE_STATUS_FAST_10: 8 NODE10
 SG_ status_flags : 0|8@1+ (1,0) [0|255] "bitfield"  NODE10,MASTER,TOOL
 SG_ error_code : 8|8@1+ (1,0) [0|255] ""  NODE10,MASTER,TOOL
 SG_ actual_rpm : 16|16@1+ (1,0) [0|10000] "rpm"  NODE10,MASTER,TOOL
 SG_ actual_pos : 32|16@1+ (1.52587890625e-05,0) [0|0.9999847412109375] "rev"  NODE10,MASTER,TOOL
 SG_ alive_counter : 48|8@1+ (1,0) [0|255] ""  NODE10,MASTER,TOOL
 SG_ sync_error : 56|8@1- (0.00390625,0) [-0.5|0.49609375] "rev"  NODE10,MASTER,TOOL

BO_ 970 S2_NODE_DIAG_10: 8 NODE10
 SG_ bus_voltage : 0|16@1+ (0.1,0) [0|6553.5] "V"  NODE10,MASTER,TOOL
 SG_ motor_current : 16|16@1- (0.1,0) [-3276.8|3276.7] "A"  NODE10,MASTER,TOOL
 SG_ controller_temp : 32|8@1+ (1,0) [0|255] "C"  NODE10,MASTER,TOOL
 SG_ motor_temp : 40|8@1+ (1,0) [0|255] "C"  NODE10,MASTER,TOOL
 SG_ fault_flags : 48|8@1+ (1,0) [0|255] "bitfield"  NODE10,MASTER,TOOL
 SG_ warning_flags : 56|8@1+ (1,0) [0|255] "bitfield"  NODE10,MASTER,TOOL

BO_ 795 S2_NODE_CMD_11: 8 MASTER
 SG_ node_command : 0|8@1+ (1,0) [0|255] ""  MASTER,TOOL
 SG_ node_flags : 8|8@1+ (1,0) [0|255] "bitfield"  MASTER,TOOL
 SG_ trim_rpm : 16|16@1- (0.1,0) [-3276.8|3276.7] "rpm"  MASTER,TOOL
 SG_ section_mask : 32|16@1+ (1,0) [0|65535] "bitmask"  MASTER,TOOL
 SG_ seq : 48|8@1+ (1,0) [0|255] ""  MASTER,TOOL
 SG_ reserved : 56|8@1+ (1,0) [0|255] ""  MASTER,TOOL

BO_ 843 S2_NODE_PRESENCE_11: 8 NODE11
 SG_ seed_flags : 0|8@1+ (1,0) [0|255] "bitfield"  NODE11,MASTER,TOOL
 SG_ blockage_pct : 8|8@1+ (1,0) [0|100] "%"  NODE11,MASTER,TOOL
 SG_ slowdown_pct : 16|8@1+ (1,0) [0|100] "%"  NODE11,MASTER,TOOL
 SG_ skip_pct : 24|8@1+ (1,0) [0|100] "%"  NODE11,MASTER,TOOL
 SG_ double_pct : 32|8@1+ (1,0) [0|100] "%"  NODE11,MASTER,TOOL
 SG_ singulation_pct : 40|8@1+ (1,0) [0|100] "%"  NODE11,MASTER,TOOL
 SG_ population_x1k : 48|16@1+ (1,0) [0|65535] "x1000"  NODE11,MASTER,TOOL

BO_ 907 S2_NODE_STATUS_FAST_11: 8 NODE11
 SG_ status_flags : 0|8@1+ (1,0) [0|255] "bitfield"  NODE11,MASTER,TOOL
 SG_ error_code : 8|8@1+ (1,0) [0|255] ""  NODE11,MASTER,TOOL
 SG_ actual_rpm : 16|16@1+ (1,0) [0|10000] "rpm"  NODE11,MASTER,TOOL
 SG_ actual_pos : 32|16@1+ (1.52587890625e-05,0) [0|0.9999847412109375] "rev"  NODE11,MASTER,TOOL
 SG_ alive_counter : 48|8@1+ (1,0) [0|255] ""  NODE11,MASTER,TOOL
 SG_ sync_error : 56|8@1- (0.00390625,0) [-0.5|0.49609375] "rev"  NODE11,MASTER,TOOL

BO_ 971 S2_NODE_DIAG_11: 8 NODE11
 SG_ bus_voltage : 0|16@1+ (0.1,0) [0|6553.5] "V"  NODE11,MASTER,TOOL
 SG_ motor_current : 16|16@1- (0.1,0) [-3276.8|3276.7] "A"  NODE11,MASTER,TOOL
 SG_ controller_temp : 32|8@1+ (1,0) [0|255] "C"  NODE11,MASTER,TOOL
 SG_ motor_temp : 40|8@1+ (1,0) [0|255] "C"  NODE11,MASTER,TOOL
 SG_ fault_flags : 48|8@1+ (1,0) [0|255] "bitfield"  NODE11,MASTER,TOOL
 SG_ warning_flags : 56|8@1+ (1,0) [0|255] "bitfield"  NODE11,MASTER,TOOL

BO_ 796 S2_NODE_CMD_12: 8 MASTER
 SG_ node_command : 0|8@1+ (1,0) [0|255] ""  MASTER,TOOL
 SG_ node_flags : 8|8@1+ (1,0) [0|255] "bitfield"  MASTER,TOOL
 SG_ trim_rpm : 16|16@1- (0.1,0) [-3276.8|3276.7] "rpm"  MASTER,TOOL
 SG_ section_mask : 32|16@1+ (1,0) [0|65535] "bitmask"  MASTER,TOOL
 SG_ seq : 48|8@1+ (1,0) [0|255] ""  MASTER,TOOL
 SG_ reserved : 56|8@1+ (1,0) [0|255] ""  MASTER,TOOL

BO_ 844 S2_NODE_PRESENCE_12: 8 NODE12
 SG_ seed_flags : 0|8@1+ (1,0) [0|255] "bitfield"  NODE12,MASTER,TOOL
 SG_ blockage_pct : 8|8@1+ (1,0) [0|100] "%"  NODE12,MASTER,TOOL
 SG_ slowdown_pct : 16|8@1+ (1,0) [0|100] "%"  NODE12,MASTER,TOOL
 SG_ skip_pct : 24|8@1+ (1,0) [0|100] "%"  NODE12,MASTER,TOOL
 SG_ double_pct : 32|8@1+ (1,0) [0|100] "%"  NODE12,MASTER,TOOL
 SG_ singulation_pct : 40|8@1+ (1,0) [0|100] "%"  NODE12,MASTER,TOOL
 SG_ population_x1k : 48|16@1+ (1,0) [0|65535] "x1000"  NODE12,MASTER,TOOL

BO_ 908 S2_NODE_STATUS_FAST_12: 8 NODE12
 SG_ status_flags : 0|8@1+ (1,0) [0|255] "bitfield"  NODE12,MASTER,TOOL
 SG_ error_code : 8|8@1+ (1,0) [0|255] ""  NODE12,MASTER,TOOL
 SG_ actual_rpm : 16|16@1+ (1,0) [0|10000] "rpm"  NODE12,MASTER,TOOL
 SG_ actual_pos : 32|16@1+ (1.52587890625e-05,0) [0|0.9999847412109375] "rev"  NODE12,MASTER,TOOL
 SG_ alive_counter : 48|8@1+ (1,0) [0|255] ""  NODE12,MASTER,TOOL
 SG_ sync_error : 56|8@1- (0.00390625,0) [-0.5|0.49609375] "rev"  NODE12,MASTER,TOOL

BO_ 972 S2_NODE_DIAG_12: 8 NODE12
 SG_ bus_voltage : 0|16@1+ (0.1,0) [0|6553.5] "V"  NODE12,MASTER,TOOL
 SG_ motor_current : 16|16@1- (0.1,0) [-3276.8|3276.7] "A"  NODE12,MASTER,TOOL
 SG_ controller_temp : 32|8@1+ (1,0) [0|255] "C"  NODE12,MASTER,TOOL
 SG_ motor_temp : 40|8@1+ (1,0) [0|255] "C"  NODE12,MASTER,TOOL
 SG_ fault_flags : 48|8@1+ (1,0) [0|255] "bitfield"  NODE12,MASTER,TOOL
 SG_ warning_flags : 56|8@1+ (1,0) [0|255] "bitfield"  NODE12,MASTER,TOOL

BO_ 797 S2_NODE_CMD_13: 8 MASTER
 SG_ node_command : 0|8@1+ (1,0) [0|255] ""  MASTER,TOOL
 SG_ node_flags : 8|8@1+ (1,0) [0|255] "bitfield"  MASTER,TOOL
 SG_ trim_rpm : 16|16@1- (0.1,0) [-3276.8|3276.7] "rpm"  MASTER,TOOL
 SG_ section_mask : 32|16@1+ (1,0) [0|65535] "bitmask"  MASTER,TOOL
 SG_ seq : 48|8@1+ (1,0) [0|255] ""  MASTER,TOOL
 SG_ reserved : 56|8@1+ (1,0) [0|255] ""  MASTER,TOOL

BO_ 845 S2_NODE_PRESENCE_13: 8 NODE13
 SG_ seed_flags : 0|8@1+ (1,0) [0|255] "bitfield"  NODE13,MASTER,TOOL
 SG_ blockage_pct : 8|8@1+ (1,0) [0|100] "%"  NODE13,MASTER,TOOL
 SG_ slowdown_pct : 16|8@1+ (1,0) [0|100] "%"  NODE13,MASTER,TOOL
 SG_ skip_pct : 24|8@1+ (1,0) [0|100] "%"  NODE13,MASTER,TOOL
 SG_ double_pct : 32|8@1+ (1,0) [0|100] "%"  NODE13,MASTER,TOOL
 SG_ singulation_pct : 40|8@1+ (1,0) [0|100] "%"  NODE13,MASTER,TOOL
 SG_ population_x1k : 48|16@1+ (1,0) [0|65535] "x1000"  NODE13,MASTER,TOOL

BO_ 909 S2_NODE_STATUS_FAST_13: 8 NODE13
 SG_ status_flags : 0|8@1+ (1,0) [0|255] "bitfield"  NODE13,MASTER,TOOL
 SG_ error_code : 8|8@1+ (1,0) [0|255] ""  NODE13,MASTER,TOOL
 SG_ actual_rpm : 16|16@1+ (1,0) [0|10000] "rpm"  NODE13,MASTER,TOOL
 SG_ actual_pos : 32|16@1+ (1.52587890625e-05,0) [0|0.9999847412109375] "rev"  NODE13,MASTER,TOOL
 SG_ alive_counter : 48|8@1+ (1,0) [0|255] ""  NODE13,MASTER,TOOL
 SG_ sync_error : 56|8@1- (0.00390625,0) [-0.5|0.49609375] "rev"  NODE13,MASTER,TOOL

BO_ 973 S2_NODE_DIAG_13: 8 NODE13
 SG_ bus_voltage : 0|16@1+ (0.1,0) [0|6553.5] "V"  NODE13,MASTER,TOOL
 SG_ motor_current : 16|16@1- (0.1,0) [-3276.8|3276.7] "A"  NODE13,MASTER,TOOL
 SG_ controller_temp : 32|8@1+ (1,0) [0|255] "C"  NODE13,MASTER,TOOL
 SG_ motor_temp : 40|8@1+ (1,0) [0|255] "C"  NODE13,MASTER,TOOL
 SG_ fault_flags : 48|8@1+ (1,0) [0|255] "bitfield"  NODE13,MASTER,TOOL
 SG_ warning_flags : 56|8@1+ (1,0) [0|255] "bitfield"  NODE13,MASTER,TOOL

BO_ 798 S2_NODE_CMD_14: 8 MASTER
 SG_ node_command : 0|8@1+ (1,0) [0|255] ""  MASTER,TOOL
 SG_ node_flags : 8|8@1+ (1,0) [0|255] "bitfield"  MASTER,TOOL
 SG_ trim_rpm : 16|16@1- (0.1,0) [-3276.8|3276.7] "rpm"  MASTER,TOOL
 SG_ section_mask : 32|16@1+ (1,0) [0|65535] "bitmask"  MASTER,TOOL
 SG_ seq : 48|8@1+ (1,0) [0|255] ""  MASTER,TOOL
 SG_ reserved : 56|8@1+ (1,0) [0|255] ""  MASTER,TOOL

BO_ 846 S2_NODE_PRESENCE_14: 8 NODE14
 SG_ seed_flags : 0|8@1+ (1,0) [0|255] "bitfield"  NODE14,MASTER,TOOL
 SG_ blockage_pct : 8|8@1+ (1,0) [0|100] "%"  NODE14,MASTER,TOOL
 SG_ slowdown_pct : 16|8@1+ (1,0) [0|100] "%"  NODE14,MASTER,TOOL
 SG_ skip_pct : 24|8@1+ (1,0) [0|100] "%"  NODE14,MASTER,TOOL
 SG_ double_pct : 32|8@1+ (1,0) [0|100] "%"  NODE14,MASTER,TOOL
 SG_ singulation_pct : 40|8@1+ (1,0) [0|100] "%"  NODE14,MASTER,TOOL
 SG_ population_x1k : 48|16@1+ (1,0) [0|65535] "x1000"  NODE14,MASTER,TOOL

BO_ 910 S2_NODE_STATUS_FAST_14: 8 NODE14
 SG_ status_flags : 0|8@1+ (1,0) [0|255] "bitfield"  NODE14,MASTER,TOOL
 SG_ error_code : 8|8@1+ (1,0) [0|255] ""  NODE14,MASTER,TOOL
 SG_ actual_rpm : 16|16@1+ (1,0) [0|10000] "rpm"  NODE14,MASTER,TOOL
 SG_ actual_pos : 32|16@1+ (1.52587890625e-05,0) [0|0.9999847412109375] "rev"  NODE14,MASTER,TOOL
 SG_ alive_counter : 48|8@1+ (1,0) [0|255] ""  NODE14,MASTER,TOOL
 SG_ sync_error : 56|8@1- (0.00390625,0) [-0.5|0.49609375] "rev"  NODE14,MASTER,TOOL

BO_ 974 S2_NODE_DIAG_14: 8 NODE14
 SG_ bus_voltage : 0|16@1+ (0.1,0) [0|6553.5] "V"  NODE14,MASTER,TOOL
 SG_ motor_current : 16|16@1- (0.1,0) [-3276.8|3276.7] "A"  NODE14,MASTER,TOOL
 SG_ controller_temp : 32|8@1+ (1,0) [0|255] "C"  NODE14,MASTER,TOOL
 SG_ motor_temp : 40|8@1+ (1,0) [0|255] "C"  NODE14,MASTER,TOOL
 SG_ fault_flags : 48|8@1+ (1,0) [0|255] "bitfield"  NODE14,MASTER,TOOL
 SG_ warning_flags : 56|8@1+ (1,0) [0|255] "bitfield"  NODE14,MASTER,TOOL

BO_ 799 S2_NODE_CMD_15: 8 MASTER
 SG_ node_command : 0|8@1+ (1,0) [0|255] ""  MASTER,TOOL
 SG_ node_flags : 8|8@1+ (1,0) [0|255] "bitfield"  MASTER,TOOL
 SG_ trim_rpm : 16|16@1- (0.1,0) [-3276.8|3276.7] "rpm"  MASTER,TOOL
 SG_ section_mask : 32|16@1+ (1,0) [0|65535] "bitmask"  MASTER,TOOL
 SG_ seq : 48|8@1+ (1,0) [0|255] ""  MASTER,TOOL
 SG_ reserved : 56|8@1+ (1,0) [0|255] ""  MASTER,TOOL

BO_ 847 S2_NODE_PRESENCE_15: 8 NODE15
 SG_ seed_flags : 0|8@1+ (1,0) [0|255] "bitfield"  NODE15,MASTER,TOOL
 SG_ blockage_pct : 8|8@1+ (1,0) [0|100] "%"  NODE15,MASTER,TOOL
 SG_ slowdown_pct : 16|8@1+ (1,0) [0|100] "%"  NODE15,MASTER,TOOL
 SG_ skip_pct : 24|8@1+ (1,0) [0|100] "%"  NODE15,MASTER,TOOL
 SG_ double_pct : 32|8@1+ (1,0) [0|100] "%"  NODE15,MASTER,TOOL
 SG_ singulation_pct : 40|8@1+ (1,0) [0|100] "%"  NODE15,MASTER,TOOL
 SG_ population_x1k : 48|16@1+ (1,0) [0|65535] "x1000"  NODE15,MASTER,TOOL

BO_ 911 S2_NODE_STATUS_FAST_15: 8 NODE15
 SG_ status_flags : 0|8@1+ (1,0) [0|255] "bitfield"  NODE15,MASTER,TOOL
 SG_ error_code : 8|8@1+ (1,0) [0|255] ""  NODE15,MASTER,TOOL
 SG_ actual_rpm : 16|16@1+ (1,0) [0|10000] "rpm"  NODE15,MASTER,TOOL
 SG_ actual_pos : 32|16@1+ (1.52587890625e-05,0) [0|0.9999847412109375] "rev"  NODE15,MASTER,TOOL
 SG_ alive_counter : 48|8@1+ (1,0) [0|255] ""  NODE15,MASTER,TOOL
 SG_ sync_error : 56|8@1- (0.00390625,0) [-0.5|0.49609375] "rev"  NODE15,MASTER,TOOL

BO_ 975 S2_NODE_DIAG_15: 8 NODE15
 SG_ bus_voltage : 0|16@1+ (0.1,0) [0|6553.5] "V"  NODE15,MASTER,TOOL
 SG_ motor_current : 16|16@1- (0.1,0) [-3276.8|3276.7] "A"  NODE15,MASTER,TOOL
 SG_ controller_temp : 32|8@1+ (1,0) [0|255] "C"  NODE15,MASTER,TOOL
 SG_ motor_temp : 40|8@1+ (1,0) [0|255] "C"  NODE15,MASTER,TOOL
 SG_ fault_flags : 48|8@1+ (1,0) [0|255] "bitfield"  NODE15,MASTER,TOOL
 SG_ warning_flags : 56|8@1+ (1,0) [0|255] "bitfield"  NODE15,MASTER,TOOL

BO_ 800 S2_NODE_CMD_16: 8 MASTER
 SG_ node_command : 0|8@1+ (1,0) [0|255] ""  MASTER,TOOL
 SG_ node_flags : 8|8@1+ (1,0) [0|255] "bitfield"  MASTER,TOOL
 SG_ trim_rpm : 16|16@1- (0.1,0) [-3276.8|3276.7] "rpm"  MASTER,TOOL
 SG_ section_mask : 32|16@1+ (1,0) [0|65535] "bitmask"  MASTER,TOOL
 SG_ seq : 48|8@1+ (1,0) [0|255] ""  MASTER,TOOL
 SG_ reserved : 56|8@1+ (1,0) [0|255] ""  MASTER,TOOL

BO_ 848 S2_NODE_PRESENCE_16: 8 NODE16
 SG_ seed_flags : 0|8@1+ (1,0) [0|255] "bitfield"  NODE16,MASTER,TOOL
 SG_ blockage_pct : 8|8@1+ (1,0) [0|100] "%"  NODE16,MASTER,TOOL
 SG_ slowdown_pct : 16|8@1+ (1,0) [0|100] "%"  NODE16,MASTER,TOOL
 SG_ skip_pct : 24|8@1+ (1,0) [0|100] "%"  NODE16,MASTER,TOOL
 SG_ double_pct : 32|8@1+ (1,0) [0|100] "%"  NODE16,MASTER,TOOL
 SG_ singulation_pct : 40|8@1+ (1,0) [0|100] "%"  NODE16,MASTER,TOOL
 SG_ population_x1k : 48|16@1+ (1,0) [0|65535] "x1000"  NODE16,MASTER,TOOL

BO_ 912 S2_NODE_STATUS_FAST_16: 8 NODE16
 SG_ status_flags : 0|8@1+ (1,0) [0|255] "bitfield"  NODE16,MASTER,TOOL
 SG_ error_code : 8|8@1+ (1,0) [0|255] ""  NODE16,MASTER,TOOL
 SG_ actual_rpm : 16|16@1+ (1,0) [0|10000] "rpm"  NODE16,MASTER,TOOL
 SG_ actual_pos : 32|16@1+ (1.52587890625e-05,0) [0|0.9999847412109375] "rev"  NODE16,MASTER,TOOL
 SG_ alive_counter : 48|8@1+ (1,0) [0|255] ""  NODE16,MASTER,TOOL
 SG_ sync_error : 56|8@1- (0.00390625,0) [-0.5|0.49609375] "rev"  NODE16,MASTER,TOOL

BO_ 976 S2_NODE_DIAG_16: 8 NODE16
 SG_ bus_voltage : 0|16@1+ (0.1,0) [0|6553.5] "V"  NODE16,MASTER,TOOL
 SG_ motor_current : 16|16@1- (0.1,0) [-3276.8|3276.7] "A"  NODE16,MASTER,TOOL
 SG_ controller_temp : 32|8@1+ (1,0) [0|255] "C"  NODE16,MASTER,TOOL
 SG_ motor_temp : 40|8@1+ (1,0) [0|255] "C"  NODE16,MASTER,TOOL
 SG_ fault_flags : 48|8@1+ (1,0) [0|255] "bitfield"  NODE16,MASTER,TOOL
 SG_ warning_flags : 56|8@1+ (1,0) [0|255] "bitfield"  NODE16,MASTER,TOOL

BO_ 1024 S3_GLOBAL_CONTROL: 8 MASTER
 SG_ system_mode : 0|8@1+ (1,0) [0|255] ""  MASTER,TOOL
 SG_ control_flags : 8|8@1+ (1,0) [0|255] "bitfield"  MASTER,TOOL
 SG_ ctrl_drive_enable : 8|1@1+ (1,0) [0|1] "bool"  MASTER,TOOL
 SG_ ctrl_sync_enable : 9|1@1+ (1,0) [0|1] "bool"  MASTER,TOOL
 SG_ ctrl_estop : 10|1@1+ (1,0) [0|1] "bool"  MASTER,TOOL
 SG_ ctrl_diag_enable : 11|1@1+ (1,0) [0|1] "bool"  MASTER,TOOL
 SG_ base_rpm : 16|16@1+ (1,0) [0|10000] "rpm"  MASTER,TOOL
 SG_ sync_pos : 32|16@1+ (1.52587890625e-05,0) [0|0.9999847412109375] "rev"  MASTER,TOOL
 SG_ sequence : 48|8@1+ (1,0) [0|255] ""  MASTER,TOOL
 SG_ reserved : 56|8@1+ (1,0) [0|255] ""  MASTER,TOOL

BO_ 1041 S3_NODE_CMD_1: 8 MASTER
 SG_ node_command : 0|8@1+ (1,0) [0|255] ""  MASTER,TOOL
 SG_ node_flags : 8|8@1+ (1,0) [0|255] "bitfield"  MASTER,TOOL
 SG_ trim_rpm : 16|16@1- (0.1,0) [-3276.8|3276.7] "rpm"  MASTER,TOOL
 SG_ section_mask : 32|16@1+ (1,0) [0|65535] "bitmask"  MASTER,TOOL
 SG_ seq : 48|8@1+ (1,0) [0|255] ""  MASTER,TOOL
 SG_ reserved : 56|8@1+ (1,0) [0|255] ""  MASTER,TOOL

BO_ 1089 S3_NODE_PRESENCE_1: 8 NODE1
 SG_ seed_flags : 0|8@1+ (1,0) [0|255] "bitfield"  NODE1,MASTER,TOOL
 SG_ blockage_pct : 8|8@1+ (1,0) [0|100] "%"  NODE1,MASTER,TOOL
 SG_ slowdown_pct : 16|8@1+ (1,0) [0|100] "%"  NODE1,MASTER,TOOL
 SG_ skip_pct : 24|8@1+ (1,0) [0|100] "%"  NODE1,MASTER,TOOL
 SG_ double_pct : 32|8@1+ (1,0) [0|100] "%"  NODE1,MASTER,TOOL
 SG_ singulation_pct : 40|8@1+ (1,0) [0|100] "%"  NODE1,MASTER,TOOL
 SG_ population_x1k : 48|16@1+ (1,0) [0|65535] "x1000"  NODE1,MASTER,TOOL

BO_ 1153 S3_NODE_STATUS_FAST_1: 8 NODE1
 SG_ status_flags : 0|8@1+ (1,0) [0|255] "bitfield"  NODE1,MASTER,TOOL
 SG_ error_code : 8|8@1+ (1,0) [0|255] ""  NODE1,MASTER,TOOL
 SG_ actual_rpm : 16|16@1+ (1,0) [0|10000] "rpm"  NODE1,MASTER,TOOL
 SG_ actual_pos : 32|16@1+ (1.52587890625e-05,0) [0|0.9999847412109375] "rev"  NODE1,MASTER,TOOL
 SG_ alive_counter : 48|8@1+ (1,0) [0|255] ""  NODE1,MASTER,TOOL
 SG_ sync_error : 56|8@1- (0.00390625,0) [-0.5|0.49609375] "rev"  NODE1,MASTER,TOOL

BO_ 1217 S3_NODE_DIAG_1: 8 NODE1
 SG_ bus_voltage : 0|16@1+ (0.1,0) [0|6553.5] "V"  NODE1,MASTER,TOOL
 SG_ motor_current : 16|16@1- (0.1,0) [-3276.8|3276.7] "A"  NODE1,MASTER,TOOL
 SG_ controller_temp : 32|8@1+ (1,0) [0|255] "C"  NODE1,MASTER,TOOL
 SG_ motor_temp : 40|8@1+ (1,0) [0|255] "C"  NODE1,MASTER,TOOL
 SG_ fault_flags : 48|8@1+ (1,0) [0|255] "bitfield"  NODE1,MASTER,TOOL
 SG_ warning_flags : 56|8@1+ (1,0) [0|255] "bitfield"  NODE1,MASTER,TOOL

BO_ 1042 S3_NODE_CMD_2: 8 MASTER
 SG_ node_command : 0|8@1+ (1,0) [0|255] ""  MASTER,TOOL
 SG_ node_flags : 8|8@1+ (1,0) [0|255] "bitfield"  MASTER,TOOL
 SG_ trim_rpm : 16|16@1- (0.1,0) [-3276.8|3276.7] "rpm"  MASTER,TOOL
 SG_ section_mask : 32|16@1+ (1,0) [0|65535] "bitmask"  MASTER,TOOL
 SG_ seq : 48|8@1+ (1,0) [0|255] ""  MASTER,TOOL
 SG_ reserved : 56|8@1+ (1,0) [0|255] ""  MASTER,TOOL

BO_ 1090 S3_NODE_PRESENCE_2: 8 NODE2
 SG_ seed_flags : 0|8@1+ (1,0) [0|255] "bitfield"  NODE2,MASTER,TOOL
 SG_ blockage_pct : 8|8@1+ (1,0) [0|100] "%"  NODE2,MASTER,TOOL
 SG_ slowdown_pct : 16|8@1+ (1,0) [0|100] "%"  NODE2,MASTER,TOOL
 SG_ skip_pct : 24|8@1+ (1,0) [0|100] "%"  NODE2,MASTER,TOOL
 SG_ double_pct : 32|8@1+ (1,0) [0|100] "%"  NODE2,MASTER,TOOL
 SG_ singulation_pct : 40|8@1+ (1,0) [0|100] "%"  NODE2,MASTER,TOOL
 SG_ population_x1k : 48|16@1+ (1,0) [0|65535] "x1000"  NODE2,MASTER,TOOL

BO_ 1154 S3_NODE_STATUS_FAST_2: 8 NODE2
 SG_ status_flags : 0|8@1+ (1,0) [0|255] "bitfield"  NODE2,MASTER,TOOL
 SG_ error_code : 8|8@1+ (1,0) [0|255] ""  NODE2,MASTER,TOOL
 SG_ actual_rpm : 16|16@1+ (1,0) [0|10000] "rpm"  NODE2,MASTER,TOOL
 SG_ actual_pos : 32|16@1+ (1.52587890625e-05,0) [0|0.9999847412109375] "rev"  NODE2,MASTER,TOOL
 SG_ alive_counter : 48|8@1+ (1,0) [0|255] ""  NODE2,MASTER,TOOL
 SG_ sync_error : 56|8@1- (0.00390625,0) [-0.5|0.49609375] "rev"  NODE2,MASTER,TOOL

BO_ 1218 S3_NODE_DIAG_2: 8 NODE2
 SG_ bus_voltage : 0|16@1+ (0.1,0) [0|6553.5] "V"  NODE2,MASTER,TOOL
 SG_ motor_current : 16|16@1- (0.1,0) [-3276.8|3276.7] "A"  NODE2,MASTER,TOOL
 SG_ controller_temp : 32|8@1+ (1,0) [0|255] "C"  NODE2,MASTER,TOOL
 SG_ motor_temp : 40|8@1+ (1,0) [0|255] "C"  NODE2,MASTER,TOOL
 SG_ fault_flags : 48|8@1+ (1,0) [0|255] "bitfield"  NODE2,MASTER,TOOL
 SG_ warning_flags : 56|8@1+ (1,0) [0|255] "bitfield"  NODE2,MASTER,TOOL

BO_ 1043 S3_NODE_CMD_3: 8 MASTER
 SG_ node_command : 0|8@1+ (1,0) [0|255] ""  MASTER,TOOL
 SG_ node_flags : 8|8@1+ (1,0) [0|255] "bitfield"  MASTER,TOOL
 SG_ trim_rpm : 16|16@1- (0.1,0) [-3276.8|3276.7] "rpm"  MASTER,TOOL
 SG_ section_mask : 32|16@1+ (1,0) [0|65535] "bitmask"  MASTER,TOOL
 SG_ seq : 48|8@1+ (1,0) [0|255] ""  MASTER,TOOL
 SG_ reserved : 56|8@1+ (1,0) [0|255] ""  MASTER,TOOL

BO_ 1091 S3_NODE_PRESENCE_3: 8 NODE3
 SG_ seed_flags : 0|8@1+ (1,0) [0|255] "bitfield"  NODE3,MASTER,TOOL
 SG_ blockage_pct : 8|8@1+ (1,0) [0|100] "%"  NODE3,MASTER,TOOL
 SG_ slowdown_pct : 16|8@1+ (1,0) [0|100] "%"  NODE3,MASTER,TOOL
 SG_ skip_pct : 24|8@1+ (1,0) [0|100] "%"  NODE3,MASTER,TOOL
 SG_ double_pct : 32|8@1+ (1,0) [0|100] "%"  NODE3,MASTER,TOOL
 SG_ singulation_pct : 40|8@1+ (1,0) [0|100] "%"  NODE3,MASTER,TOOL
 SG_ population_x1k : 48|16@1+ (1,0) [0|65535] "x1000"  NODE3,MASTER,TOOL

BO_ 1155 S3_NODE_STATUS_FAST_3: 8 NODE3
 SG_ status_flags : 0|8@1+ (1,0) [0|255] "bitfield"  NODE3,MASTER,TOOL
 SG_ error_code : 8|8@1+ (1,0) [0|255] ""  NODE3,MASTER,TOOL
 SG_ actual_rpm : 16|16@1+ (1,0) [0|10000] "rpm"  NODE3,MASTER,TOOL
 SG_ actual_pos : 32|16@1+ (1.52587890625e-05,0) [0|0.9999847412109375] "rev"  NODE3,MASTER,TOOL
 SG_ alive_counter : 48|8@1+ (1,0) [0|255] ""  NODE3,MASTER,TOOL
 SG_ sync_error : 56|8@1- (0.00390625,0) [-0.5|0.49609375] "rev"  NODE3,MASTER,TOOL

BO_ 1219 S3_NODE_DIAG_3: 8 NODE3
 SG_ bus_voltage : 0|16@1+ (0.1,0) [0|6553.5] "V"  NODE3,MASTER,TOOL
 SG_ motor_current : 16|16@1- (0.1,0) [-3276.8|3276.7] "A"  NODE3,MASTER,TOOL
 SG_ controller_temp : 32|8@1+ (1,0) [0|255] "C"  NODE3,MASTER,TOOL
 SG_ motor_temp : 40|8@1+ (1,0) [0|255] "C"  NODE3,MASTER,TOOL
 SG_ fault_flags : 48|8@1+ (1,0) [0|255] "bitfield"  NODE3,MASTER,TOOL
 SG_ warning_flags : 56|8@1+ (1,0) [0|255] "bitfield"  NODE3,MASTER,TOOL

BO_ 1044 S3_NODE_CMD_4: 8 MASTER
 SG_ node_command : 0|8@1+ (1,0) [0|255] ""  MASTER,TOOL
 SG_ node_flags : 8|8@1+ (1,0) [0|255] "bitfield"  MASTER,TOOL
 SG_ trim_rpm : 16|16@1- (0.1,0) [-3276.8|3276.7] "rpm"  MASTER,TOOL
 SG_ section_mask : 32|16@1+ (1,0) [0|65535] "bitmask"  MASTER,TOOL
 SG_ seq : 48|8@1+ (1,0) [0|255] ""  MASTER,TOOL
 SG_ reserved : 56|8@1+ (1,0) [0|255] ""  MASTER,TOOL

BO_ 1092 S3_NODE_PRESENCE_4: 8 NODE4
 SG_ seed_flags : 0|8@1+ (1,0) [0|255] "bitfield"  NODE4,MASTER,TOOL
 SG_ blockage_pct : 8|8@1+ (1,0) [0|100] "%"  NODE4,MASTER,TOOL
 SG_ slowdown_pct : 16|8@1+ (1,0) [0|100] "%"  NODE4,MASTER,TOOL
 SG_ skip_pct : 24|8@1+ (1,0) [0|100] "%"  NODE4,MASTER,TOOL
 SG_ double_pct : 32|8@1+ (1,0) [0|100] "%"  NODE4,MASTER,TOOL
 SG_ singulation_pct : 40|8@1+ (1,0) [0|100] "%"  NODE4,MASTER,TOOL
 SG_ population_x1k : 48|16@1+ (1,0) [0|65535] "x1000"  NODE4,MASTER,TOOL

BO_ 1156 S3_NODE_STATUS_FAST_4: 8 NODE4
 SG_ status_flags : 0|8@1+ (1,0) [0|255] "bitfield"  NODE4,MASTER,TOOL
 SG_ error_code : 8|8@1+ (1,0) [0|255] ""  NODE4,MASTER,TOOL
 SG_ actual_rpm : 16|16@1+ (1,0) [0|10000] "rpm"  NODE4,MASTER,TOOL
 SG_ actual_pos : 32|16@1+ (1.52587890625e-05,0) [0|0.9999847412109375] "rev"  NODE4,MASTER,TOOL
 SG_ alive_counter : 48|8@1+ (1,0) [0|255] ""  NODE4,MASTER,TOOL
 SG_ sync_error : 56|8@1- (0.00390625,0) [-0.5|0.49609375] "rev"  NODE4,MASTER,TOOL

BO_ 1220 S3_NODE_DIAG_4: 8 NODE4
 SG_ bus_voltage : 0|16@1+ (0.1,0) [0|6553.5] "V"  NODE4,MASTER,TOOL
 SG_ motor_current : 16|16@1- (0.1,0) [-3276.8|3276.7] "A"  NODE4,MASTER,TOOL
 SG_ controller_temp : 32|8@1+ (1,0) [0|255] "C"  NODE4,MASTER,TOOL
 SG_ motor_temp : 40|8@1+ (1,0) [0|255] "C"  NODE4,MASTER,TOOL
 SG_ fault_flags : 48|8@1+ (1,0) [0|255] "bitfield"  NODE4,MASTER,TOOL
 SG_ warning_flags : 56|8@1+ (1,0) [0|255] "bitfield"  NODE4,MASTER,TOOL

BO_ 1045 S3_NODE_CMD_5: 8 MASTER
 SG_ node_command : 0|8@1+ (1,0) [0|255] ""  MASTER,TOOL
 SG_ node_flags : 8|8@1+ (1,0) [0|255] "bitfield"  MASTER,TOOL
 SG_ trim_rpm : 16|16@1- (0.1,0) [-3276.8|3276.7] "rpm"  MASTER,TOOL
 SG_ section_mask : 32|16@1+ (1,0) [0|65535] "bitmask"  MASTER,TOOL
 SG_ seq : 48|8@1+ (1,0) [0|255] ""  MASTER,TOOL
 SG_ reserved : 56|8@1+ (1,0) [0|255] ""  MASTER,TOOL

BO_ 1093 S3_NODE_PRESENCE_5: 8 NODE5
 SG_ seed_flags : 0|8@1+ (1,0) [0|255] "bitfield"  NODE5,MASTER,TOOL
 SG_ blockage_pct : 8|8@1+ (1,0) [0|100] "%"  NODE5,MASTER,TOOL
 SG_ slowdown_pct : 16|8@1+ (1,0) [0|100] "%"  NODE5,MASTER,TOOL
 SG_ skip_pct : 24|8@1+ (1,0) [0|100] "%"  NODE5,MASTER,TOOL
 SG_ double_pct : 32|8@1+ (1,0) [0|100] "%"  NODE5,MASTER,TOOL
 SG_ singulation_pct : 40|8@1+ (1,0) [0|100] "%"  NODE5,MASTER,TOOL
 SG_ population_x1k : 48|16@1+ (1,0) [0|65535] "x1000"  NODE5,MASTER,TOOL

BO_ 1157 S3_NODE_STATUS_FAST_5: 8 NODE5
 SG_ status_flags : 0|8@1+ (1,0) [0|255] "bitfield"  NODE5,MASTER,TOOL
 SG_ error_code : 8|8@1+ (1,0) [0|255] ""  NODE5,MASTER,TOOL
 SG_ actual_rpm : 16|16@1+ (1,0) [0|10000] "rpm"  NODE5,MASTER,TOOL
 SG_ actual_pos : 32|16@1+ (1.52587890625e-05,0) [0|0.9999847412109375] "rev"  NODE5,MASTER,TOOL
 SG_ alive_counter : 48|8@1+ (1,0) [0|255] ""  NODE5,MASTER,TOOL
 SG_ sync_error : 56|8@1- (0.00390625,0) [-0.5|0.49609375] "rev"  NODE5,MASTER,TOOL

BO_ 1221 S3_NODE_DIAG_5: 8 NODE5
 SG_ bus_voltage : 0|16@1+ (0.1,0) [0|6553.5] "V"  NODE5,MASTER,TOOL
 SG_ motor_current : 16|16@1- (0.1,0) [-3276.8|3276.7] "A"  NODE5,MASTER,TOOL
 SG_ controller_temp : 32|8@1+ (1,0) [0|255] "C"  NODE5,MASTER,TOOL
 SG_ motor_temp : 40|8@1+ (1,0) [0|255] "C"  NODE5,MASTER,TOOL
 SG_ fault_flags : 48|8@1+ (1,0) [0|255] "bitfield"  NODE5,MASTER,TOOL
 SG_ warning_flags : 56|8@1+ (1,0) [0|255] "bitfield"  NODE5,MASTER,TOOL

BO_ 1046 S3_NODE_CMD_6: 8 MASTER
 SG_ node_command : 0|8@1+ (1,0) [0|255] ""  MASTER,TOOL
 SG_ node_flags : 8|8@1+ (1,0) [0|255] "bitfield"  MASTER,TOOL
 SG_ trim_rpm : 16|16@1- (0.1,0) [-3276.8|3276.7] "rpm"  MASTER,TOOL
 SG_ section_mask : 32|16@1+ (1,0) [0|65535] "bitmask"  MASTER,TOOL
 SG_ seq : 48|8@1+ (1,0) [0|255] ""  MASTER,TOOL
 SG_ reserved : 56|8@1+ (1,0) [0|255] ""  MASTER,TOOL

BO_ 1094 S3_NODE_PRESENCE_6: 8 NODE6
 SG_ seed_flags : 0|8@1+ (1,0) [0|255] "bitfield"  NODE6,MASTER,TOOL
 SG_ blockage_pct : 8|8@1+ (1,0) [0|100] "%"  NODE6,MASTER,TOOL
 SG_ slowdown_pct : 16|8@1+ (1,0) [0|100] "%"  NODE6,MASTER,TOOL
 SG_ skip_pct : 24|8@1+ (1,0) [0|100] "%"  NODE6,MASTER,TOOL
 SG_ double_pct : 32|8@1+ (1,0) [0|100] "%"  NODE6,MASTER,TOOL
 SG_ singulation_pct : 40|8@1+ (1,0) [0|100] "%"  NODE6,MASTER,TOOL
 SG_ population_x1k : 48|16@1+ (1,0) [0|65535] "x1000"  NODE6,MASTER,TOOL

BO_ 1158 S3_NODE_STATUS_FAST_6: 8 NODE6
 SG_ status_flags : 0|8@1+ (1,0) [0|255] "bitfield"  NODE6,MASTER,TOOL
 SG_ error_code : 8|8@1+ (1,0) [0|255] ""  NODE6,MASTER,TOOL
 SG_ actual_rpm : 16|16@1+ (1,0) [0|10000] "rpm"  NODE6,MASTER,TOOL
 SG_ actual_pos : 32|16@1+ (1.52587890625e-05,0) [0|0.9999847412109375] "rev"  NODE6,MASTER,TOOL
 SG_ alive_counter : 48|8@1+ (1,0) [0|255] ""  NODE6,MASTER,TOOL
 SG_ sync_error : 56|8@1- (0.00390625,0) [-0.5|0.49609375] "rev"  NODE6,MASTER,TOOL

BO_ 1222 S3_NODE_DIAG_6: 8 NODE6
 SG_ bus_voltage : 0|16@1+ (0.1,0) [0|6553.5] "V"  NODE6,MASTER,TOOL
 SG_ motor_current : 16|16@1- (0.1,0) [-3276.8|3276.7] "A"  NODE6,MASTER,TOOL
 SG_ controller_temp : 32|8@1+ (1,0) [0|255] "C"  NODE6,MASTER,TOOL
 SG_ motor_temp : 40|8@1+ (1,0) [0|255] "C"  NODE6,MASTER,TOOL
 SG_ fault_flags : 48|8@1+ (1,0) [0|255] "bitfield"  NODE6,MASTER,TOOL
 SG_ warning_flags : 56|8@1+ (1,0) [0|255] "bitfield"  NODE6,MASTER,TOOL

BO_ 1047 S3_NODE_CMD_7: 8 MASTER
 SG_ node_command : 0|8@1+ (1,0) [0|255] ""  MASTER,TOOL
 SG_ node_flags : 8|8@1+ (1,0) [0|255] "bitfield"  MASTER,TOOL
 SG_ trim_rpm : 16|16@1- (0.1,0) [-3276.8|3276.7] "rpm"  MASTER,TOOL
 SG_ section_mask : 32|16@1+ (1,0) [0|65535] "bitmask"  MASTER,TOOL
 SG_ seq : 48|8@1+ (1,0) [0|255] ""  MASTER,TOOL
 SG_ reserved : 56|8@1+ (1,0) [0|255] ""  MASTER,TOOL

BO_ 1095 S3_NODE_PRESENCE_7: 8 NODE7
 SG_ seed_flags : 0|8@1+ (1,0) [0|255] "bitfield"  NODE7,MASTER,TOOL
 SG_ blockage_pct : 8|8@1+ (1,0) [0|100] "%"  NODE7,MASTER,TOOL
 SG_ slowdown_pct : 16|8@1+ (1,0) [0|100] "%"  NODE7,MASTER,TOOL
 SG_ skip_pct : 24|8@1+ (1,0) [0|100] "%"  NODE7,MASTER,TOOL
 SG_ double_pct : 32|8@1+ (1,0) [0|100] "%"  NODE7,MASTER,TOOL
 SG_ singulation_pct : 40|8@1+ (1,0) [0|100] "%"  NODE7,MASTER,TOOL
 SG_ population_x1k : 48|16@1+ (1,0) [0|65535] "x1000"  NODE7,MASTER,TOOL

BO_ 1159 S3_NODE_STATUS_FAST_7: 8 NODE7
 SG_ status_flags : 0|8@1+ (1,0) [0|255] "bitfield"  NODE7,MASTER,TOOL
 SG_ error_code : 8|8@1+ (1,0) [0|255] ""  NODE7,MASTER,TOOL
 SG_ actual_rpm : 16|16@1+ (1,0) [0|10000] "rpm"  NODE7,MASTER,TOOL
 SG_ actual_pos : 32|16@1+ (1.52587890625e-05,0) [0|0.9999847412109375] "rev"  NODE7,MASTER,TOOL
 SG_ alive_counter : 48|8@1+ (1,0) [0|255] ""  NODE7,MASTER,TOOL
 SG_ sync_error : 56|8@1- (0.00390625,0) [-0.5|0.49609375] "rev"  NODE7,MASTER,TOOL

BO_ 1223 S3_NODE_DIAG_7: 8 NODE7
 SG_ bus_voltage : 0|16@1+ (0.1,0) [0|6553.5] "V"  NODE7,MASTER,TOOL
 SG_ motor_current : 16|16@1- (0.1,0) [-3276.8|3276.7] "A"  NODE7,MASTER,TOOL
 SG_ controller_temp : 32|8@1+ (1,0) [0|255] "C"  NODE7,MASTER,TOOL
 SG_ motor_temp : 40|8@1+ (1,0) [0|255] "C"  NODE7,MASTER,TOOL
 SG_ fault_flags : 48|8@1+ (1,0) [0|255] "bitfield"  NODE7,MASTER,TOOL
 SG_ warning_flags : 56|8@1+ (1,0) [0|255] "bitfield"  NODE7,MASTER,TOOL

BO_ 1048 S3_NODE_CMD_8: 8 MASTER
 SG_ node_command : 0|8@1+ (1,0) [0|255] ""  MASTER,TOOL
 SG_ node_flags : 8|8@1+ (1,0) [0|255] "bitfield"  MASTER,TOOL
 SG_ trim_rpm : 16|16@1- (0.1,0) [-3276.8|3276.7] "rpm"  MASTER,TOOL
 SG_ section_mask : 32|16@1+ (1,0) [0|65535] "bitmask"  MASTER,TOOL
 SG_ seq : 48|8@1+ (1,0) [0|255] ""  MASTER,TOOL
 SG_ reserved : 56|8@1+ (1,0) [0|255] ""  MASTER,TOOL

BO_ 1096 S3_NODE_PRESENCE_8: 8 NODE8
 SG_ seed_flags : 0|8@1+ (1,0) [0|255] "bitfield"  NODE8,MASTER,TOOL
 SG_ blockage_pct : 8|8@1+ (1,0) [0|100] "%"  NODE8,MASTER,TOOL
 SG_ slowdown_pct : 16|8@1+ (1,0) [0|100] "%"  NODE8,MASTER,TOOL
 SG_ skip_pct : 24|8@1+ (1,0) [0|100] "%"  NODE8,MASTER,TOOL
 SG_ double_pct : 32|8@1+ (1,0) [0|100] "%"  NODE8,MASTER,TOOL
 SG_ singulation_pct : 40|8@1+ (1,0) [0|100] "%"  NODE8,MASTER,TOOL
 SG_ population_x1k : 48|16@1+ (1,0) [0|65535] "x1000"  NODE8,MASTER,TOOL

BO_ 1160 S3_NODE_STATUS_FAST_8: 8 NODE8
 SG_ status_flags : 0|8@1+ (1,0) [0|255] "bitfield"  NODE8,MASTER,TOOL
 SG_ error_code : 8|8@1+ (1,0) [0|255] ""  NODE8,MASTER,TOOL
 SG_ actual_rpm : 16|16@1+ (1,0) [0|10000] "rpm"  NODE8,MASTER,TOOL
 SG_ actual_pos : 32|16@1+ (1.52587890625e-05,0) [0|0.9999847412109375] "rev"  NODE8,MASTER,TOOL
 SG_ alive_counter : 48|8@1+ (1,0) [0|255] ""  NODE8,MASTER,TOOL
 SG_ sync_error : 56|8@1- (0.00390625,0) [-0.5|0.49609375] "rev"  NODE8,MASTER,TOOL

BO_ 1224 S3_NODE_DIAG_8: 8 NODE8
 SG_ bus_voltage : 0|16@1+ (0.1,0) [0|6553.5] "V"  NODE8,MASTER,TOOL
 SG_ motor_current : 16|16@1- (0.1,0) [-3276.8|3276.7] "A"  NODE8,MASTER,TOOL
 SG_ controller_temp : 32|8@1+ (1,0) [0|255] "C"  NODE8,MASTER,TOOL
 SG_ motor_temp : 40|8@1+ (1,0) [0|255] "C"  NODE8,MASTER,TOOL
 SG_ fault_flags : 48|8@1+ (1,0) [0|255] "bitfield"  NODE8,MASTER,TOOL
 SG_ warning_flags : 56|8@1+ (1,0) [0|255] "bitfield"  NODE8,MASTER,TOOL

BO_ 1049 S3_NODE_CMD_9: 8 MASTER
 SG_ node_command : 0|8@1+ (1,0) [0|255] ""  MASTER,TOOL
 SG_ node_flags : 8|8@1+ (1,0) [0|255] "bitfield"  MASTER,TOOL
 SG_ trim_rpm : 16|16@1- (0.1,0) [-3276.8|3276.7] "rpm"  MASTER,TOOL
 SG_ section_mask : 32|16@1+ (1,0) [0|65535] "bitmask"  MASTER,TOOL
 SG_ seq : 48|8@1+ (1,0) [0|255] ""  MASTER,TOOL
 SG_ reserved : 56|8@1+ (1,0) [0|255] ""  MASTER,TOOL

BO_ 1097 S3_NODE_PRESENCE_9: 8 NODE9
 SG_ seed_flags : 0|8@1+ (1,0) [0|255] "bitfield"  NODE9,MASTER,TOOL
 SG_ blockage_pct : 8|8@1+ (1,0) [0|100] "%"  NODE9,MASTER,TOOL
 SG_ slowdown_pct : 16|8@1+ (1,0) [0|100] "%"  NODE9,MASTER,TOOL
 SG_ skip_pct : 24|8@1+ (1,0) [0|100] "%"  NODE9,MASTER,TOOL
 SG_ double_pct : 32|8@1+ (1,0) [0|100] "%"  NODE9,MASTER,TOOL
 SG_ singulation_pct : 40|8@1+ (1,0) [0|100] "%"  NODE9,MASTER,TOOL
 SG_ population_x1k : 48|16@1+ (1,0) [0|65535] "x1000"  NODE9,MASTER,TOOL

BO_ 1161 S3_NODE_STATUS_FAST_9: 8 NODE9
 SG_ status_flags : 0|8@1+ (1,0) [0|255] "bitfield"  NODE9,MASTER,TOOL
 SG_ error_code : 8|8@1+ (1,0) [0|255] ""  NODE9,MASTER,TOOL
 SG_ actual_rpm : 16|16@1+ (1,0) [0|10000] "rpm"  NODE9,MASTER,TOOL
 SG_ actual_pos : 32|16@1+ (1.52587890625e-05,0) [0|0.9999847412109375] "rev"  NODE9,MASTER,TOOL
 SG_ alive_counter : 48|8@1+ (1,0) [0|255] ""  NODE9,MASTER,TOOL
 SG_ sync_error : 56|8@1- (0.00390625,0) [-0.5|0.49609375] "rev"  NODE9,MASTER,TOOL

BO_ 1225 S3_NODE_DIAG_9: 8 NODE9
 SG_ bus_voltage : 0|16@1+ (0.1,0) [0|6553.5] "V"  NODE9,MASTER,TOOL
 SG_ motor_current : 16|16@1- (0.1,0) [-3276.8|3276.7] "A"  NODE9,MASTER,TOOL
 SG_ controller_temp : 32|8@1+ (1,0) [0|255] "C"  NODE9,MASTER,TOOL
 SG_ motor_temp : 40|8@1+ (1,0) [0|255] "C"  NODE9,MASTER,TOOL
 SG_ fault_flags : 48|8@1+ (1,0) [0|255] "bitfield"  NODE9,MASTER,TOOL
 SG_ warning_flags : 56|8@1+ (1,0) [0|255] "bitfield"  NODE9,MASTER,TOOL

BO_ 1050 S3_NODE_CMD_10: 8 MASTER
 SG_ node_command : 0|8@1+ (1,0) [0|255] ""  MASTER,TOOL
 SG_ node_flags : 8|8@1+ (1,0) [0|255] "bitfield"  MASTER,TOOL
 SG_ trim_rpm : 16|16@1- (0.1,0) [-3276.8|3276.7] "rpm"  MASTER,TOOL
 SG_ section_mask : 32|16@1+ (1,0) [0|65535] "bitmask"  MASTER,TOOL
 SG_ seq : 48|8@1+ (1,0) [0|255] ""  MASTER,TOOL
 SG_ reserved : 56|8@1+ (1,0) [0|255] ""  MASTER,TOOL

BO_ 1098 S3_NODE_PRESENCE_10: 8 NODE10
 SG_ seed_flags : 0|8@1+ (1,0) [0|255] "bitfield"  NODE10,MASTER,TOOL
 SG_ blockage_pct : 8|8@1+ (1,0) [0|100] "%"  NODE10,MASTER,TOOL
 SG_ slowdown_pct : 16|8@1+ (1,0) [0|100] "%"  NODE10,MASTER,TOOL
 SG_ skip_pct : 24|8@1+ (1,0) [0|100] "%"  NODE10,MASTER,TOOL
 SG_ double_pct : 32|8@1+ (1,0) [0|100] "%"  NODE10,MASTER,TOOL
 SG_ singulation_pct : 40|8@1+ (1,0) [0|100] "%"  NODE10,MASTER,TOOL
 SG_ population_x1k : 48|16@1+ (1,0) [0|65535] "x1000"  NODE10,MASTER,TOOL

BO_ 1162 S3_NODE_STATUS_FAST_10: 8 NODE10
 SG_ status_flags : 0|8@1+ (1,0) [0|255] "bitfield"  NODE10,MASTER,TOOL
 SG_ error_code : 8|8@1+ (1,0) [0|255] ""  NODE10,MASTER,TOOL
 SG_ actual_rpm : 16|16@1+ (1,0) [0|10000] "rpm"  NODE10,MASTER,TOOL
 SG_ actual_pos : 32|16@1+ (1.52587890625e-05,0) [0|0.9999847412109375] "rev"  NODE10,MASTER,TOOL
 SG_ alive_counter : 48|8@1+ (1,0) [0|255] ""  NODE10,MASTER,TOOL
 SG_ sync_error : 56|8@1- (0.00390625,0) [-0.5|0.49609375] "rev"  NODE10,MASTER,TOOL

BO_ 1226 S3_NODE_DIAG_10: 8 NODE10
 SG_ bus_voltage : 0|16@1+ (0.1,0) [0|6553.5] "V"  NODE10,MASTER,TOOL
 SG_ motor_current : 16|16@1- (0.1,0) [-3276.8|3276.7] "A"  NODE10,MASTER,TOOL
 SG_ controller_temp : 32|8@1+ (1,0) [0|255] "C"  NODE10,MASTER,TOOL
 SG_ motor_temp : 40|8@1+ (1,0) [0|255] "C"  NODE10,MASTER,TOOL
 SG_ fault_flags : 48|8@1+ (1,0) [0|255] "bitfield"  NODE10,MASTER,TOOL
 SG_ warning_flags : 56|8@1+ (1,0) [0|255] "bitfield"  NODE10,MASTER,TOOL

BO_ 1051 S3_NODE_CMD_11: 8 MASTER
 SG_ node_command : 0|8@1+ (1,0) [0|255] ""  MASTER,TOOL
 SG_ node_flags : 8|8@1+ (1,0) [0|255] "bitfield"  MASTER,TOOL
 SG_ trim_rpm : 16|16@1- (0.1,0) [-3276.8|3276.7] "rpm"  MASTER,TOOL
 SG_ section_mask : 32|16@1+ (1,0) [0|65535] "bitmask"  MASTER,TOOL
 SG_ seq : 48|8@1+ (1,0) [0|255] ""  MASTER,TOOL
 SG_ reserved : 56|8@1+ (1,0) [0|255] ""  MASTER,TOOL

BO_ 1099 S3_NODE_PRESENCE_11: 8 NODE11
 SG_ seed_flags : 0|8@1+ (1,0) [0|255] "bitfield"  NODE11,MASTER,TOOL
 SG_ blockage_pct : 8|8@1+ (1,0) [0|100] "%"  NODE11,MASTER,TOOL
 SG_ slowdown_pct : 16|8@1+ (1,0) [0|100] "%"  NODE11,MASTER,TOOL
 SG_ skip_pct : 24|8@1+ (1,0) [0|100] "%"  NODE11,MASTER,TOOL
 SG_ double_pct : 32|8@1+ (1,0) [0|100] "%"  NODE11,MASTER,TOOL
 SG_ singulation_pct : 40|8@1+ (1,0) [0|100] "%"  NODE11,MASTER,TOOL
 SG_ population_x1k : 48|16@1+ (1,0) [0|65535] "x1000"  NODE11,MASTER,TOOL

BO_ 1163 S3_NODE_STATUS_FAST_11: 8 NODE11
 SG_ status_flags : 0|8@1+ (1,0) [0|255] "bitfield"  NODE11,MASTER,TOOL
 SG_ error_code : 8|8@1+ (1,0) [0|255] ""  NODE11,MASTER,TOOL
 SG_ actual_rpm : 16|16@1+ (1,0) [0|10000] "rpm"  NODE11,MASTER,TOOL
 SG_ actual_pos : 32|16@1+ (1.52587890625e-05,0) [0|0.9999847412109375] "rev"  NODE11,MASTER,TOOL
 SG_ alive_counter : 48|8@1+ (1,0) [0|255] ""  NODE11,MASTER,TOOL
 SG_ sync_error : 56|8@1- (0.00390625,0) [-0.5|0.49609375] "rev"  NODE11,MASTER,TOOL

BO_ 1227 S3_NODE_DIAG_11: 8 NODE11
 SG_ bus_voltage : 0|16@1+ (0.1,0) [0|6553.5] "V"  NODE11,MASTER,TOOL
 SG_ motor_current : 16|16@1- (0.1,0) [-3276.8|3276.7] "A"  NODE11,MASTER,TOOL
 SG_ controller_temp : 32|8@1+ (1,0) [0|255] "C"  NODE11,MASTER,TOOL
 SG_ motor_temp : 40|8@1+ (1,0) [0|255] "C"  NODE11,MASTER,TOOL
 SG_ fault_flags : 48|8@1+ (1,0) [0|255] "bitfield"  NODE11,MASTER,TOOL
 SG_ warning_flags : 56|8@1+ (1,0) [0|255] "bitfield"  NODE11,MASTER,TOOL

BO_ 1052 S3_NODE_CMD_12: 8 MASTER
 SG_ node_command : 0|8@1+ (1,0) [0|255] ""  MASTER,TOOL
 SG_ node_flags : 8|8@1+ (1,0) [0|255] "bitfield"  MASTER,TOOL
 SG_ trim_rpm : 16|16@1- (0.1,0) [-3276.8|3276.7] "rpm"  MASTER,TOOL
 SG_ section_mask : 32|16@1+ (1,0) [0|65535] "bitmask"  MASTER,TOOL
 SG_ seq : 48|8@1+ (1,0) [0|255] ""  MASTER,TOOL
 SG_ reserved : 56|8@1+ (1,0) [0|255] ""  MASTER,TOOL

BO_ 1100 S3_NODE_PRESENCE_12: 8 NODE12
 SG_ seed_flags : 0|8@1+ (1,0) [0|255] "bitfield"  NODE12,MASTER,TOOL
 SG_ blockage_pct : 8|8@1+ (1,0) [0|100] "%"  NODE12,MASTER,TOOL
 SG_ slowdown_pct : 16|8@1+ (1,0) [0|100] "%"  NODE12,MASTER,TOOL
 SG_ skip_pct : 24|8@1+ (1,0) [0|100] "%"  NODE12,MASTER,TOOL
 SG_ double_pct : 32|8@1+ (1,0) [0|100] "%"  NODE12,MASTER,TOOL
 SG_ singulation_pct : 40|8@1+ (1,0) [0|100] "%"  NODE12,MASTER,TOOL
 SG_ population_x1k : 48|16@1+ (1,0) [0|65535] "x1000"  NODE12,MASTER,TOOL

BO_ 1164 S3_NODE_STATUS_FAST_12: 8 NODE12
 SG_ status_flags : 0|8@1+ (1,0) [0|255] "bitfield"  NODE12,MASTER,TOOL
 SG_ error_code : 8|8@1+ (1,0) [0|255] ""  NODE12,MASTER,TOOL
 SG_ actual_rpm : 16|16@1+ (1,0) [0|10000] "rpm"  NODE12,MASTER,TOOL
 SG_ actual_pos : 32|16@1+ (1.52587890625e-05,0) [0|0.9999847412109375] "rev"  NODE12,MASTER,TOOL
 SG_ alive_counter : 48|8@1+ (1,0) [0|255] ""  NODE12,MASTER,TOOL
 SG_ sync_error : 56|8@1- (0.00390625,0) [-0.5|0.49609375] "rev"  NODE12,MASTER,TOOL

BO_ 1228 S3_NODE_DIAG_12: 8 NODE12
 SG_ bus_voltage : 0|16@1+ (0.1,0) [0|6553.5] "V"  NODE12,MASTER,TOOL
 SG_ motor_current : 16|16@1- (0.1,0) [-3276.8|3276.7] "A"  NODE12,MASTER,TOOL
 SG_ controller_temp : 32|8@1+ (1,0) [0|255] "C"  NODE12,MASTER,TOOL
 SG_ motor_temp : 40|8@1+ (1,0) [0|255] "C"  NODE12,MASTER,TOOL
 SG_ fault_flags : 48|8@1+ (1,0) [0|255] "bitfield"  NODE12,MASTER,TOOL
 SG_ warning_flags : 56|8@1+ (1,0) [0|255] "bitfield"  NODE12,MASTER,TOOL

BO_ 1053 S3_NODE_CMD_13: 8 MASTER
 SG_ node_command : 0|8@1+ (1,0) [0|255] ""  MASTER,TOOL
 SG_ node_flags : 8|8@1+ (1,0) [0|255] "bitfield"  MASTER,TOOL
 SG_ trim_rpm : 16|16@1- (0.1,0) [-3276.8|3276.7] "rpm"  MASTER,TOOL
 SG_ section_mask : 32|16@1+ (1,0) [0|65535] "bitmask"  MASTER,TOOL
 SG_ seq : 48|8@1+ (1,0) [0|255] ""  MASTER,TOOL
 SG_ reserved : 56|8@1+ (1,0) [0|255] ""  MASTER,TOOL

BO_ 1101 S3_NODE_PRESENCE_13: 8 NODE13
 SG_ seed_flags : 0|8@1+ (1,0) [0|255] "bitfield"  NODE13,MASTER,TOOL
 SG_ blockage_pct : 8|8@1+ (1,0) [0|100] "%"  NODE13,MASTER,TOOL
 SG_ slowdown_pct : 16|8@1+ (1,0) [0|100] "%"  NODE13,MASTER,TOOL
 SG_ skip_pct : 24|8@1+ (1,0) [0|100] "%"  NODE13,MASTER,TOOL
 SG_ double_pct : 32|8@1+ (1,0) [0|100] "%"  NODE13,MASTER,TOOL
 SG_ singulation_pct : 40|8@1+ (1,0) [0|100] "%"  NODE13,MASTER,TOOL
 SG_ population_x1k : 48|16@1+ (1,0) [0|65535] "x1000"  NODE13,MASTER,TOOL

BO_ 1165 S3_NODE_STATUS_FAST_13: 8 NODE13
 SG_ status_flags : 0|8@1+ (1,0) [0|255] "bitfield"  NODE13,MASTER,TOOL
 SG_ error_code : 8|8@1+ (1,0) [0|255] ""  NODE13,MASTER,TOOL
 SG_ actual_rpm : 16|16@1+ (1,0) [0|10000] "rpm"  NODE13,MASTER,TOOL
 SG_ actual_pos : 32|16@1+ (1.52587890625e-05,0) [0|0.9999847412109375] "rev"  NODE13,MASTER,TOOL
 SG_ alive_counter : 48|8@1+ (1,0) [0|255] ""  NODE13,MASTER,TOOL
 SG_ sync_error : 56|8@1- (0.00390625,0) [-0.5|0.49609375] "rev"  NODE13,MASTER,TOOL

BO_ 1229 S3_NODE_DIAG_13: 8 NODE13
 SG_ bus_voltage : 0|16@1+ (0.1,0) [0|6553.5] "V"  NODE13,MASTER,TOOL
 SG_ motor_current : 16|16@1- (0.1,0) [-3276.8|3276.7] "A"  NODE13,MASTER,TOOL
 SG_ controller_temp : 32|8@1+ (1,0) [0|255] "C"  NODE13,MASTER,TOOL
 SG_ motor_temp : 40|8@1+ (1,0) [0|255] "C"  NODE13,MASTER,TOOL
 SG_ fault_flags : 48|8@1+ (1,0) [0|255] "bitfield"  NODE13,MASTER,TOOL
 SG_ warning_flags : 56|8@1+ (1,0) [0|255] "bitfield"  NODE13,MASTER,TOOL

BO_ 1054 S3_NODE_CMD_14: 8 MASTER
 SG_ node_command : 0|8@1+ (1,0) [0|255] ""  MASTER,TOOL
 SG_ node_flags : 8|8@1+ (1,0) [0|255] "bitfield"  MASTER,TOOL
 SG_ trim_rpm : 16|16@1- (0.1,0) [-3276.8|3276.7] "rpm"  MASTER,TOOL
 SG_ section_mask : 32|16@1+ (1,0) [0|65535] "bitmask"  MASTER,TOOL
 SG_ seq : 48|8@1+ (1,0) [0|255] ""  MASTER,TOOL
 SG_ reserved : 56|8@1+ (1,0) [0|255] ""  MASTER,TOOL

BO_ 1102 S3_NODE_PRESENCE_14: 8 NODE14
 SG_ seed_flags : 0|8@1+ (1,0) [0|255] "bitfield"  NODE14,MASTER,TOOL
 SG_ blockage_pct : 8|8@1+ (1,0) [0|100] "%"  NODE14,MASTER,TOOL
 SG_ slowdown_pct : 16|8@1+ (1,0) [0|100] "%"  NODE14,MASTER,TOOL
 SG_ skip_pct : 24|8@1+ (1,0) [0|100] "%"  NODE14,MASTER,TOOL
 SG_ double_pct : 32|8@1+ (1,0) [0|100] "%"  NODE14,MASTER,TOOL
 SG_ singulation_pct : 40|8@1+ (1,0) [0|100] "%"  NODE14,MASTER,TOOL
 SG_ population_x1k : 48|16@1+ (1,0) [0|65535] "x1000"  NODE14,MASTER,TOOL

BO_ 1166 S3_NODE_STATUS_FAST_14: 8 NODE14
 SG_ status_flags : 0|8@1+ (1,0) [0|255] "bitfield"  NODE14,MASTER,TOOL
 SG_ error_code : 8|8@1+ (1,0) [0|255] ""  NODE14,MASTER,TOOL
 SG_ actual_rpm : 16|16@1+ (1,0) [0|10000] "rpm"  NODE14,MASTER,TOOL
 SG_ actual_pos : 32|16@1+ (1.52587890625e-05,0) [0|0.9999847412109375] "rev"  NODE14,MASTER,TOOL
 SG_ alive_counter : 48|8@1+ (1,0) [0|255] ""  NODE14,MASTER,TOOL
 SG_ sync_error : 56|8@1- (0.00390625,0) [-0.5|0.49609375] "rev"  NODE14,MASTER,TOOL

BO_ 1230 S3_NODE_DIAG_14: 8 NODE14
 SG_ bus_voltage : 0|16@1+ (0.1,0) [0|6553.5] "V"  NODE14,MASTER,TOOL
 SG_ motor_current : 16|16@1- (0.1,0) [-3276.8|3276.7] "A"  NODE14,MASTER,TOOL
 SG_ controller_temp : 32|8@1+ (1,0) [0|255] "C"  NODE14,MASTER,TOOL
 SG_ motor_temp : 40|8@1+ (1,0) [0|255] "C"  NODE14,MASTER,TOOL
 SG_ fault_flags : 48|8@1+ (1,0) [0|255] "bitfield"  NODE14,MASTER,TOOL
 SG_ warning_flags : 56|8@1+ (1,0) [0|255] "bitfield"  NODE14,MASTER,TOOL

BO_ 1055 S3_NODE_CMD_15: 8 MASTER
 SG_ node_command : 0|8@1+ (1,0) [0|255] ""  MASTER,TOOL
 SG_ node_flags : 8|8@1+ (1,0) [0|255] "bitfield"  MASTER,TOOL
 SG_ trim_rpm : 16|16@1- (0.1,0) [-3276.8|3276.7] "rpm"  MASTER,TOOL
 SG_ section_mask : 32|16@1+ (1,0) [0|65535] "bitmask"  MASTER,TOOL
 SG_ seq : 48|8@1+ (1,0) [0|255] ""  MASTER,TOOL
 SG_ reserved : 56|8@1+ (1,0) [0|255] ""  MASTER,TOOL

BO_ 1103 S3_NODE_PRESENCE_15: 8 NODE15
 SG_ seed_flags : 0|8@1+ (1,0) [0|255] "bitfield"  NODE15,MASTER,TOOL
 SG_ blockage_pct : 8|8@1+ (1,0) [0|100] "%"  NODE15,MASTER,TOOL
 SG_ slowdown_pct : 16|8@1+ (1,0) [0|100] "%"  NODE15,MASTER,TOOL
 SG_ skip_pct : 24|8@1+ (1,0) [0|100] "%"  NODE15,MASTER,TOOL
 SG_ double_pct : 32|8@1+ (1,0) [0|100] "%"  NODE15,MASTER,TOOL
 SG_ singulation_pct : 40|8@1+ (1,0) [0|100] "%"  NODE15,MASTER,TOOL
 SG_ population_x1k : 48|16@1+ (1,0) [0|65535] "x1000"  NODE15,MASTER,TOOL

BO_ 1167 S3_NODE_STATUS_FAST_15: 8 NODE15
 SG_ status_flags : 0|8@1+ (1,0) [0|255] "bitfield"  NODE15,MASTER,TOOL
 SG_ error_code : 8|8@1+ (1,0) [0|255] ""  NODE15,MASTER,TOOL
 SG_ actual_rpm : 16|16@1+ (1,0) [0|10000] "rpm"  NODE15,MASTER,TOOL
 SG_ actual_pos : 32|16@1+ (1.52587890625e-05,0) [0|0.9999847412109375] "rev"  NODE15,MASTER,TOOL
 SG_ alive_counter : 48|8@1+ (1,0) [0|255] ""  NODE15,MASTER,TOOL
 SG_ sync_error : 56|8@1- (0.00390625,0) [-0.5|0.49609375] "rev"  NODE15,MASTER,TOOL

BO_ 1231 S3_NODE_DIAG_15: 8 NODE15
 SG_ bus_voltage : 0|16@1+ (0.1,0) [0|6553.5] "V"  NODE15,MASTER,TOOL
 SG_ motor_current : 16|16@1- (0.1,0) [-3276.8|3276.7] "A"  NODE15,MASTER,TOOL
 SG_ controller_temp : 32|8@1+ (1,0) [0|255] "C"  NODE15,MASTER,TOOL
 SG_ motor_temp : 40|8@1+ (1,0) [0|255] "C"  NODE15,MASTER,TOOL
 SG_ fault_flags : 48|8@1+ (1,0) [0|255] "bitfield"  NODE15,MASTER,TOOL
 SG_ warning_flags : 56|8@1+ (1,0) [0|255] "bitfield"  NODE15,MASTER,TOOL

BO_ 1056 S3_NODE_CMD_16: 8 MASTER
 SG_ node_command : 0|8@1+ (1,0) [0|255] ""  MASTER,TOOL
 SG_ node_flags : 8|8@1+ (1,0) [0|255] "bitfield"  MASTER,TOOL
 SG_ trim_rpm : 16|16@1- (0.1,0) [-3276.8|3276.7] "rpm"  MASTER,TOOL
 SG_ section_mask : 32|16@1+ (1,0) [0|65535] "bitmask"  MASTER,TOOL
 SG_ seq : 48|8@1+ (1,0) [0|255] ""  MASTER,TOOL
 SG_ reserved : 56|8@1+ (1,0) [0|255] ""  MASTER,TOOL

BO_ 1104 S3_NODE_PRESENCE_16: 8 NODE16
 SG_ seed_flags : 0|8@1+ (1,0) [0|255] "bitfield"  NODE16,MASTER,TOOL
 SG_ blockage_pct : 8|8@1+ (1,0) [0|100] "%"  NODE16,MASTER,TOOL
 SG_ slowdown_pct : 16|8@1+ (1,0) [0|100] "%"  NODE16,MASTER,TOOL
 SG_ skip_pct : 24|8@1+ (1,0) [0|100] "%"  NODE16,MASTER,TOOL
 SG_ double_pct : 32|8@1+ (1,0) [0|100] "%"  NODE16,MASTER,TOOL
 SG_ singulation_pct : 40|8@1+ (1,0) [0|100] "%"  NODE16,MASTER,TOOL
 SG_ population_x1k : 48|16@1+ (1,0) [0|65535] "x1000"  NODE16,MASTER,TOOL

BO_ 1168 S3_NODE_STATUS_FAST_16: 8 NODE16
 SG_ status_flags : 0|8@1+ (1,0) [0|255] "bitfield"  NODE16,MASTER,TOOL
 SG_ error_code : 8|8@1+ (1,0) [0|255] ""  NODE16,MASTER,TOOL
 SG_ actual_rpm : 16|16@1+ (1,0) [0|10000] "rpm"  NODE16,MASTER,TOOL
 SG_ actual_pos : 32|16@1+ (1.52587890625e-05,0) [0|0.9999847412109375] "rev"  NODE16,MASTER,TOOL
 SG_ alive_counter : 48|8@1+ (1,0) [0|255] ""  NODE16,MASTER,TOOL
 SG_ sync_error : 56|8@1- (0.00390625,0) [-0.5|0.49609375] "rev"  NODE16,MASTER,TOOL

BO_ 1232 S3_NODE_DIAG_16: 8 NODE16
 SG_ bus_voltage : 0|16@1+ (0.1,0) [0|6553.5] "V"  NODE16,MASTER,TOOL
 SG_ motor_current : 16|16@1- (0.1,0) [-3276.8|3276.7] "A"  NODE16,MASTER,TOOL
 SG_ controller_temp : 32|8@1+ (1,0) [0|255] "C"  NODE16,MASTER,TOOL
 SG_ motor_temp : 40|8@1+ (1,0) [0|255] "C"  NODE16,MASTER,TOOL
 SG_ fault_flags : 48|8@1+ (1,0) [0|255] "bitfield"  NODE16,MASTER,TOOL
 SG_ warning_flags : 56|8@1+ (1,0) [0|255] "bitfield"  NODE16,MASTER,TOOL

BO_ 1280 SRV_DISCOVER: 8 MASTER
 SG_ request_type : 0|8@1+ (1,0) [0|255] ""  MASTER,TOOL,NODE1,NODE2,NODE3,NODE4,NODE5,NODE6,NODE7,NODE8,NODE9,NODE10,NODE11,NODE12,NODE13,NODE14,NODE15,NODE16
 SG_ response_delay_slots : 8|8@1+ (1,0) [0|255] ""  MASTER,TOOL,NODE1,NODE2,NODE3,NODE4,NODE5,NODE6,NODE7,NODE8,NODE9,NODE10,NODE11,NODE12,NODE13,NODE14,NODE15,NODE16
 SG_ request_uid : 16|8@1+ (1,0) [0|1] "bool"  MASTER,TOOL,NODE1,NODE2,NODE3,NODE4,NODE5,NODE6,NODE7,NODE8,NODE9,NODE10,NODE11,NODE12,NODE13,NODE14,NODE15,NODE16
 SG_ request_cfg : 24|8@1+ (1,0) [0|1] "bool"  MASTER,TOOL,NODE1,NODE2,NODE3,NODE4,NODE5,NODE6,NODE7,NODE8,NODE9,NODE10,NODE11,NODE12,NODE13,NODE14,NODE15,NODE16
 SG_ reserved : 32|32@1+ (1,0) [0|4294967295] ""  MASTER,TOOL,NODE1,NODE2,NODE3,NODE4,NODE5,NODE6,NODE7,NODE8,NODE9,NODE10,NODE11,NODE12,NODE13,NODE14,NODE15,NODE16

BO_ 1281 SRV_UID_A: 8 NODE1
 SG_ uid32 : 0|32@1+ (1,0) [0|4294967295] ""  NODE1,MASTER,TOOL
 SG_ sensor_channel : 32|8@1+ (1,0) [0|3] ""  NODE1,MASTER,TOOL
 SG_ node_id : 40|8@1+ (1,0) [0|16] ""  NODE1,MASTER,TOOL
 SG_ fw_major : 48|8@1+ (1,0) [0|255] ""  NODE1,MASTER,TOOL
 SG_ fw_minor : 56|8@1+ (1,0) [0|255] ""  NODE1,MASTER,TOOL

BO_ 1282 SRV_UID_B: 8 NODE1
 SG_ uid32_hi : 0|32@1+ (1,0) [0|4294967295] ""  NODE1,MASTER,TOOL
 SG_ hw_rev : 32|8@1+ (1,0) [0|255] ""  NODE1,MASTER,TOOL
 SG_ cap_flags : 40|8@1+ (1,0) [0|255] "bitfield"  NODE1,MASTER,TOOL
 SG_ status_flags : 48|8@1+ (1,0) [0|255] "bitfield"  NODE1,MASTER,TOOL
 SG_ reserved : 56|8@1+ (1,0) [0|255] ""  NODE1,MASTER,TOOL

BO_ 1283 SRV_ASSIGN: 8 MASTER
 SG_ uid32 : 0|32@1+ (1,0) [0|4294967295] ""  MASTER,TOOL,NODE1,NODE2,NODE3,NODE4,NODE5,NODE6,NODE7,NODE8,NODE9,NODE10,NODE11,NODE12,NODE13,NODE14,NODE15,NODE16
 SG_ sensor_channel : 32|8@1+ (1,0) [0|3] ""  MASTER,TOOL,NODE1,NODE2,NODE3,NODE4,NODE5,NODE6,NODE7,NODE8,NODE9,NODE10,NODE11,NODE12,NODE13,NODE14,NODE15,NODE16
 SG_ node_id : 40|8@1+ (1,0) [1|16] ""  MASTER,TOOL,NODE1,NODE2,NODE3,NODE4,NODE5,NODE6,NODE7,NODE8,NODE9,NODE10,NODE11,NODE12,NODE13,NODE14,NODE15,NODE16
 SG_ apply_now : 48|8@1+ (1,0) [0|1] "bool"  MASTER,TOOL,NODE1,NODE2,NODE3,NODE4,NODE5,NODE6,NODE7,NODE8,NODE9,NODE10,NODE11,NODE12,NODE13,NODE14,NODE15,NODE16
 SG_ save_now : 56|8@1+ (1,0) [0|1] "bool"  MASTER,TOOL,NODE1,NODE2,NODE3,NODE4,NODE5,NODE6,NODE7,NODE8,NODE9,NODE10,NODE11,NODE12,NODE13,NODE14,NODE15,NODE16

BO_ 1284 SRV_SAVE_CFG: 8 MASTER
 SG_ uid32 : 0|32@1+ (1,0) [0|4294967295] ""  MASTER,TOOL,NODE1,NODE2,NODE3,NODE4,NODE5,NODE6,NODE7,NODE8,NODE9,NODE10,NODE11,NODE12,NODE13,NODE14,NODE15,NODE16
 SG_ magic : 32|8@1+ (1,0) [0|255] ""  MASTER,TOOL,NODE1,NODE2,NODE3,NODE4,NODE5,NODE6,NODE7,NODE8,NODE9,NODE10,NODE11,NODE12,NODE13,NODE14,NODE15,NODE16
 SG_ scope : 40|8@1+ (1,0) [0|255] ""  MASTER,TOOL,NODE1,NODE2,NODE3,NODE4,NODE5,NODE6,NODE7,NODE8,NODE9,NODE10,NODE11,NODE12,NODE13,NODE14,NODE15,NODE16
 SG_ reserved : 48|16@1+ (1,0) [0|65535] ""  MASTER,TOOL,NODE1,NODE2,NODE3,NODE4,NODE5,NODE6,NODE7,NODE8,NODE9,NODE10,NODE11,NODE12,NODE13,NODE14,NODE15,NODE16

BO_ 1285 SRV_ACK: 8 NODE1
 SG_ uid32 : 0|32@1+ (1,0) [0|4294967295] ""  NODE1,MASTER,TOOL
 SG_ ack_cmd : 32|8@1+ (1,0) [0|255] ""  NODE1,MASTER,TOOL
 SG_ result : 40|8@1+ (1,0) [0|255] ""  NODE1,MASTER,TOOL
 SG_ sensor_channel : 48|8@1+ (1,0) [0|3] ""  NODE1,MASTER,TOOL
 SG_ node_id : 56|8@1+ (1,0) [0|16] ""  NODE1,MASTER,TOOL

BO_ 1286 SRV_TEST_SPIN: 8 MASTER
 SG_ uid32 : 0|32@1+ (1,0) [0|4294967295] ""  MASTER,TOOL,NODE1,NODE2,NODE3,NODE4,NODE5,NODE6,NODE7,NODE8,NODE9,NODE10,NODE11,NODE12,NODE13,NODE14,NODE15,NODE16
 SG_ test_rpm : 32|16@1- (0.1,0) [-3276.8|3276.7] "rpm"  MASTER,TOOL,NODE1,NODE2,NODE3,NODE4,NODE5,NODE6,NODE7,NODE8,NODE9,NODE10,NODE11,NODE12,NODE13,NODE14,NODE15,NODE16
 SG_ duration_s : 48|8@1+ (1,0) [0|255] "s"  MASTER,TOOL,NODE1,NODE2,NODE3,NODE4,NODE5,NODE6,NODE7,NODE8,NODE9,NODE10,NODE11,NODE12,NODE13,NODE14,NODE15,NODE16
 SG_ mode : 56|8@1+ (1,0) [0|255] ""  MASTER,TOOL,NODE1,NODE2,NODE3,NODE4,NODE5,NODE6,NODE7,NODE8,NODE9,NODE10,NODE11,NODE12,NODE13,NODE14,NODE15,NODE16

BO_ 1287 SRV_DIAG_REQ: 8 MASTER
 SG_ uid32 : 0|32@1+ (1,0) [0|4294967295] ""  MASTER,TOOL,NODE1,NODE2,NODE3,NODE4,NODE5,NODE6,NODE7,NODE8,NODE9,NODE10,NODE11,NODE12,NODE13,NODE14,NODE15,NODE16
 SG_ detail_level : 32|8@1+ (1,0) [0|255] ""  MASTER,TOOL,NODE1,NODE2,NODE3,NODE4,NODE5,NODE6,NODE7,NODE8,NODE9,NODE10,NODE11,NODE12,NODE13,NODE14,NODE15,NODE16
 SG_ include_runtime : 40|8@1+ (1,0) [0|1] "bool"  MASTER,TOOL,NODE1,NODE2,NODE3,NODE4,NODE5,NODE6,NODE7,NODE8,NODE9,NODE10,NODE11,NODE12,NODE13,NODE14,NODE15,NODE16
 SG_ include_cfg : 48|8@1+ (1,0) [0|1] "bool"  MASTER,TOOL,NODE1,NODE2,NODE3,NODE4,NODE5,NODE6,NODE7,NODE8,NODE9,NODE10,NODE11,NODE12,NODE13,NODE14,NODE15,NODE16
 SG_ reserved : 56|8@1+ (1,0) [0|255] ""  MASTER,TOOL,NODE1,NODE2,NODE3,NODE4,NODE5,NODE6,NODE7,NODE8,NODE9,NODE10,NODE11,NODE12,NODE13,NODE14,NODE15,NODE16

BO_ 1288 SRV_DIAG_RESP_A: 8 NODE1
 SG_ sensor_channel : 0|8@1+ (1,0) [0|3] ""  NODE1,MASTER,TOOL
 SG_ node_id : 8|8@1+ (1,0) [0|16] ""  NODE1,MASTER,TOOL
 SG_ actual_rpm : 16|16@1+ (1,0) [0|10000] "rpm"  NODE1,MASTER,TOOL
 SG_ actual_pos : 32|16@1+ (1.52587890625e-05,0) [0|0.9999847412109375] "rev"  NODE1,MASTER,TOOL
 SG_ error_code : 48|8@1+ (1,0) [0|255] ""  NODE1,MASTER,TOOL
 SG_ status_flags : 56|8@1+ (1,0) [0|255] "bitfield"  NODE1,MASTER,TOOL

BO_ 1289 SRV_DIAG_RESP_B: 8 NODE1
 SG_ uid32 : 0|32@1+ (1,0) [0|4294967295] ""  NODE1,MASTER,TOOL
 SG_ sync_error : 32|8@1- (0.00390625,0) [-0.5|0.49609375] "rev"  NODE1,MASTER,TOOL
 SG_ alive_counter : 40|8@1+ (1,0) [0|255] ""  NODE1,MASTER,TOOL
 SG_ temp_or_supply : 48|8@1+ (1,0) [0|255] ""  NODE1,MASTER,TOOL
 SG_ reserved : 56|8@1+ (1,0) [0|255] ""  NODE1,MASTER,TOOL

BO_ 1290 SRV_REBOOT: 8 MASTER
 SG_ uid32 : 0|32@1+ (1,0) [0|4294967295] ""  MASTER,TOOL,NODE1,NODE2,NODE3,NODE4,NODE5,NODE6,NODE7,NODE8,NODE9,NODE10,NODE11,NODE12,NODE13,NODE14,NODE15,NODE16
 SG_ magic : 32|8@1+ (1,0) [0|255] ""  MASTER,TOOL,NODE1,NODE2,NODE3,NODE4,NODE5,NODE6,NODE7,NODE8,NODE9,NODE10,NODE11,NODE12,NODE13,NODE14,NODE15,NODE16
 SG_ reserved : 40|24@1+ (1,0) [0|16777215] ""  MASTER,TOOL,NODE1,NODE2,NODE3,NODE4,NODE5,NODE6,NODE7,NODE8,NODE9,NODE10,NODE11,NODE12,NODE13,NODE14,NODE15,NODE16

BO_ 1291 SRV_IDENTIFY: 8 MASTER
 SG_ uid32 : 0|32@1+ (1,0) [0|4294967295] ""  MASTER,TOOL,NODE1,NODE2,NODE3,NODE4,NODE5,NODE6,NODE7,NODE8,NODE9,NODE10,NODE11,NODE12,NODE13,NODE14,NODE15,NODE16
 SG_ mode : 32|8@1+ (1,0) [0|255] ""  MASTER,TOOL,NODE1,NODE2,NODE3,NODE4,NODE5,NODE6,NODE7,NODE8,NODE9,NODE10,NODE11,NODE12,NODE13,NODE14,NODE15,NODE16
 SG_ duration_s : 40|8@1+ (1,0) [0|255] "s"  MASTER,TOOL,NODE1,NODE2,NODE3,NODE4,NODE5,NODE6,NODE7,NODE8,NODE9,NODE10,NODE11,NODE12,NODE13,NODE14,NODE15,NODE16
 SG_ reserved : 48|16@1+ (1,0) [0|65535] ""  MASTER,TOOL,NODE1,NODE2,NODE3,NODE4,NODE5,NODE6,NODE7,NODE8,NODE9,NODE10,NODE11,NODE12,NODE13,NODE14,NODE15,NODE16

BO_ 1292 SRV_CFG_READ: 8 MASTER
 SG_ uid32 : 0|32@1+ (1,0) [0|4294967295] ""  MASTER,TOOL,NODE1,NODE2,NODE3,NODE4,NODE5,NODE6,NODE7,NODE8,NODE9,NODE10,NODE11,NODE12,NODE13,NODE14,NODE15,NODE16
 SG_ block_id : 32|8@1+ (1,0) [0|255] ""  MASTER,TOOL,NODE1,NODE2,NODE3,NODE4,NODE5,NODE6,NODE7,NODE8,NODE9,NODE10,NODE11,NODE12,NODE13,NODE14,NODE15,NODE16
 SG_ reserved : 40|24@1+ (1,0) [0|16777215] ""  MASTER,TOOL,NODE1,NODE2,NODE3,NODE4,NODE5,NODE6,NODE7,NODE8,NODE9,NODE10,NODE11,NODE12,NODE13,NODE14,NODE15,NODE16

BO_ 1293 SRV_CFG_RESP: 8 NODE1
 SG_ block_id : 0|8@1+ (1,0) [0|255] ""  NODE1,MASTER,TOOL
 SG_ node_id : 8|8@1+ (1,0) [0|16] ""  NODE1,MASTER,TOOL
 SG_ data_0 : 16|8@1+ (1,0) [0|255] ""  NODE1,MASTER,TOOL
 SG_ data_1 : 24|8@1+ (1,0) [0|255] ""  NODE1,MASTER,TOOL
 SG_ data_2 : 32|8@1+ (1,0) [0|255] ""  NODE1,MASTER,TOOL
 SG_ data_3 : 40|8@1+ (1,0) [0|255] ""  NODE1,MASTER,TOOL
 SG_ data_4 : 48|8@1+ (1,0) [0|255] ""  NODE1,MASTER,TOOL
 SG_ data_5 : 56|8@1+ (1,0) [0|255] ""  NODE1,MASTER,TOOL

BO_ 1294 SRV_SET_CAN_SOURCE: 8 MASTER
 SG_ uid32 : 0|32@1+ (1,0) [0|4294967295] ""  MASTER,TOOL,NODE1,NODE2,NODE3,NODE4,NODE5,NODE6,NODE7,NODE8,NODE9,NODE10,NODE11,NODE12,NODE13,NODE14,NODE15,NODE16
 SG_ sensor_channel : 32|8@1+ (1,0) [0|3] ""  MASTER,TOOL,NODE1,NODE2,NODE3,NODE4,NODE5,NODE6,NODE7,NODE8,NODE9,NODE10,NODE11,NODE12,NODE13,NODE14,NODE15,NODE16
 SG_ node_id : 40|8@1+ (1,0) [0|16] ""  MASTER,TOOL,NODE1,NODE2,NODE3,NODE4,NODE5,NODE6,NODE7,NODE8,NODE9,NODE10,NODE11,NODE12,NODE13,NODE14,NODE15,NODE16
 SG_ can_profile_index : 48|8@1+ (1,0) [0|3] ""  MASTER,TOOL,NODE1,NODE2,NODE3,NODE4,NODE5,NODE6,NODE7,NODE8,NODE9,NODE10,NODE11,NODE12,NODE13,NODE14,NODE15,NODE16
 SG_ save_now : 56|8@1+ (1,0) [0|1] "bool"  MASTER,TOOL,NODE1,NODE2,NODE3,NODE4,NODE5,NODE6,NODE7,NODE8,NODE9,NODE10,NODE11,NODE12,NODE13,NODE14,NODE15,NODE16

VAL_ 1280 request_type 1 "discover";
VAL_ 1285 result 0 "OK" 1 "unknown_command" 2 "bad_payload" 3 "wrong_uid" 4 "busy" 5 "save_failed" 6 "not_supported";
VAL_ 1291 mode 0 "LED_blink" 1 "short_jog";
